VERSION "dbc-export 1 2026.26.6.5"

NS_ :

BS_:

BU_: APP APS BMS CC CMP CMPD CP DAS DI DIF DIR EPBL EPBR EVSE FC GTW HCML HCMR HVP ICR PCS PCS2 PLG PM PMF PMR PTC SCCM SCM SCS SDCR TAS UMC V2G VC VCBATT VCBATT0 VCBATT1 VCBATT2 VCFRONT VCFRONT1 VCFRONT2 VCLEFT VCRIGHT VCSEAT2L VCSEAT2R VCSEC

BO_ 963 VCRIGHT_switchStatus: 8 VCRIGHT
 SG_ VCRIGHT_switchStatusIndex M : 0|1@1+ (1,0) [0|1] "" Vector__XXX
 SG_ VCRIGHT_btnWindowUpRF : 24|1@1+ (1,0) [0|1] "" Vector__XXX
 SG_ VCRIGHT_btnWindowAutoUpRF : 25|1@1+ (1,0) [0|1] "" Vector__XXX
 SG_ VCRIGHT_btnWindowDownRF : 26|1@1+ (1,0) [0|1] "" Vector__XXX
 SG_ VCRIGHT_btnWindowAutoDownRF : 27|1@1+ (1,0) [0|1] "" Vector__XXX
 SG_ VCRIGHT_btnWindowUpRR : 28|1@1+ (1,0) [0|1] "" Vector__XXX
 SG_ VCRIGHT_btnWindowAutoUpRR : 29|1@1+ (1,0) [0|1] "" Vector__XXX
 SG_ VCRIGHT_btnWindowDownRR : 30|1@1+ (1,0) [0|1] "" Vector__XXX
 SG_ VCRIGHT_btnWindowAutoDownRR : 31|1@1+ (1,0) [0|1] "" Vector__XXX
 SG_ VCRIGHT_btnWindowSwPackUpLF : 32|1@1+ (1,0) [0|1] "" Vector__XXX
 SG_ VCRIGHT_btnWindowSwPackAutoUpLF : 33|1@1+ (1,0) [0|1] "" Vector__XXX
 SG_ VCRIGHT_btnWindowSwPackDownLF : 34|1@1+ (1,0) [0|1] "" Vector__XXX
 SG_ VCRIGHT_btnWindowSwPackAutoDwnLF : 35|1@1+ (1,0) [0|1] "" Vector__XXX
 SG_ VCRIGHT_btnWindowSwPackUpLR : 36|1@1+ (1,0) [0|1] "" Vector__XXX
 SG_ VCRIGHT_btnWindowSwPackAutoUpLR : 37|1@1+ (1,0) [0|1] "" Vector__XXX
 SG_ VCRIGHT_btnWindowSwPackDownLR : 38|1@1+ (1,0) [0|1] "" Vector__XXX
 SG_ VCRIGHT_btnWindowSwPackAutoDwnLR : 39|1@1+ (1,0) [0|1] "" Vector__XXX
 SG_ VCRIGHT_frontOccupancySwitch : 42|2@1+ (1,0) [0|3] "" Vector__XXX
 SG_ VCRIGHT_trunkExtReleasePressed : 48|1@1+ (1,0) [0|1] "" Vector__XXX
 SG_ VCRIGHT_btnWindowSwPackUpRR : 49|1@1+ (1,0) [0|1] "" Vector__XXX
 SG_ VCRIGHT_btnWindowSwPackAutoUpRR : 50|1@1+ (1,0) [0|1] "" Vector__XXX
 SG_ VCRIGHT_btnWindowSwPackDownRR : 51|1@1+ (1,0) [0|1] "" Vector__XXX
 SG_ VCRIGHT_btnWindowSwPackAutoDwnRR : 52|1@1+ (1,0) [0|1] "" Vector__XXX
 SG_ VCRIGHT_frontBuckleSwitch m0 : 40|2@1+ (1,0) [0|3] "" Vector__XXX
 SG_ VCRIGHT_rearCenterBuckleSwitch m0 : 44|2@1+ (1,0) [0|3] "" Vector__XXX
 SG_ VCRIGHT_rearRightBuckleSwitch m0 : 46|2@1+ (1,0) [0|3] "" Vector__XXX
 SG_ VCRIGHT_trunkExtReleasePressedPe m1 : 1|1@1+ (1,0) [0|1] "" Vector__XXX
 SG_ VCRIGHT_frontSeatTrackBack m1 : 2|2@1+ (1,0) [1|3] "" Vector__XXX
 SG_ VCRIGHT_frontSeatTrackForward m1 : 4|2@1+ (1,0) [1|3] "" Vector__XXX
 SG_ VCRIGHT_frontSeatTiltDown m1 : 6|2@1+ (1,0) [1|3] "" Vector__XXX
 SG_ VCRIGHT_frontSeatTiltUp m1 : 8|2@1+ (1,0) [1|3] "" Vector__XXX
 SG_ VCRIGHT_frontSeatLiftDown m1 : 10|2@1+ (1,0) [1|3] "" Vector__XXX
 SG_ VCRIGHT_frontSeatLiftUp m1 : 12|2@1+ (1,0) [1|3] "" Vector__XXX
 SG_ VCRIGHT_frontSeatBackrestBack m1 : 14|2@1+ (1,0) [1|3] "" Vector__XXX
 SG_ VCRIGHT_frontSeatBackrestForward m1 : 16|2@1+ (1,0) [1|3] "" Vector__XXX
 SG_ VCRIGHT_frontSeatLumbarDown m1 : 18|2@1+ (1,0) [1|3] "" Vector__XXX
 SG_ VCRIGHT_frontSeatLumbarUp m1 : 20|2@1+ (1,0) [1|3] "" Vector__XXX
 SG_ VCRIGHT_frontSeatLumbarIn m1 : 22|2@1+ (1,0) [1|3] "" Vector__XXX
 SG_ VCRIGHT_frontSeatResistiveOccupa m1 : 54|2@1+ (1,0) [1|3] "" Vector__XXX
 SG_ VCRIGHT_2RowSeatReclineSwitchpac m1 : 56|3@1+ (1,0) [0|7] "" Vector__XXX
 SG_ VCRIGHT_hvacHeatingAllowedRight m1 : 59|1@1+ (1,0) [0|1] "" Vector__XXX
 SG_ VCRIGHT_frontSeatThighSupportRet m1 : 60|2@1+ (1,0) [1|3] "" Vector__XXX

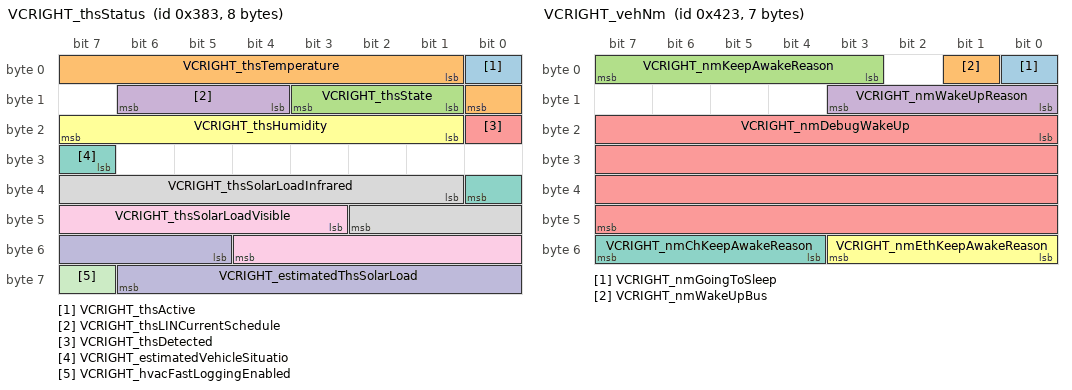
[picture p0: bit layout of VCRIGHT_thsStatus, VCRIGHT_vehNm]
BO_ 899 VCRIGHT_thsStatus: 8 VCRIGHT
 SG_ VCRIGHT_thsActive : 0|1@1+ (1,0) [0|1] "" Vector__XXX
 SG_ VCRIGHT_thsTemperature : 1|8@1+ (1,-40) [-40|150] "degC" Vector__XXX
 SG_ VCRIGHT_thsState : 9|3@1+ (1,0) [0|7] "" Vector__XXX
 SG_ VCRIGHT_thsLINCurrentSchedule : 12|3@1+ (1,0) [0|7] "" Vector__XXX
 SG_ VCRIGHT_thsDetected : 16|1@1+ (1,0) [0|1] "" Vector__XXX
 SG_ VCRIGHT_thsHumidity : 17|7@1+ (1,0) [0|100] "%" Vector__XXX
 SG_ VCRIGHT_estimatedVehicleSituatio : 31|2@1+ (1,0) [0|3] "" Vector__XXX
 SG_ VCRIGHT_thsSolarLoadInfrared : 33|10@1+ (2,0) [0|2044] "W/m2" Vector__XXX
 SG_ VCRIGHT_thsSolarLoadVisible : 43|10@1+ (2,0) [0|2044] "W/m2" Vector__XXX
 SG_ VCRIGHT_estimatedThsSolarLoad : 53|10@1+ (1,0) [0|1022] "W/m2" Vector__XXX
 SG_ VCRIGHT_hvacFastLoggingEnabled : 63|1@1+ (1,0) [0|1] "" Vector__XXX

BO_ 1545 VCRIGHT_udsResponse: 8 VCRIGHT
 SG_ VCRIGHT_udsResponseData_H : 7|32@0+ (1,0) [0|4294967295] "" Vector__XXX
 SG_ VCRIGHT_udsResponseData_L : 39|32@0+ (1,0) [0|4294967295] "" Vector__XXX

BO_ 1059 VCRIGHT_vehNm: 7 VCRIGHT
 SG_ VCRIGHT_nmGoingToSleep : 0|1@1+ (1,0) [0|1] "" Vector__XXX
 SG_ VCRIGHT_nmWakeUpBus : 1|1@1+ (1,0) [0|1] "" Vector__XXX
 SG_ VCRIGHT_nmKeepAwakeReason : 3|5@1+ (1,0) [1|31] "" Vector__XXX
 SG_ VCRIGHT_nmWakeUpReason : 8|4@1+ (1,0) [0|15] "" Vector__XXX
 SG_ VCRIGHT_nmDebugWakeUp : 16|32@1+ (1,0) [0|4294967295] "" Vector__XXX
 SG_ VCRIGHT_nmEthKeepAwakeReason : 48|4@1+ (1,0) [1|15] "" Vector__XXX
 SG_ VCRIGHT_nmChKeepAwakeReason : 52|4@1+ (1,0) [1|15] "" Vector__XXX

BO_ 707 VCRIGHT_windowStatus: 8 VCRIGHT
 SG_ VCRIGHT_windowStatusIndex M : 0|1@1+ (1,0) [0|1] "" Vector__XXX
 SG_ VCRIGHT_windowStateRF m0 : 1|4@1+ (1,0) [0|15] "" Vector__XXX
 SG_ VCRIGHT_windowTrimClearMoveReque m0 : 5|2@1+ (1,0) [0|3] "" Vector__XXX
 SG_ VCRIGHT_windowDutyRF m0 : 8|6@1- (5,0) [-100|100] "%" Vector__XXX
 SG_ VCRIGHT_windowTrimClearActiveReq m0 : 14|2@1+ (1,0) [1|3] "" Vector__XXX
 SG_ VCRIGHT_windowCurrentRF m0 : 16|6@1- (0.5,0) [-15|15] "A" Vector__XXX
 SG_ VCRIGHT_windowPositionRF m0 : 22|9@1- (1.25,265) [-50|580] "mm" Vector__XXX
 SG_ VCRIGHT_windowCalibratedRF m0 : 32|1@1+ (1,0) [0|1] "" Vector__XXX
 SG_ VCRIGHT_windowStateRR m0 : 33|4@1+ (1,0) [0|15] "" Vector__XXX
 SG_ VCRIGHT_windowDutyRR m0 : 40|6@1- (5,0) [-100|100] "%" Vector__XXX
 SG_ VCRIGHT_windowCurrentRR m0 : 48|6@1- (0.5,0) [-15|15] "A" Vector__XXX
 SG_ VCRIGHT_windowPositionRR m0 : 54|9@1- (1.25,265) [-50|580] "mm" Vector__XXX
 SG_ VCRIGHT_windowCalibratedRR m0 : 63|1@1+ (1,0) [0|1] "" Vector__XXX
 SG_ VCRIGHT_windowThermalTCRF m1 : 1|8@1+ (1,0) [0|255] "s" Vector__XXX
 SG_ VCRIGHT_windowThermalModeRF m1 : 9|2@1+ (1,0) [1|3] "" Vector__XXX
 SG_ VCRIGHT_windowStopReasonRF m1 : 11|3@1+ (1,0) [0|7] "" Vector__XXX
 SG_ VCRIGHT_windowStopReqReasonRF m1 : 14|4@1+ (1,0) [0|15] "" Vector__XXX
 SG_ VCRIGHT_windowThermalTCRR m1 : 18|8@1+ (1,0) [0|255] "s" Vector__XXX
 SG_ VCRIGHT_windowThermalModeRR m1 : 26|2@1+ (1,0) [1|3] "" Vector__XXX
 SG_ VCRIGHT_windowStopReasonRR m1 : 28|3@1+ (1,0) [0|7] "" Vector__XXX
 SG_ VCRIGHT_windowStopReqReasonRR m1 : 31|4@1+ (1,0) [0|15] "" Vector__XXX
 SG_ VCRIGHT_windowControlStateRF m1 : 35|2@1+ (1,0) [0|3] "" Vector__XXX
 SG_ VCRIGHT_windowCtrlUnavailableRF m1 : 38|3@1+ (1,0) [0|7] "" Vector__XXX
 SG_ VCRIGHT_windowControlStateRR m1 : 42|2@1+ (1,0) [0|3] "" Vector__XXX
 SG_ VCRIGHT_windowCtrlUnavailableRR m1 : 45|3@1+ (1,0) [0|7] "" Vector__XXX
 SG_ VCRIGHT_windowPositionStateRF m1 : 49|3@1+ (1,0) [0|7] "" Vector__XXX
 SG_ VCRIGHT_windowPositionStateRR m1 : 52|3@1+ (1,0) [0|7] "" Vector__XXX
 SG_ VCRIGHT_windowVehGearStateRF m1 : 56|2@1+ (1,0) [1|3] "" Vector__XXX
 SG_ VCRIGHT_windowVehGearStateRR m1 : 58|2@1+ (1,0) [1|3] "" Vector__XXX
 SG_ VCRIGHT_windowSpeedTableStatusRF m1 : 60|2@1+ (1,0) [1|3] "" Vector__XXX
 SG_ VCRIGHT_windowSpeedTableStatusRR m1 : 62|2@1+ (1,0) [1|3] "" Vector__XXX

BO_ 1375 VCSEAT2L_alertLog: 8 VCSEAT2L
 SG_ VCSEAT2L_alertID M : 0|15@1+ (1,0) [0|32767] "" Vector__XXX
 SG_ VCSEAT2L_alertState : 15|1@1+ (1,0) [0|1] "" Vector__XXX
 SG_ VCSEAT2L_a001_InternalWatchdog m1 : 16|1@1+ (1,0) [0|1] "" Vector__XXX
 SG_ VCSEAT2L_a010_UnderVoltDetected m10 : 16|1@1+ (1,0) [0|1] "" Vector__XXX
 SG_ VCSEAT2L_a010_UnderVoltTimeout m10 : 17|1@1+ (1,0) [0|1] "" Vector__XXX
 SG_ VCSEAT2L_a015_NVMMMemOverflow m15 : 16|1@1+ (1,0) [0|1] "" Vector__XXX
 SG_ VCSEAT2L_a015_NVMMFilesystemErro m15 : 17|1@1+ (1,0) [0|1] "" Vector__XXX
 SG_ VCSEAT2L_a015_NVMMRecordIDError m15 : 18|1@1+ (1,0) [0|1] "" Vector__XXX
 SG_ VCSEAT2L_a057_VEH_cpControl m57 : 16|1@1+ (1,0) [0|1] "" Vector__XXX
 SG_ VCSEAT2L_a059_voltageDrop m59 : 16|12@1+ (0.005443676,0) [0|22.29185322] "V" Vector__XXX
 SG_ VCSEAT2L_a059_resistanceEstimate m59 : 28|12@1+ (0.00244,0) [0|9.9918] "Ohms" Vector__XXX
 SG_ VCSEAT2L_a059_current m59 : 40|12@1+ (0.05,0) [0|204.75] "A" Vector__XXX
 SG_ VCSEAT2L_a063_switchChannel m63 : 16|8@1+ (1,0) [0|255] "" Vector__XXX
 SG_ VCSEAT2L_a063_switchType m63 : 24|8@1+ (1,0) [0|255] "" Vector__XXX
 SG_ VCSEAT2L_a063_ADCVoltage m63 : 32|8@1+ (0.025,0) [0|6.375] "V" Vector__XXX
 SG_ VCSEAT2L_a063_disconnected m63 : 40|1@1+ (1,0) [0|1] "" Vector__XXX
 SG_ VCSEAT2L_a063_indeterminate m63 : 41|1@1+ (1,0) [0|1] "" Vector__XXX
 SG_ VCSEAT2L_a063_stuckActive m63 : 42|1@1+ (1,0) [0|1] "" Vector__XXX
 SG_ VCSEAT2L_a063_faulted m63 : 43|1@1+ (1,0) [0|1] "" Vector__XXX
 SG_ VCSEAT2L_a082_RIPC_epbPrivateSta m82 : 16|1@1+ (1,0) [0|1] "" Vector__XXX
 SG_ VCSEAT2L_a082_RIPC_remoteHSD m82 : 17|1@1+ (1,0) [0|1] "" Vector__XXX
 SG_ VCSEAT2L_a082_RIPC_railStatus m82 : 18|1@1+ (1,0) [0|1] "" Vector__XXX
 SG_ VCSEAT2L_a082_RIPC_remoteMux m82 : 19|1@1+ (1,0) [0|1] "" Vector__XXX
 SG_ VCSEAT2L_a083_LIPC_epbPrivateSta m83 : 16|1@1+ (1,0) [0|1] "" Vector__XXX
 SG_ VCSEAT2L_a083_LIPC_remoteHSD m83 : 17|1@1+ (1,0) [0|1] "" Vector__XXX
 SG_ VCSEAT2L_a083_LIPC_railStatus m83 : 18|1@1+ (1,0) [0|1] "" Vector__XXX
 SG_ VCSEAT2L_a083_LIPC_HSDFaults m83 : 19|1@1+ (1,0) [0|1] "" Vector__XXX
 SG_ VCSEAT2L_a084_CH_StatusC m84 : 16|1@1+ (1,0) [0|1] "" Vector__XXX
 SG_ VCSEAT2L_a085_PARTY_buttonStatus m85 : 16|1@1+ (1,0) [0|1] "" Vector__XXX
 SG_ VCSEAT2L_a086_VEH_LVBMS_statusHi m86 : 16|1@1+ (1,0) [0|1] "" Vector__XXX
 SG_ VCSEAT2L_a086_VEH_LVBMS_statusLo m86 : 17|1@1+ (1,0) [0|1] "" Vector__XXX
 SG_ VCSEAT2L_a086_VEH_status m86 : 18|1@1+ (1,0) [0|1] "" Vector__XXX
 SG_ VCSEAT2L_a086_VEH_12VBatteryStat m86 : 19|1@1+ (1,0) [0|1] "" Vector__XXX
 SG_ VCSEAT2L_a086_VEH_LVPowerState m86 : 20|1@1+ (1,0) [0|1] "" Vector__XXX
 SG_ VCSEAT2L_a086_VEH_lightStatus m86 : 21|1@1+ (1,0) [0|1] "" Vector__XXX
 SG_ VCSEAT2L_a086_VEH_systemStatus m86 : 22|1@1+ (1,0) [0|1] "" Vector__XXX
 SG_ VCSEAT2L_a086_VEH_thermalStatus m86 : 23|1@1+ (1,0) [0|1] "" Vector__XXX
 SG_ VCSEAT2L_a086_VEH_vehNm m86 : 24|1@1+ (1,0) [0|1] "" Vector__XXX
 SG_ VCSEAT2L_a087_VEH_temperature m87 : 16|1@1+ (1,0) [0|1] "" Vector__XXX
 SG_ VCSEAT2L_a087_VEH_thermalControl m87 : 17|1@1+ (1,0) [0|1] "" Vector__XXX
 SG_ VCSEAT2L_a087_VEH_torque m87 : 18|1@1+ (1,0) [0|1] "" Vector__XXX
 SG_ VCSEAT2L_a087_VEH_status m87 : 19|1@1+ (1,0) [0|1] "" Vector__XXX
 SG_ VCSEAT2L_a087_PARTY_torque m87 : 20|1@1+ (1,0) [0|1] "" Vector__XXX
 SG_ VCSEAT2L_a087_PARTY_status m87 : 21|1@1+ (1,0) [0|1] "" Vector__XXX
 SG_ VCSEAT2L_a087_PARTY_temperature m87 : 22|1@1+ (1,0) [0|1] "" Vector__XXX
 SG_ VCSEAT2L_a087_PARTY_thermalContr m87 : 23|1@1+ (1,0) [0|1] "" Vector__XXX
 SG_ VCSEAT2L_a087_VEH_motorStatus m87 : 24|1@1+ (1,0) [0|1] "" Vector__XXX
 SG_ VCSEAT2L_a088_VEH_temperature m88 : 16|1@1+ (1,0) [0|1] "" Vector__XXX
 SG_ VCSEAT2L_a088_VEH_thermalControl m88 : 17|1@1+ (1,0) [0|1] "" Vector__XXX
 SG_ VCSEAT2L_a088_VEH_torque m88 : 18|1@1+ (1,0) [0|1] "" Vector__XXX
 SG_ VCSEAT2L_a088_VEH_status m88 : 19|1@1+ (1,0) [0|1] "" Vector__XXX
 SG_ VCSEAT2L_a088_PARTY_torque m88 : 20|1@1+ (1,0) [0|1] "" Vector__XXX
 SG_ VCSEAT2L_a088_PARTY_status m88 : 21|1@1+ (1,0) [0|1] "" Vector__XXX
 SG_ VCSEAT2L_a088_PARTY_temperature m88 : 22|1@1+ (1,0) [0|1] "" Vector__XXX
 SG_ VCSEAT2L_a088_PARTY_thermalContr m88 : 23|1@1+ (1,0) [0|1] "" Vector__XXX
 SG_ VCSEAT2L_a088_VEH_motorStatus m88 : 24|1@1+ (1,0) [0|1] "" Vector__XXX
 SG_ VCSEAT2L_a089_PARTY_party1 m89 : 16|1@1+ (1,0) [0|1] "" Vector__XXX
 SG_ VCSEAT2L_a089_PARTY_status m89 : 17|1@1+ (1,0) [0|1] "" Vector__XXX
 SG_ VCSEAT2L_a089_VEH_status m89 : 18|1@1+ (1,0) [0|1] "" Vector__XXX
 SG_ VCSEAT2L_a089_BDY_party1 m89 : 19|1@1+ (1,0) [0|1] "" Vector__XXX
 SG_ VCSEAT2L_a089_BDY_status m89 : 20|1@1+ (1,0) [0|1] "" Vector__XXX
 SG_ VCSEAT2L_a089_CH_status m89 : 21|1@1+ (1,0) [0|1] "" Vector__XXX
 SG_ VCSEAT2L_a089_CH_party1 m89 : 22|1@1+ (1,0) [0|1] "" Vector__XXX
 SG_ VCSEAT2L_a089_CH_party3 m89 : 23|1@1+ (1,0) [0|1] "" Vector__XXX
 SG_ VCSEAT2L_a089_VEH_party1 m89 : 24|1@1+ (1,0) [0|1] "" Vector__XXX
 SG_ VCSEAT2L_a089_VEH_party3 m89 : 25|1@1+ (1,0) [0|1] "" Vector__XXX
 SG_ VCSEAT2L_a091_VEH_faultsAndExtra m91 : 16|1@1+ (1,0) [0|1] "" Vector__XXX
 SG_ VCSEAT2L_a091_VEH_info m91 : 17|1@1+ (1,0) [0|1] "" Vector__XXX
 SG_ VCSEAT2L_a091_VEH_state m91 : 18|1@1+ (1,0) [0|1] "" Vector__XXX
 SG_ VCSEAT2L_a092_VEH_restraintStatu m92 : 16|1@1+ (1,0) [0|1] "" Vector__XXX
 SG_ VCSEAT2L_a092_VEH_switchStatus m92 : 17|1@1+ (1,0) [0|1] "" Vector__XXX
 SG_ VCSEAT2L_a092_VEH_seatStatus2 m92 : 18|1@1+ (1,0) [0|1] "" Vector__XXX
 SG_ VCSEAT2L_a092_VEH_vehNm m92 : 19|1@1+ (1,0) [0|1] "" Vector__XXX
 SG_ VCSEAT2L_a093_VEH_restraintStatu m93 : 16|1@1+ (1,0) [0|1] "" Vector__XXX
 SG_ VCSEAT2L_a093_VEH_switchStatus m93 : 17|1@1+ (1,0) [0|1] "" Vector__XXX
 SG_ VCSEAT2L_a093_VEH_seatStatus2 m93 : 18|1@1+ (1,0) [0|1] "" Vector__XXX
 SG_ VCSEAT2L_a093_VEH_vehNm m93 : 19|1@1+ (1,0) [0|1] "" Vector__XXX
 SG_ VCSEAT2L_a094_VEH_sysStatus m94 : 16|1@1+ (1,0) [0|1] "" Vector__XXX
 SG_ VCSEAT2L_a094_PARTY_sysStatus m94 : 17|1@1+ (1,0) [0|1] "" Vector__XXX
 SG_ VCSEAT2L_a094_CH_sysStatus m94 : 18|1@1+ (1,0) [0|1] "" Vector__XXX
 SG_ VCSEAT2L_a095_PT_ptNm m95 : 16|1@1+ (1,0) [0|1] "" Vector__XXX
 SG_ VCSEAT2L_a095_PT_status m95 : 17|1@1+ (1,0) [0|1] "" Vector__XXX
 SG_ VCSEAT2L_a096_VEH_status m96 : 16|1@1+ (1,0) [0|1] "" Vector__XXX
 SG_ VCSEAT2L_a096_CH_status m96 : 17|1@1+ (1,0) [0|1] "" Vector__XXX
 SG_ VCSEAT2L_a097_VEH_HVStatus m97 : 16|1@1+ (1,0) [0|1] "" Vector__XXX
 SG_ VCSEAT2L_a097_VEH_state m97 : 17|1@1+ (1,0) [0|1] "" Vector__XXX
 SG_ VCSEAT2L_a098_CH_torque m98 : 16|1@1+ (1,0) [0|1] "" Vector__XXX
 SG_ VCSEAT2L_a098_VEH_hvStatus m98 : 17|1@1+ (1,0) [0|1] "" Vector__XXX
 SG_ VCSEAT2L_a098_VEH_status m98 : 18|1@1+ (1,0) [0|1] "" Vector__XXX
 SG_ VCSEAT2L_a098_VEH_thermalControl m98 : 19|1@1+ (1,0) [0|1] "" Vector__XXX
 SG_ VCSEAT2L_a098_VEH_temperature m98 : 20|1@1+ (1,0) [0|1] "" Vector__XXX
 SG_ VCSEAT2L_a098_VEH_torque m98 : 21|1@1+ (1,0) [0|1] "" Vector__XXX
 SG_ VCSEAT2L_a098_PARTY_status m98 : 22|1@1+ (1,0) [0|1] "" Vector__XXX
 SG_ VCSEAT2L_a098_PARTY_temperature m98 : 23|1@1+ (1,0) [0|1] "" Vector__XXX
 SG_ VCSEAT2L_a098_PARTY_thermalContr m98 : 24|1@1+ (1,0) [0|1] "" Vector__XXX
 SG_ VCSEAT2L_a098_PARTY_torque m98 : 25|1@1+ (1,0) [0|1] "" Vector__XXX
 SG_ VCSEAT2L_a098_PT_thermalControl m98 : 26|1@1+ (1,0) [0|1] "" Vector__XXX
 SG_ VCSEAT2L_a098_PT_temperature m98 : 27|1@1+ (1,0) [0|1] "" Vector__XXX
 SG_ VCSEAT2L_a098_PARTY_motorStatus m98 : 28|1@1+ (1,0) [0|1] "" Vector__XXX
 SG_ VCSEAT2L_a098_VEH_motorStatus m98 : 29|1@1+ (1,0) [0|1] "" Vector__XXX
 SG_ VCSEAT2L_a099_VEH_oocStatus m99 : 16|1@1+ (1,0) [0|1] "" Vector__XXX
 SG_ VCSEAT2L_a100_VEH m100 : 16|1@1+ (1,0) [0|1] "" Vector__XXX
 SG_ VCSEAT2L_a100_PARTY m100 : 17|1@1+ (1,0) [0|1] "" Vector__XXX
 SG_ VCSEAT2L_a100_PT m100 : 18|1@1+ (1,0) [0|1] "" Vector__XXX
 SG_ VCSEAT2L_a100_CH m100 : 19|1@1+ (1,0) [0|1] "" Vector__XXX
 SG_ VCSEAT2L_a100_OBD m100 : 20|1@1+ (1,0) [0|1] "" Vector__XXX
 SG_ VCSEAT2L_a101_VEH_state m101 : 16|1@1+ (1,0) [0|1] "" Vector__XXX
 SG_ VCSEAT2L_a101_PARTY_locState m101 : 17|1@1+ (1,0) [0|1] "" Vector__XXX
 SG_ VCSEAT2L_a101_LIPC_externalWatch m101 : 18|1@1+ (1,0) [0|1] "" Vector__XXX
 SG_ VCSEAT2L_a101_VEH_locState m101 : 19|1@1+ (1,0) [0|1] "" Vector__XXX
 SG_ VCSEAT2L_a101_BDY_locState m101 : 20|1@1+ (1,0) [0|1] "" Vector__XXX
 SG_ VCSEAT2L_a102_VEH_faultsAndExtra m102 : 16|1@1+ (1,0) [0|1] "" Vector__XXX
 SG_ VCSEAT2L_a102_VEH_feedbackStatus m102 : 17|1@1+ (1,0) [0|1] "" Vector__XXX
 SG_ VCSEAT2L_a102_VEH_sensorStatus m102 : 18|1@1+ (1,0) [0|1] "" Vector__XXX
 SG_ VCSEAT2L_a102_VEH_rods m102 : 19|1@1+ (1,0) [0|1] "" Vector__XXX
 SG_ VCSEAT2L_a103_VEH_hvsNm m103 : 16|1@1+ (1,0) [0|1] "" Vector__XXX
 SG_ VCSEAT2L_a103_VEH_vehNm m103 : 17|1@1+ (1,0) [0|1] "" Vector__XXX
 SG_ VCSEAT2L_a103_VEH_status m103 : 18|1@1+ (1,0) [0|1] "" Vector__XXX
 SG_ VCSEAT2L_a103_PT_ptNm m103 : 19|1@1+ (1,0) [0|1] "" Vector__XXX
 SG_ VCSEAT2L_a103_PT_status m103 : 20|1@1+ (1,0) [0|1] "" Vector__XXX
 SG_ VCSEAT2L_a103_VEH_evseStatus m103 : 21|1@1+ (1,0) [0|1] "" Vector__XXX
 SG_ VCSEAT2L_a105_VEH_states m105 : 16|1@1+ (1,0) [0|1] "" Vector__XXX
 SG_ VCSEAT2L_a105_VEH_chNm m105 : 17|1@1+ (1,0) [0|1] "" Vector__XXX
 SG_ VCSEAT2L_a105_VEH_dampingStates m105 : 18|1@1+ (1,0) [0|1] "" Vector__XXX
 SG_ VCSEAT2L_a106_VEH_dcdcStatus m106 : 16|1@1+ (1,0) [0|1] "" Vector__XXX
 SG_ VCSEAT2L_a106_VEH_thermalControl m106 : 17|1@1+ (1,0) [0|1] "" Vector__XXX
 SG_ VCSEAT2L_a106_VEH_dcdcRailStatus m106 : 18|1@1+ (1,0) [0|1] "" Vector__XXX
 SG_ VCSEAT2L_a106_CH_dcdcRailStatus m106 : 19|1@1+ (1,0) [0|1] "" Vector__XXX
 SG_ VCSEAT2L_a106_CH_alertMatrix m106 : 20|1@1+ (1,0) [0|1] "" Vector__XXX
 SG_ VCSEAT2L_a107_VEH_hvsNm m107 : 16|1@1+ (1,0) [0|1] "" Vector__XXX
 SG_ VCSEAT2L_a107_VEH_vehNm m107 : 17|1@1+ (1,0) [0|1] "" Vector__XXX
 SG_ VCSEAT2L_a107_VEH_status m107 : 18|1@1+ (1,0) [0|1] "" Vector__XXX
 SG_ VCSEAT2L_a107_VEH_thermalStatus m107 : 19|1@1+ (1,0) [0|1] "" Vector__XXX
 SG_ VCSEAT2L_a107_VEH_bmbMinMax m107 : 20|1@1+ (1,0) [0|1] "" Vector__XXX
 SG_ VCSEAT2L_a107_VEH_powerAvailable m107 : 21|1@1+ (1,0) [0|1] "" Vector__XXX
 SG_ VCSEAT2L_a107_PT_ptNm m107 : 22|1@1+ (1,0) [0|1] "" Vector__XXX
 SG_ VCSEAT2L_a107_PT_status m107 : 23|1@1+ (1,0) [0|1] "" Vector__XXX
 SG_ VCSEAT2L_a107_PT_thermalStatus m107 : 24|1@1+ (1,0) [0|1] "" Vector__XXX
 SG_ VCSEAT2L_a107_PT_socStatus m107 : 25|1@1+ (1,0) [0|1] "" Vector__XXX
 SG_ VCSEAT2L_a107_VEH_socStatus m107 : 26|1@1+ (1,0) [0|1] "" Vector__XXX
 SG_ VCSEAT2L_a107_VEH_packConfig m107 : 27|1@1+ (1,0) [0|1] "" Vector__XXX
 SG_ VCSEAT2L_a107_VEH_energyStatus m107 : 28|1@1+ (1,0) [0|1] "" Vector__XXX
 SG_ VCSEAT2L_a107_VEH_chargeInfo m107 : 29|1@1+ (1,0) [0|1] "" Vector__XXX
 SG_ VCSEAT2L_a108_VEH_hvStatus m108 : 16|1@1+ (1,0) [0|1] "" Vector__XXX
 SG_ VCSEAT2L_a108_VEH_temperature m108 : 17|1@1+ (1,0) [0|1] "" Vector__XXX
 SG_ VCSEAT2L_a108_VEH_thermalControl m108 : 18|1@1+ (1,0) [0|1] "" Vector__XXX
 SG_ VCSEAT2L_a108_VEH_torque m108 : 19|1@1+ (1,0) [0|1] "" Vector__XXX
 SG_ VCSEAT2L_a108_VEH_status m108 : 20|1@1+ (1,0) [0|1] "" Vector__XXX
 SG_ VCSEAT2L_a108_PARTY_torque m108 : 21|1@1+ (1,0) [0|1] "" Vector__XXX
 SG_ VCSEAT2L_a108_PARTY_status m108 : 22|1@1+ (1,0) [0|1] "" Vector__XXX
 SG_ VCSEAT2L_a108_PARTY_temperature m108 : 23|1@1+ (1,0) [0|1] "" Vector__XXX
 SG_ VCSEAT2L_a108_PARTY_thermalContr m108 : 24|1@1+ (1,0) [0|1] "" Vector__XXX
 SG_ VCSEAT2L_a108_PT_temperature m108 : 25|1@1+ (1,0) [0|1] "" Vector__XXX
 SG_ VCSEAT2L_a108_PT_thermalControl m108 : 26|1@1+ (1,0) [0|1] "" Vector__XXX
 SG_ VCSEAT2L_a108_PARTY_motorStatus m108 : 27|1@1+ (1,0) [0|1] "" Vector__XXX
 SG_ VCSEAT2L_a108_VEH_motorStatus m108 : 28|1@1+ (1,0) [0|1] "" Vector__XXX
 SG_ VCSEAT2L_a108_CH_torque m108 : 29|1@1+ (1,0) [0|1] "" Vector__XXX
 SG_ VCSEAT2L_a110_VEH_carState m110 : 16|1@1+ (1,0) [0|1] "" Vector__XXX
 SG_ VCSEAT2L_a110_VEH_carConfig m110 : 17|1@1+ (1,0) [0|1] "" Vector__XXX
 SG_ VCSEAT2L_a110_VEH_time m110 : 18|1@1+ (1,0) [0|1] "" Vector__XXX
 SG_ VCSEAT2L_a110_VEH_updateStatus m110 : 19|1@1+ (1,0) [0|1] "" Vector__XXX
 SG_ VCSEAT2L_a110_VEH_vehNm m110 : 20|1@1+ (1,0) [0|1] "" Vector__XXX
 SG_ VCSEAT2L_a110_VEH_mismatchFault m110 : 21|1@1+ (1,0) [0|1] "" Vector__XXX
 SG_ VCSEAT2L_a110_VEH_vin m110 : 22|1@1+ (1,0) [0|1] "" Vector__XXX
 SG_ VCSEAT2L_a110_VEH_bmpDebug m110 : 23|1@1+ (1,0) [0|1] "" Vector__XXX
 SG_ VCSEAT2L_a110_VEH_gearControl m110 : 24|1@1+ (1,0) [0|1] "" Vector__XXX
 SG_ VCSEAT2L_a110_VEH_canLogAvailabi m110 : 25|1@1+ (1,0) [0|1] "" Vector__XXX
 SG_ VCSEAT2L_a110_CH_airbagCutoffSta m110 : 26|1@1+ (1,0) [0|1] "" Vector__XXX
 SG_ VCSEAT2L_a110_CH_carConfig m110 : 27|1@1+ (1,0) [0|1] "" Vector__XXX
 SG_ VCSEAT2L_a110_CH_carState m110 : 28|1@1+ (1,0) [0|1] "" Vector__XXX
 SG_ VCSEAT2L_a110_CH_vin m110 : 29|1@1+ (1,0) [0|1] "" Vector__XXX
 SG_ VCSEAT2L_a110_CH_chNm m110 : 30|1@1+ (1,0) [0|1] "" Vector__XXX
 SG_ VCSEAT2L_a110_CH_epochTimeGtw m110 : 31|1@1+ (1,0) [0|1] "" Vector__XXX
 SG_ VCSEAT2L_a110_PARTY_carConfig m110 : 32|1@1+ (1,0) [0|1] "" Vector__XXX
 SG_ VCSEAT2L_a111_VEH_internalStatus m111 : 16|1@1+ (1,0) [0|1] "" Vector__XXX
 SG_ VCSEAT2L_a111_VEH_status m111 : 17|1@1+ (1,0) [0|1] "" Vector__XXX
 SG_ VCSEAT2L_a111_VEH_vehNm m111 : 18|1@1+ (1,0) [0|1] "" Vector__XXX
 SG_ VCSEAT2L_a111_RIPC_LVPowerState m111 : 19|1@1+ (1,0) [0|1] "" Vector__XXX
 SG_ VCSEAT2L_a111_RIPC_epbPrivateSta m111 : 20|1@1+ (1,0) [0|1] "" Vector__XXX
 SG_ VCSEAT2L_a111_RIPC_railStatus m111 : 21|1@1+ (1,0) [0|1] "" Vector__XXX
 SG_ VCSEAT2L_a111_RIPC_remoteADC m111 : 22|1@1+ (1,0) [0|1] "" Vector__XXX
 SG_ VCSEAT2L_a111_RIPC_switchStatus m111 : 23|1@1+ (1,0) [0|1] "" Vector__XXX
 SG_ VCSEAT2L_a111_VEH_LVPowerState m111 : 24|1@1+ (1,0) [0|1] "" Vector__XXX
 SG_ VCSEAT2L_a111_VEH_seatStatus m111 : 25|1@1+ (1,0) [0|1] "" Vector__XXX
 SG_ VCSEAT2L_a111_PARTY_status m111 : 26|1@1+ (1,0) [0|1] "" Vector__XXX
 SG_ VCSEAT2L_a111_CH_status m111 : 27|1@1+ (1,0) [0|1] "" Vector__XXX
 SG_ VCSEAT2L_a112_VEH_internalStatus m112 : 16|1@1+ (1,0) [0|1] "" Vector__XXX
 SG_ VCSEAT2L_a112_VEH_status m112 : 17|1@1+ (1,0) [0|1] "" Vector__XXX
 SG_ VCSEAT2L_a112_VEH_vehNm m112 : 18|1@1+ (1,0) [0|1] "" Vector__XXX
 SG_ VCSEAT2L_a112_LIPC_LVPowerState m112 : 19|1@1+ (1,0) [0|1] "" Vector__XXX
 SG_ VCSEAT2L_a112_LIPC_epbPrivateSta m112 : 20|1@1+ (1,0) [0|1] "" Vector__XXX
 SG_ VCSEAT2L_a112_LIPC_railStatus m112 : 21|1@1+ (1,0) [0|1] "" Vector__XXX
 SG_ VCSEAT2L_a112_LIPC_remoteADC m112 : 22|1@1+ (1,0) [0|1] "" Vector__XXX
 SG_ VCSEAT2L_a112_LIPC_switchStatus m112 : 23|1@1+ (1,0) [0|1] "" Vector__XXX
 SG_ VCSEAT2L_a112_VEH_LVPowerState m112 : 24|1@1+ (1,0) [0|1] "" Vector__XXX
 SG_ VCSEAT2L_a112_PARTY_status m112 : 25|1@1+ (1,0) [0|1] "" Vector__XXX
 SG_ VCSEAT2L_a112_CH_status m112 : 26|1@1+ (1,0) [0|1] "" Vector__XXX
 SG_ VCSEAT2L_a114_PARTY_status m114 : 16|1@1+ (1,0) [0|1] "" Vector__XXX
 SG_ VCSEAT2L_a114_PARTY_wheelSpeeds m114 : 17|1@1+ (1,0) [0|1] "" Vector__XXX
 SG_ VCSEAT2L_a114_VEH_wheelSpeeds m114 : 18|1@1+ (1,0) [0|1] "" Vector__XXX
 SG_ VCSEAT2L_a114_CH_wheelSpeeds m114 : 19|1@1+ (1,0) [0|1] "" Vector__XXX
 SG_ VCSEAT2L_a114_PARTY_party3 m114 : 20|1@1+ (1,0) [0|1] "" Vector__XXX
 SG_ VCSEAT2L_a114_VEH_party3 m114 : 21|1@1+ (1,0) [0|1] "" Vector__XXX
 SG_ VCSEAT2L_a114_VEH_status m114 : 22|1@1+ (1,0) [0|1] "" Vector__XXX
 SG_ VCSEAT2L_a114_PARTY_wheelRotatio m114 : 23|1@1+ (1,0) [0|1] "" Vector__XXX
 SG_ VCSEAT2L_a114_CH_wheelRotation m114 : 24|1@1+ (1,0) [0|1] "" Vector__XXX
 SG_ VCSEAT2L_a114_VEH_wheelRotation m114 : 25|1@1+ (1,0) [0|1] "" Vector__XXX
 SG_ VCSEAT2L_a114_PARTY_brakeTorque m114 : 26|1@1+ (1,0) [0|1] "" Vector__XXX
 SG_ VCSEAT2L_a114_PARTY_offsets m114 : 27|1@1+ (1,0) [0|1] "" Vector__XXX
 SG_ VCSEAT2L_a114_BDY_offsets m114 : 28|1@1+ (1,0) [0|1] "" Vector__XXX
 SG_ VCSEAT2L_a114_BDY_party3 m114 : 29|1@1+ (1,0) [0|1] "" Vector__XXX
 SG_ VCSEAT2L_a114_BDY_status m114 : 30|1@1+ (1,0) [0|1] "" Vector__XXX
 SG_ VCSEAT2L_a114_BDY_wheelRotation m114 : 31|1@1+ (1,0) [0|1] "" Vector__XXX
 SG_ VCSEAT2L_a114_BDY_wheelSpeeds m114 : 32|1@1+ (1,0) [0|1] "" Vector__XXX
 SG_ VCSEAT2L_a114_CH_party1 m114 : 33|1@1+ (1,0) [0|1] "" Vector__XXX
 SG_ VCSEAT2L_a114_CH_party3 m114 : 34|1@1+ (1,0) [0|1] "" Vector__XXX
 SG_ VCSEAT2L_a114_CH_status m114 : 35|1@1+ (1,0) [0|1] "" Vector__XXX
 SG_ VCSEAT2L_a115_VEH_vehNm m115 : 16|1@1+ (1,0) [0|1] "" Vector__XXX
 SG_ VCSEAT2L_a115_VEH_authentication m115 : 17|1@1+ (1,0) [0|1] "" Vector__XXX
 SG_ VCSEAT2L_a115_VEH_BLEResetReques m115 : 18|1@1+ (1,0) [0|1] "" Vector__XXX
 SG_ VCSEAT2L_a115_VEH_requests m115 : 19|1@1+ (1,0) [0|1] "" Vector__XXX
 SG_ VCSEAT2L_a115_VEH_requests2 m115 : 20|1@1+ (1,0) [0|1] "" Vector__XXX
 SG_ VCSEAT2L_a115_REM_authentication m115 : 21|1@1+ (1,0) [0|1] "" Vector__XXX
 SG_ VCSEAT2L_a115_UI_corianderVehicl m115 : 22|1@1+ (1,0) [0|1] "" Vector__XXX
 SG_ VCSEAT2L_a115_CH_TPMSDisplay m115 : 23|1@1+ (1,0) [0|1] "" Vector__XXX
 SG_ VCSEAT2L_a116_PARTY_epbmStatus m116 : 16|1@1+ (1,0) [0|1] "" Vector__XXX
 SG_ VCSEAT2L_a116_VEH_vehNm m116 : 17|1@1+ (1,0) [0|1] "" Vector__XXX
 SG_ VCSEAT2L_a116_VEH_hvacRequest m116 : 18|1@1+ (1,0) [0|1] "" Vector__XXX
 SG_ VCSEAT2L_a116_VEH_hvacStatus m116 : 19|1@1+ (1,0) [0|1] "" Vector__XXX
 SG_ VCSEAT2L_a116_VEH_LVPowerState m116 : 20|1@1+ (1,0) [0|1] "" Vector__XXX
 SG_ VCSEAT2L_a116_VEH_lightStatus m116 : 21|1@1+ (1,0) [0|1] "" Vector__XXX
 SG_ VCSEAT2L_a116_VEH_seatStatus m116 : 22|1@1+ (1,0) [0|1] "" Vector__XXX
 SG_ VCSEAT2L_a116_VEH_thsStatus m116 : 23|1@1+ (1,0) [0|1] "" Vector__XXX
 SG_ VCSEAT2L_a116_VEH_doorStatus m116 : 24|1@1+ (1,0) [0|1] "" Vector__XXX
 SG_ VCSEAT2L_a116_VEH_seatHeatStatus m116 : 25|1@1+ (1,0) [0|1] "" Vector__XXX
 SG_ VCSEAT2L_a116_VEH_restraintStatu m116 : 26|1@1+ (1,0) [0|1] "" Vector__XXX
 SG_ VCSEAT2L_a116_VEH_switchStatus m116 : 27|1@1+ (1,0) [0|1] "" Vector__XXX
 SG_ VCSEAT2L_a116_VEH_logging1Hz m116 : 28|1@1+ (1,0) [0|1] "" Vector__XXX
 SG_ VCSEAT2L_a116_VEH_seatStatus2 m116 : 29|1@1+ (1,0) [0|1] "" Vector__XXX
 SG_ VCSEAT2L_a116_VEH_status m116 : 30|1@1+ (1,0) [0|1] "" Vector__XXX
 SG_ VCSEAT2L_a116_VEH_thermalCommand m116 : 31|1@1+ (1,0) [0|1] "" Vector__XXX
 SG_ VCSEAT2L_a116_VEH_windowStatus m116 : 32|1@1+ (1,0) [0|1] "" Vector__XXX
 SG_ VCSEAT2L_a116_PARTY_restraintSta m116 : 33|1@1+ (1,0) [0|1] "" Vector__XXX
 SG_ VCSEAT2L_a116_PARTY_doorStatus m116 : 34|1@1+ (1,0) [0|1] "" Vector__XXX
 SG_ VCSEAT2L_a116_BDY_epbmStatus m116 : 35|1@1+ (1,0) [0|1] "" Vector__XXX
 SG_ VCSEAT2L_a116_BDY_restraintStatu m116 : 36|1@1+ (1,0) [0|1] "" Vector__XXX
 SG_ VCSEAT2L_a116_BDY_switchStatus m116 : 37|1@1+ (1,0) [0|1] "" Vector__XXX
 SG_ VCSEAT2L_a117_BDY_epbmStatus m117 : 16|1@1+ (1,0) [0|1] "" Vector__XXX
 SG_ VCSEAT2L_a117_BDY_restraintStatu m117 : 17|1@1+ (1,0) [0|1] "" Vector__XXX
 SG_ VCSEAT2L_a117_VEH_prndStatus m117 : 18|1@1+ (1,0) [0|1] "" Vector__XXX
 SG_ VCSEAT2L_a117_PARTY_epbmStatus m117 : 19|1@1+ (1,0) [0|1] "" Vector__XXX
 SG_ VCSEAT2L_a117_VEH_vehNm m117 : 20|1@1+ (1,0) [0|1] "" Vector__XXX
 SG_ VCSEAT2L_a117_VEH_hvacBlowerFdb m117 : 21|1@1+ (1,0) [0|1] "" Vector__XXX
 SG_ VCSEAT2L_a117_VEH_LVPowerState m117 : 22|1@1+ (1,0) [0|1] "" Vector__XXX
 SG_ VCSEAT2L_a117_VEH_restraintStatu m117 : 23|1@1+ (1,0) [0|1] "" Vector__XXX
 SG_ VCSEAT2L_a117_VEH_lightStatus m117 : 24|1@1+ (1,0) [0|1] "" Vector__XXX
 SG_ VCSEAT2L_a117_VEH_seatStatus m117 : 25|1@1+ (1,0) [0|1] "" Vector__XXX
 SG_ VCSEAT2L_a117_BDY_falconSwitchSt m117 : 26|1@1+ (1,0) [0|1] "" Vector__XXX
 SG_ VCSEAT2L_a117_VEH_doorStatus m117 : 27|1@1+ (1,0) [0|1] "" Vector__XXX
 SG_ VCSEAT2L_a117_VEH_doorStatus2 m117 : 28|1@1+ (1,0) [0|1] "" Vector__XXX
 SG_ VCSEAT2L_a117_VEH_windowStatus m117 : 29|1@1+ (1,0) [0|1] "" Vector__XXX
 SG_ VCSEAT2L_a117_VEH_switchStatus m117 : 30|1@1+ (1,0) [0|1] "" Vector__XXX
 SG_ VCSEAT2L_a117_VEH_intrusionSenso m117 : 31|1@1+ (1,0) [0|1] "" Vector__XXX
 SG_ VCSEAT2L_a117_VEH_liftgateStatus m117 : 32|1@1+ (1,0) [0|1] "" Vector__XXX
 SG_ VCSEAT2L_a117_VEH_seatStatus2 m117 : 33|1@1+ (1,0) [0|1] "" Vector__XXX
 SG_ VCSEAT2L_a117_PARTY_restraintSta m117 : 34|1@1+ (1,0) [0|1] "" Vector__XXX
 SG_ VCSEAT2L_a117_VEH_thermalStatus m117 : 35|1@1+ (1,0) [0|1] "" Vector__XXX
 SG_ VCSEAT2L_a117_PARTY_doorStatus m117 : 36|1@1+ (1,0) [0|1] "" Vector__XXX
 SG_ VCSEAT2L_a117_VEH_status m117 : 37|1@1+ (1,0) [0|1] "" Vector__XXX
 SG_ VCSEAT2L_a117_PARTY_prndStatus m117 : 38|1@1+ (1,0) [0|1] "" Vector__XXX
 SG_ VCSEAT2L_a117_PARTY_lightingSeco m117 : 39|1@1+ (1,0) [0|1] "" Vector__XXX
 SG_ VCSEAT2L_a118_VEH_vehNm m118 : 16|1@1+ (1,0) [0|1] "" Vector__XXX
 SG_ VCSEAT2L_a118_VEH_lighting m118 : 17|1@1+ (1,0) [0|1] "" Vector__XXX
 SG_ VCSEAT2L_a118_VEH_sensors m118 : 18|1@1+ (1,0) [0|1] "" Vector__XXX
 SG_ VCSEAT2L_a118_VEH_status m118 : 19|1@1+ (1,0) [0|1] "" Vector__XXX
 SG_ VCSEAT2L_a118_VEH_okToUseHighPwr m118 : 20|1@1+ (1,0) [0|1] "" Vector__XXX
 SG_ VCSEAT2L_a118_VEH_LVPowerState m118 : 21|1@1+ (1,0) [0|1] "" Vector__XXX
 SG_ VCSEAT2L_a118_VEH_coolant m118 : 22|1@1+ (1,0) [0|1] "" Vector__XXX
 SG_ VCSEAT2L_a118_VEH_vehicleStatus m118 : 23|1@1+ (1,0) [0|1] "" Vector__XXX
 SG_ VCSEAT2L_a118_VEH_12VBatteryStat m118 : 24|1@1+ (1,0) [0|1] "" Vector__XXX
 SG_ VCSEAT2L_a118_VEH_systemStatus m118 : 25|1@1+ (1,0) [0|1] "" Vector__XXX
 SG_ VCSEAT2L_a118_PARTY_LVPowerState m118 : 26|1@1+ (1,0) [0|1] "" Vector__XXX
 SG_ VCSEAT2L_a118_PARTY_outputPowerS m118 : 27|1@1+ (1,0) [0|1] "" Vector__XXX
 SG_ VCSEAT2L_a118_PARTY_vehicleTime m118 : 28|1@1+ (1,0) [0|1] "" Vector__XXX
 SG_ VCSEAT2L_a118_VEH_thermalCommand m118 : 29|1@1+ (1,0) [0|1] "" Vector__XXX
 SG_ VCSEAT2L_a118_CH_LVPowerState m118 : 30|1@1+ (1,0) [0|1] "" Vector__XXX
 SG_ VCSEAT2L_a118_PARTY_sensors m118 : 31|1@1+ (1,0) [0|1] "" Vector__XXX
 SG_ VCSEAT2L_a118_CH_sensors m118 : 32|1@1+ (1,0) [0|1] "" Vector__XXX
 SG_ VCSEAT2L_a118_VEH_interNodeResis m118 : 33|1@1+ (1,0) [0|1] "" Vector__XXX
 SG_ VCSEAT2L_a118_CH_lighting m118 : 34|1@1+ (1,0) [0|1] "" Vector__XXX
 SG_ VCSEAT2L_a118_VEH_lightStatus m118 : 35|1@1+ (1,0) [0|1] "" Vector__XXX
 SG_ VCSEAT2L_a118_PARTY_vehNm m118 : 36|1@1+ (1,0) [0|1] "" Vector__XXX
 SG_ VCSEAT2L_a118_CH_12VBatteryStatu m118 : 37|1@1+ (1,0) [0|1] "" Vector__XXX
 SG_ VCSEAT2L_a118_CH_LVBMS_statusHig m118 : 38|1@1+ (1,0) [0|1] "" Vector__XXX
 SG_ VCSEAT2L_a118_CH_alertMatrix m118 : 39|1@1+ (1,0) [0|1] "" Vector__XXX
 SG_ VCSEAT2L_a118_BDY_outputPowerSta m118 : 40|1@1+ (1,0) [0|1] "" Vector__XXX
 SG_ VCSEAT2L_a118_BDY_vehicleTime m118 : 41|1@1+ (1,0) [0|1] "" Vector__XXX
 SG_ VCSEAT2L_a118_PARTY_AP_vehicleSt m118 : 42|1@1+ (1,0) [0|1] "" Vector__XXX
 SG_ VCSEAT2L_a118_BDY_AP_vehicleStat m118 : 43|1@1+ (1,0) [0|1] "" Vector__XXX
 SG_ VCSEAT2L_a118_PARTY_VCFRONT_came m118 : 44|1@1+ (1,0) [0|1] "" Vector__XXX
 SG_ VCSEAT2L_a119_VEH_steerAngle m119 : 16|1@1+ (1,0) [0|1] "" Vector__XXX
 SG_ VCSEAT2L_a119_VEH_leftStalk m119 : 17|1@1+ (1,0) [0|1] "" Vector__XXX
 SG_ VCSEAT2L_a119_VEH_rightStalk m119 : 18|1@1+ (1,0) [0|1] "" Vector__XXX
 SG_ VCSEAT2L_a119_PARTY_rightStalk m119 : 19|1@1+ (1,0) [0|1] "" Vector__XXX
 SG_ VCSEAT2L_a119_CH_steerAngle m119 : 20|1@1+ (1,0) [0|1] "" Vector__XXX
 SG_ VCSEAT2L_a119_PARTY_steerAngle m119 : 21|1@1+ (1,0) [0|1] "" Vector__XXX
 SG_ VCSEAT2L_a120_PARTY_chassisCntl m120 : 16|1@1+ (1,0) [0|1] "" Vector__XXX
 SG_ VCSEAT2L_a120_VEH_systemStatus m120 : 17|1@1+ (1,0) [0|1] "" Vector__XXX
 SG_ VCSEAT2L_a120_CH_chassisCntl m120 : 18|1@1+ (1,0) [0|1] "" Vector__XXX
 SG_ VCSEAT2L_a120_PARTY_systemStatus m120 : 19|1@1+ (1,0) [0|1] "" Vector__XXX
 SG_ VCSEAT2L_a120_PARTY_torque m120 : 20|1@1+ (1,0) [0|1] "" Vector__XXX
 SG_ VCSEAT2L_a120_VEH_torque m120 : 21|1@1+ (1,0) [0|1] "" Vector__XXX
 SG_ VCSEAT2L_a120_PARTY_locStatus m120 : 22|1@1+ (1,0) [0|1] "" Vector__XXX
 SG_ VCSEAT2L_a120_PARTY_speed m120 : 23|1@1+ (1,0) [0|1] "" Vector__XXX
 SG_ VCSEAT2L_a120_VEH_speed m120 : 24|1@1+ (1,0) [0|1] "" Vector__XXX
 SG_ VCSEAT2L_a120_PARTY_status m120 : 25|1@1+ (1,0) [0|1] "" Vector__XXX
 SG_ VCSEAT2L_a120_PT_speed m120 : 26|1@1+ (1,0) [0|1] "" Vector__XXX
 SG_ VCSEAT2L_a120_PT_systemStatus m120 : 27|1@1+ (1,0) [0|1] "" Vector__XXX
 SG_ VCSEAT2L_a120_PARTY_vehicleEstim m120 : 28|1@1+ (1,0) [0|1] "" Vector__XXX
 SG_ VCSEAT2L_a120_VEH_aggregatedAxle m120 : 29|1@1+ (1,0) [0|1] "" Vector__XXX
 SG_ VCSEAT2L_a120_PARTY_aggregatedAx m120 : 30|1@1+ (1,0) [0|1] "" Vector__XXX
 SG_ VCSEAT2L_a120_VEH_systemPower m120 : 31|1@1+ (1,0) [0|1] "" Vector__XXX
 SG_ VCSEAT2L_a120_PARTY_autonomyHeal m120 : 32|1@1+ (1,0) [0|1] "" Vector__XXX
 SG_ VCSEAT2L_a120_VEH_autonomyHealth m120 : 33|1@1+ (1,0) [0|1] "" Vector__XXX
 SG_ VCSEAT2L_a120_PT_systemPower m120 : 34|1@1+ (1,0) [0|1] "" Vector__XXX
 SG_ VCSEAT2L_a120_PARTY_stalklessInt m120 : 35|1@1+ (1,0) [0|1] "" Vector__XXX
 SG_ VCSEAT2L_a120_CH_speed m120 : 36|1@1+ (1,0) [0|1] "" Vector__XXX
 SG_ VCSEAT2L_a120_VEH_estimatedBrake m120 : 37|1@1+ (1,0) [0|1] "" Vector__XXX
 SG_ VCSEAT2L_a120_PARTY_prndControl m120 : 38|1@1+ (1,0) [0|1] "" Vector__XXX
 SG_ VCSEAT2L_a120_PARTY_locStatus2 m120 : 39|1@1+ (1,0) [0|1] "" Vector__XXX
 SG_ VCSEAT2L_a120_VEH_chassisCntl m120 : 40|1@1+ (1,0) [0|1] "" Vector__XXX
 SG_ VCSEAT2L_a120_CH_locStatus2 m120 : 41|1@1+ (1,0) [0|1] "" Vector__XXX
 SG_ VCSEAT2L_a120_VEH_locStatus m120 : 42|1@1+ (1,0) [0|1] "" Vector__XXX
 SG_ VCSEAT2L_a120_VEH_locStatus2 m120 : 43|1@1+ (1,0) [0|1] "" Vector__XXX
 SG_ VCSEAT2L_a120_VEH_prndControl m120 : 44|1@1+ (1,0) [0|1] "" Vector__XXX
 SG_ VCSEAT2L_a120_VEH_vehicleEstimat m120 : 45|1@1+ (1,0) [0|1] "" Vector__XXX
 SG_ VCSEAT2L_a120_PARTY_motorStatus m120 : 46|1@1+ (1,0) [0|1] "" Vector__XXX
 SG_ VCSEAT2L_a120_VEH_motorStatus m120 : 47|1@1+ (1,0) [0|1] "" Vector__XXX
 SG_ VCSEAT2L_a120_BDY_speed m120 : 48|1@1+ (1,0) [0|1] "" Vector__XXX
 SG_ VCSEAT2L_a210_seatMotorCalibrate m210 : 16|1@1+ (1,0) [0|1] "" Vector__XXX
 SG_ VCSEAT2L_a210_seatMotorCurrent m210 : 17|12@1- (0.01,0) [-20.48|20.47] "A" Vector__XXX
 SG_ VCSEAT2L_a210_seatMotorState m210 : 29|3@1+ (1,0) [0|7] "" Vector__XXX
 SG_ VCSEAT2L_a210_seatSwitchBack m210 : 32|2@1+ (1,0) [1|3] "" Vector__XXX
 SG_ VCSEAT2L_a210_seatSwitchForward m210 : 34|2@1+ (1,0) [1|3] "" Vector__XXX
 SG_ VCSEAT2L_a211_seatMotorCurrent m211 : 16|12@1- (0.01,0) [-20.48|20.47] "A" Vector__XXX
 SG_ VCSEAT2L_a211_seatMotorPosReal m211 : 28|12@1- (1,0) [-2048|2047] "mm" Vector__XXX
 SG_ VCSEAT2L_a211_seatMotorState m211 : 40|3@1+ (1,0) [0|7] "" Vector__XXX
 SG_ VCSEAT2L_a211_seatSwitchBack m211 : 43|2@1+ (1,0) [1|3] "" Vector__XXX
 SG_ VCSEAT2L_a211_seatSwitchForward m211 : 45|2@1+ (1,0) [1|3] "" Vector__XXX
 SG_ VCSEAT2L_a212_seatMotorCurrent m212 : 16|12@1- (0.01,0) [-20.48|20.47] "A" Vector__XXX
 SG_ VCSEAT2L_a212_seatMotorPosReal m212 : 28|12@1- (1,0) [-2048|2047] "mm" Vector__XXX
 SG_ VCSEAT2L_a212_seatMotorState m212 : 40|3@1+ (1,0) [0|7] "" Vector__XXX
 SG_ VCSEAT2L_a212_seatSwitchBack m212 : 43|2@1+ (1,0) [1|3] "" Vector__XXX
 SG_ VCSEAT2L_a212_seatSwitchForward m212 : 45|2@1+ (1,0) [1|3] "" Vector__XXX
 SG_ VCSEAT2L_a213_seatMotorCalibrate m213 : 16|1@1+ (1,0) [0|1] "" Vector__XXX
 SG_ VCSEAT2L_a213_seatMotorCurrent m213 : 17|12@1- (0.01,0) [-20.48|20.47] "A" Vector__XXX
 SG_ VCSEAT2L_a213_seatMotorPosReal m213 : 32|12@1- (1,0) [-2048|2047] "mm" Vector__XXX
 SG_ VCSEAT2L_a213_seatMotorState m213 : 44|3@1+ (1,0) [0|7] "" Vector__XXX
 SG_ VCSEAT2L_a213_seatSwitchBack m213 : 48|2@1+ (1,0) [1|3] "" Vector__XXX
 SG_ VCSEAT2L_a213_seatSwitchForward m213 : 50|2@1+ (1,0) [1|3] "" Vector__XXX
 SG_ VCSEAT2L_a214_seatMotorCurrent m214 : 16|12@1- (0.01,0) [-20.48|20.47] "A" Vector__XXX
 SG_ VCSEAT2L_a214_seatMotorDCurrent m214 : 28|12@1- (0.01,0) [-20.48|20.47] "A" Vector__XXX
 SG_ VCSEAT2L_a214_seatMotorPosReal m214 : 40|12@1- (1,0) [-2048|2047] "mm" Vector__XXX
 SG_ VCSEAT2L_a214_seatMotorState m214 : 52|3@1+ (1,0) [0|7] "" Vector__XXX
 SG_ VCSEAT2L_a215_seatMotorCurrent m215 : 16|12@1- (0.01,0) [-20.48|20.47] "A" Vector__XXX
 SG_ VCSEAT2L_a215_seatMotorDCurrent m215 : 28|12@1- (0.01,0) [-20.48|20.47] "A" Vector__XXX
 SG_ VCSEAT2L_a215_seatMotorPosReal m215 : 40|12@1- (1,0) [-2048|2047] "mm" Vector__XXX
 SG_ VCSEAT2L_a215_seatMotorState m215 : 52|3@1+ (1,0) [0|7] "" Vector__XXX
 SG_ VCSEAT2L_a224_seatMotorCalibrate m224 : 16|1@1+ (1,0) [0|1] "" Vector__XXX
 SG_ VCSEAT2L_a224_seatMotorCurrent m224 : 17|12@1- (0.01,0) [-20.48|20.47] "A" Vector__XXX
 SG_ VCSEAT2L_a224_seatMotorState m224 : 29|3@1+ (1,0) [0|7] "" Vector__XXX
 SG_ VCSEAT2L_a224_seatSwitchBack m224 : 32|2@1+ (1,0) [1|3] "" Vector__XXX
 SG_ VCSEAT2L_a224_seatSwitchForward m224 : 34|2@1+ (1,0) [1|3] "" Vector__XXX
 SG_ VCSEAT2L_a225_seatMotorCalibrate m225 : 16|1@1+ (1,0) [0|1] "" Vector__XXX
 SG_ VCSEAT2L_a225_seatMotorCurrent m225 : 17|12@1- (0.01,0) [-20.48|20.47] "A" Vector__XXX
 SG_ VCSEAT2L_a225_seatMotorState m225 : 29|3@1+ (1,0) [0|7] "" Vector__XXX
 SG_ VCSEAT2L_a225_seatSwitchBack m225 : 32|2@1+ (1,0) [1|3] "" Vector__XXX
 SG_ VCSEAT2L_a225_seatSwitchForward m225 : 34|2@1+ (1,0) [1|3] "" Vector__XXX
 SG_ VCSEAT2L_a228_seatMotorCalibrate m228 : 16|1@1+ (1,0) [0|1] "" Vector__XXX
 SG_ VCSEAT2L_a228_seatMotorCurrent m228 : 17|12@1- (0.01,0) [-20.48|20.47] "A" Vector__XXX
 SG_ VCSEAT2L_a228_seatMotorPosReal m228 : 32|12@1- (1,0) [-2048|2047] "mm" Vector__XXX
 SG_ VCSEAT2L_a228_seatMotorState m228 : 44|3@1+ (1,0) [0|7] "" Vector__XXX
 SG_ VCSEAT2L_a228_seatSwitchBack m228 : 48|2@1+ (1,0) [1|3] "" Vector__XXX
 SG_ VCSEAT2L_a228_seatSwitchForward m228 : 50|2@1+ (1,0) [1|3] "" Vector__XXX
 SG_ VCSEAT2L_a229_seatMotorCalibrate m229 : 16|1@1+ (1,0) [0|1] "" Vector__XXX
 SG_ VCSEAT2L_a229_seatMotorCurrent m229 : 17|12@1- (0.01,0) [-20.48|20.47] "A" Vector__XXX
 SG_ VCSEAT2L_a229_seatMotorPosReal m229 : 32|12@1- (1,0) [-2048|2047] "mm" Vector__XXX
 SG_ VCSEAT2L_a229_seatMotorState m229 : 44|3@1+ (1,0) [0|7] "" Vector__XXX
 SG_ VCSEAT2L_a229_seatSwitchBack m229 : 48|2@1+ (1,0) [1|3] "" Vector__XXX
 SG_ VCSEAT2L_a229_seatSwitchForward m229 : 50|2@1+ (1,0) [1|3] "" Vector__XXX
 SG_ VCSEAT2L_a232_seatMotorCurrent m232 : 16|12@1- (0.01,0) [-20.48|20.47] "A" Vector__XXX
 SG_ VCSEAT2L_a232_seatMotorPosReal m232 : 28|12@1- (1,0) [-2048|2047] "mm" Vector__XXX
 SG_ VCSEAT2L_a232_seatMotorState m232 : 40|3@1+ (1,0) [0|7] "" Vector__XXX
 SG_ VCSEAT2L_a232_seatSwitchBack m232 : 43|2@1+ (1,0) [1|3] "" Vector__XXX
 SG_ VCSEAT2L_a232_seatSwitchForward m232 : 45|2@1+ (1,0) [1|3] "" Vector__XXX
 SG_ VCSEAT2L_a233_seatMotorCurrent m233 : 16|12@1- (0.01,0) [-20.48|20.47] "A" Vector__XXX
 SG_ VCSEAT2L_a233_seatMotorPosReal m233 : 28|12@1- (1,0) [-2048|2047] "mm" Vector__XXX
 SG_ VCSEAT2L_a233_seatMotorState m233 : 40|3@1+ (1,0) [0|7] "" Vector__XXX
 SG_ VCSEAT2L_a233_seatSwitchBack m233 : 43|2@1+ (1,0) [1|3] "" Vector__XXX
 SG_ VCSEAT2L_a233_seatSwitchForward m233 : 45|2@1+ (1,0) [1|3] "" Vector__XXX
 SG_ VCSEAT2L_a239_seatHeatCurrent m239 : 16|12@1+ (0.01,0) [0|40.95] "A" Vector__XXX
 SG_ VCSEAT2L_a239_seatHeatTmp m239 : 28|12@1- (0.05,0) [-102.4|102.35] "degC" Vector__XXX
 SG_ VCSEAT2L_a239_seatHeatTmpTarget m239 : 40|8@1- (0.5,0) [-64|63.5] "degC" Vector__XXX
 SG_ VCSEAT2L_a240_seatHeatCurrent m240 : 16|12@1+ (0.01,0) [0|40.95] "A" Vector__XXX
 SG_ VCSEAT2L_a240_seatHeatTmp m240 : 28|12@1- (0.05,0) [-102.4|102.35] "degC" Vector__XXX
 SG_ VCSEAT2L_a242_snsShortCircuit m242 : 16|1@1+ (1,0) [0|1] "" Vector__XXX
 SG_ VCSEAT2L_a242_snsDisconnect m242 : 17|1@1+ (1,0) [0|1] "" Vector__XXX
 SG_ VCSEAT2L_a242_snsRateChangeUp m242 : 18|1@1+ (1,0) [0|1] "" Vector__XXX
 SG_ VCSEAT2L_a242_snsRateChangeDown m242 : 19|1@1+ (1,0) [0|1] "" Vector__XXX
 SG_ VCSEAT2L_a251_seatMotorCurrent m251 : 16|12@1- (0.01,0) [-20.48|20.47] "A" Vector__XXX
 SG_ VCSEAT2L_a251_seatMotorPosReal m251 : 28|12@1- (1,0) [-2048|2047] "mm" Vector__XXX
 SG_ VCSEAT2L_a251_seatMotorState m251 : 40|3@1+ (1,0) [0|7] "" Vector__XXX
 SG_ VCSEAT2L_a251_seatSwitchBack m251 : 43|2@1+ (1,0) [1|3] "" Vector__XXX
 SG_ VCSEAT2L_a251_seatSwitchForward m251 : 45|2@1+ (1,0) [1|3] "" Vector__XXX
 SG_ VCSEAT2L_a252_seatMotorCurrent m252 : 16|12@1- (0.01,0) [-20.48|20.47] "A" Vector__XXX
 SG_ VCSEAT2L_a252_seatMotorPosReal m252 : 28|12@1- (1,0) [-2048|2047] "mm" Vector__XXX
 SG_ VCSEAT2L_a252_seatMotorState m252 : 40|3@1+ (1,0) [0|7] "" Vector__XXX
 SG_ VCSEAT2L_a252_seatSwitchBack m252 : 43|2@1+ (1,0) [1|3] "" Vector__XXX
 SG_ VCSEAT2L_a252_seatSwitchForward m252 : 45|2@1+ (1,0) [1|3] "" Vector__XXX
 SG_ VCSEAT2L_a260_seatStatePrev m260 : 16|3@1+ (1,0) [0|7] "" Vector__XXX
 SG_ VCSEAT2L_a260_obstacleDetectReas m260 : 19|3@1+ (1,0) [0|7] "" Vector__XXX
 SG_ VCSEAT2L_a260_obstacleDetectPosi m260 : 22|9@1- (1,140) [-116|395] "mm" Vector__XXX
 SG_ VCSEAT2L_a260_accelLookbackTripD m260 : 32|8@1+ (1,0) [0|255] "" Vector__XXX
 SG_ VCSEAT2L_a260_seatMotorCurrent m260 : 40|12@1- (0.01,0) [-20.48|20.47] "A" Vector__XXX
 SG_ VCSEAT2L_a261_seatStatePrev m261 : 16|3@1+ (1,0) [0|7] "" Vector__XXX
 SG_ VCSEAT2L_a261_obstacleDetectReas m261 : 19|3@1+ (1,0) [0|7] "" Vector__XXX
 SG_ VCSEAT2L_a261_obstacleDetectPosi m261 : 22|9@1- (1,140) [-116|395] "mm" Vector__XXX
 SG_ VCSEAT2L_a261_accelLookbackTripD m261 : 32|8@1+ (1,0) [0|255] "" Vector__XXX
 SG_ VCSEAT2L_a261_seatMotorCurrent m261 : 40|12@1- (0.01,0) [-20.48|20.47] "A" Vector__XXX
 SG_ VCSEAT2L_a263_seatMotorCurrent m263 : 16|12@1- (0.01,0) [-20.48|20.47] "A" Vector__XXX
 SG_ VCSEAT2L_a263_seatMotorDCurrent m263 : 28|12@1- (0.01,0) [-20.48|20.47] "A" Vector__XXX
 SG_ VCSEAT2L_a263_seatMotorPosReal m263 : 40|12@1- (1,0) [-2048|2047] "mm" Vector__XXX
 SG_ VCSEAT2L_a263_seatMotorState m263 : 52|3@1+ (1,0) [0|7] "" Vector__XXX
 SG_ VCSEAT2L_a264_seatMotorCurrent m264 : 16|12@1- (0.01,0) [-20.48|20.47] "A" Vector__XXX
 SG_ VCSEAT2L_a264_seatMotorDCurrent m264 : 28|12@1- (0.01,0) [-20.48|20.47] "A" Vector__XXX
 SG_ VCSEAT2L_a264_seatMotorPosReal m264 : 40|12@1- (1,0) [-2048|2047] "mm" Vector__XXX
 SG_ VCSEAT2L_a264_seatMotorState m264 : 52|3@1+ (1,0) [0|7] "" Vector__XXX
 SG_ VCSEAT2L_a267_seatMotorCurrent m267 : 16|12@1- (0.01,0) [-20.48|20.47] "A" Vector__XXX
 SG_ VCSEAT2L_a267_seatMotorDCurrent m267 : 28|12@1- (0.01,0) [-20.48|20.47] "A" Vector__XXX
 SG_ VCSEAT2L_a267_seatMotorPosReal m267 : 40|12@1- (1,0) [-2048|2047] "mm" Vector__XXX
 SG_ VCSEAT2L_a267_seatMotorState m267 : 52|3@1+ (1,0) [0|7] "" Vector__XXX
 SG_ VCSEAT2L_a268_seatMotorCurrent m268 : 16|12@1- (0.01,0) [-20.48|20.47] "A" Vector__XXX
 SG_ VCSEAT2L_a268_seatMotorDCurrent m268 : 28|12@1- (0.01,0) [-20.48|20.47] "A" Vector__XXX
 SG_ VCSEAT2L_a268_seatMotorPosReal m268 : 40|12@1- (1,0) [-2048|2047] "mm" Vector__XXX
 SG_ VCSEAT2L_a268_seatMotorState m268 : 52|3@1+ (1,0) [0|7] "" Vector__XXX
 SG_ VCSEAT2L_a270_isRearwardEndstopU m270 : 16|1@1+ (1,0) [0|1] "" Vector__XXX
 SG_ VCSEAT2L_a270_isAbsPosSensorUnca m270 : 17|1@1+ (1,0) [0|1] "" Vector__XXX
 SG_ VCSEAT2L_a270_seatState m270 : 18|4@1+ (1,0) [0|14] "" Vector__XXX
 SG_ VCSEAT2L_a270_motorType m270 : 22|1@1+ (1,0) [0|1] "" Vector__XXX
 SG_ VCSEAT2L_a270_absPosSensState m270 : 24|2@1+ (1,0) [0|3] "" Vector__XXX
 SG_ VCSEAT2L_a273_calibrated m273 : 16|1@1+ (1,0) [0|1] "" Vector__XXX
 SG_ VCSEAT2L_a273_angle m273 : 17|8@1- (0.5,59) [-5|122.5] "deg" Vector__XXX
 SG_ VCSEAT2L_a273_seatStatePrev m273 : 25|4@1+ (1,0) [0|14] "" Vector__XXX
 SG_ VCSEAT2L_a273_obstacleDetectReas m273 : 29|4@1+ (1,0) [0|15] "" Vector__XXX
 SG_ VCSEAT2L_a273_accelLookbackTripD m273 : 33|7@1+ (1,0) [0|127] "" Vector__XXX
 SG_ VCSEAT2L_a273_duty m273 : 40|8@1- (1,0) [-128|127] "%" Vector__XXX
 SG_ VCSEAT2L_a273_currentAbsFilt m273 : 48|8@1+ (0.25,0) [0|63.75] "A" Vector__XXX
 SG_ VCSEAT2L_a273_motorType m273 : 56|1@1+ (1,0) [0|1] "" Vector__XXX
 SG_ VCSEAT2L_a273_absolutePosSensorF m273 : 57|1@1+ (1,0) [0|1] "" Vector__XXX
 SG_ VCSEAT2L_a273_cabinTemp m273 : 58|6@1- (2,20) [-44|82] "degC" Vector__XXX
 SG_ VCSEAT2L_a277_isRearwardEndstopU m277 : 16|1@1+ (1,0) [0|1] "" Vector__XXX
 SG_ VCSEAT2L_a277_isAbsPosSensorUnca m277 : 17|1@1+ (1,0) [0|1] "" Vector__XXX
 SG_ VCSEAT2L_a278_seatState m278 : 16|4@1+ (1,0) [0|14] "" Vector__XXX
 SG_ VCSEAT2L_a290_isNetworkSwitch m290 : 16|1@1+ (1,0) [0|1] "" Vector__XXX
 SG_ VCSEAT2L_a290_occupancySensorV m290 : 17|12@1- (0.01,0) [-20.48|20.47] "V" Vector__XXX
 SG_ VCSEAT2L_a290_railVoltage m290 : 32|12@1- (0.01,0) [-20.48|20.47] "V" Vector__XXX
 SG_ VCSEAT2L_a291_buckleSensorVoltag m291 : 16|12@1+ (0.01,0) [0|40.95] "V" Vector__XXX
 SG_ VCSEAT2L_a291_railVoltage m291 : 28|12@1+ (0.01,0) [0|40.95] "V" Vector__XXX
 SG_ VCSEAT2L_a426_seatMotorCalibrate m426 : 16|1@1+ (1,0) [0|1] "" Vector__XXX
 SG_ VCSEAT2L_a426_seatMotorCurrent m426 : 17|12@1- (0.01,0) [-20.48|20.47] "A" Vector__XXX
 SG_ VCSEAT2L_a426_seatMotorPosReal m426 : 32|12@1- (1,0) [-2048|2047] "mm" Vector__XXX
 SG_ VCSEAT2L_a426_seatMotorState m426 : 44|3@1+ (1,0) [0|7] "" Vector__XXX
 SG_ VCSEAT2L_a426_seatSwitchBack m426 : 48|2@1+ (1,0) [1|3] "" Vector__XXX
 SG_ VCSEAT2L_a426_seatSwitchForward m426 : 50|2@1+ (1,0) [1|3] "" Vector__XXX
 SG_ VCSEAT2L_a426_cabinTmp m426 : 52|12@1- (0.1,0) [-204.8|204.7] "degC" Vector__XXX
 SG_ VCSEAT2L_a427_seatMotorCalibrate m427 : 16|1@1+ (1,0) [0|1] "" Vector__XXX
 SG_ VCSEAT2L_a427_seatMotorCurrent m427 : 17|12@1- (0.01,0) [-20.48|20.47] "A" Vector__XXX
 SG_ VCSEAT2L_a427_seatMotorPosReal m427 : 32|12@1- (1,0) [-2048|2047] "mm" Vector__XXX
 SG_ VCSEAT2L_a427_seatMotorState m427 : 44|3@1+ (1,0) [0|7] "" Vector__XXX
 SG_ VCSEAT2L_a427_seatSwitchBack m427 : 48|2@1+ (1,0) [1|3] "" Vector__XXX
 SG_ VCSEAT2L_a427_seatSwitchForward m427 : 50|2@1+ (1,0) [1|3] "" Vector__XXX
 SG_ VCSEAT2L_a427_cabinTmp m427 : 52|12@1- (0.1,0) [-204.8|204.7] "degC" Vector__XXX
 SG_ VCSEAT2L_a428_seatMotorCalibrate m428 : 16|1@1+ (1,0) [0|1] "" Vector__XXX
 SG_ VCSEAT2L_a428_seatMotorCurrent m428 : 17|12@1- (0.01,0) [-20.48|20.47] "A" Vector__XXX
 SG_ VCSEAT2L_a428_seatMotorPosReal m428 : 32|12@1- (1,0) [-2048|2047] "mm" Vector__XXX
 SG_ VCSEAT2L_a428_seatMotorState m428 : 44|3@1+ (1,0) [0|7] "" Vector__XXX
 SG_ VCSEAT2L_a428_seatSwitchBack m428 : 48|2@1+ (1,0) [1|3] "" Vector__XXX
 SG_ VCSEAT2L_a428_seatSwitchForward m428 : 50|2@1+ (1,0) [1|3] "" Vector__XXX
 SG_ VCSEAT2L_a428_cabinTmp m428 : 52|12@1- (0.1,0) [-204.8|204.7] "degC" Vector__XXX
 SG_ VCSEAT2L_a429_seatMotorCalibrate m429 : 16|1@1+ (1,0) [0|1] "" Vector__XXX
 SG_ VCSEAT2L_a429_seatMotorCurrent m429 : 17|12@1- (0.01,0) [-20.48|20.47] "A" Vector__XXX
 SG_ VCSEAT2L_a429_seatMotorPosReal m429 : 32|12@1- (1,0) [-2048|2047] "mm" Vector__XXX
 SG_ VCSEAT2L_a429_seatMotorState m429 : 44|3@1+ (1,0) [0|7] "" Vector__XXX
 SG_ VCSEAT2L_a429_seatSwitchBack m429 : 48|2@1+ (1,0) [1|3] "" Vector__XXX
 SG_ VCSEAT2L_a429_seatSwitchForward m429 : 50|2@1+ (1,0) [1|3] "" Vector__XXX
 SG_ VCSEAT2L_a429_cabinTmp m429 : 52|12@1- (0.1,0) [-204.8|204.7] "degC" Vector__XXX
 SG_ VCSEAT2L_a444_retriesAvailable m444 : 16|8@1+ (1,0) [0|255] "" Vector__XXX
 SG_ VCSEAT2L_a444_channel m444 : 24|8@1+ (1,0) [0|255] "" Vector__XXX
 SG_ VCSEAT2L_a444_watchdog m444 : 32|1@1+ (1,0) [0|1] "" Vector__XXX
 SG_ VCSEAT2L_a444_gateDriver m444 : 33|1@1+ (1,0) [0|1] "" Vector__XXX
 SG_ VCSEAT2L_a444_overcurrent m444 : 34|1@1+ (1,0) [0|1] "" Vector__XXX
 SG_ VCSEAT2L_a444_supplyUndervoltage m444 : 35|1@1+ (1,0) [0|1] "" Vector__XXX
 SG_ VCSEAT2L_a444_cpUndervoltage m444 : 36|1@1+ (1,0) [0|1] "" Vector__XXX
 SG_ VCSEAT2L_a444_overTempShutdown m444 : 37|1@1+ (1,0) [0|1] "" Vector__XXX
 SG_ VCSEAT2L_a444_overTempWarning m444 : 38|1@1+ (1,0) [0|1] "" Vector__XXX
 SG_ VCSEAT2L_a444_highSide2GateDrive m444 : 39|1@1+ (1,0) [0|1] "" Vector__XXX
 SG_ VCSEAT2L_a444_lowSide2GateDriver m444 : 40|1@1+ (1,0) [0|1] "" Vector__XXX
 SG_ VCSEAT2L_a444_highSide1GateDrive m444 : 41|1@1+ (1,0) [0|1] "" Vector__XXX
 SG_ VCSEAT2L_a444_lowSide1GateDriver m444 : 42|1@1+ (1,0) [0|1] "" Vector__XXX
 SG_ VCSEAT2L_a444_highSide2OverCuren m444 : 43|1@1+ (1,0) [0|1] "" Vector__XXX
 SG_ VCSEAT2L_a444_lowSide2OverCurent m444 : 44|1@1+ (1,0) [0|1] "" Vector__XXX
 SG_ VCSEAT2L_a444_highSide1OverCuren m444 : 45|1@1+ (1,0) [0|1] "" Vector__XXX
 SG_ VCSEAT2L_a444_lowSide1OverCurent m444 : 46|1@1+ (1,0) [0|1] "" Vector__XXX
 SG_ VCSEAT2L_a444_spiInit m444 : 47|1@1+ (1,0) [0|1] "" Vector__XXX
 SG_ VCSEAT2L_a444_spiPeriodicCheck m444 : 48|1@1+ (1,0) [0|1] "" Vector__XXX
 SG_ VCSEAT2L_a444_spiFault m444 : 49|1@1+ (1,0) [0|1] "" Vector__XXX
 SG_ VCSEAT2L_a444_voltageMonitor m444 : 50|1@1+ (1,0) [0|1] "" Vector__XXX
 SG_ VCSEAT2L_a444_enableLow m444 : 51|1@1+ (1,0) [0|1] "" Vector__XXX
 SG_ VCSEAT2L_a571_seatHeatCurrent m571 : 16|12@1+ (0.01,0) [0|40.95] "A" Vector__XXX
 SG_ VCSEAT2L_a571_seatHeatTmp m571 : 28|12@1- (0.05,0) [-102.4|102.35] "degC" Vector__XXX

BO_ 892 VCSEAT2L_alertMatrix: 8 VCSEAT2L
 SG_ VCSEAT2L_matrixIndex M : 0|4@1+ (1,0) [0|15] "" Vector__XXX
 SG_ VCSEAT2L_a001_WatchdogReset m0 : 4|1@1+ (1,0) [0|1] "" Vector__XXX
 SG_ VCSEAT2L_a002_PowerLossReset m0 : 5|1@1+ (1,0) [0|1] "" Vector__XXX
 SG_ VCSEAT2L_a003_SWAssertion m0 : 6|1@1+ (1,0) [0|1] "" Vector__XXX
 SG_ VCSEAT2L_a005_CANTXError m0 : 8|1@1+ (1,0) [0|1] "" Vector__XXX
 SG_ VCSEAT2L_a006_CANTX_cyclicError m0 : 9|1@1+ (1,0) [0|1] "" Vector__XXX
 SG_ VCSEAT2L_a010_ExtSupplyVoltError m0 : 13|1@1+ (1,0) [0|1] "" Vector__XXX
 SG_ VCSEAT2L_a012_CPUReset m0 : 15|1@1+ (1,0) [0|1] "" Vector__XXX
 SG_ VCSEAT2L_a013_AlertManagerFault m0 : 16|1@1+ (1,0) [0|1] "" Vector__XXX
 SG_ VCSEAT2L_a015_NVMMError m0 : 18|1@1+ (1,0) [0|1] "" Vector__XXX
 SG_ VCSEAT2L_a016_NVMMRecordError m0 : 19|1@1+ (1,0) [0|1] "" Vector__XXX
 SG_ VCSEAT2L_a021_TaskSchedulerError m0 : 24|1@1+ (1,0) [0|1] "" Vector__XXX
 SG_ VCSEAT2L_a022_TaskInitError m0 : 25|1@1+ (1,0) [0|1] "" Vector__XXX
 SG_ VCSEAT2L_a029_CoreDump m0 : 32|1@1+ (1,0) [0|1] "" Vector__XXX
 SG_ VCSEAT2L_a030_ECULogUploadReques m0 : 33|1@1+ (1,0) [0|1] "" Vector__XXX
 SG_ VCSEAT2L_a031_UDSActive m0 : 34|1@1+ (1,0) [0|1] "" Vector__XXX
 SG_ VCSEAT2L_a041_HighCPULoad m0 : 44|1@1+ (1,0) [0|1] "" Vector__XXX
 SG_ VCSEAT2L_a042_HighStackUsage m0 : 45|1@1+ (1,0) [0|1] "" Vector__XXX
 SG_ VCSEAT2L_a043_Task1msError m0 : 46|1@1+ (1,0) [0|1] "" Vector__XXX
 SG_ VCSEAT2L_a044_Task10msError m0 : 47|1@1+ (1,0) [0|1] "" Vector__XXX
 SG_ VCSEAT2L_a045_Task100msError m0 : 48|1@1+ (1,0) [0|1] "" Vector__XXX
 SG_ VCSEAT2L_a046_Task1000msError m0 : 49|1@1+ (1,0) [0|1] "" Vector__XXX
 SG_ VCSEAT2L_a057_HVP_MIA m0 : 60|1@1+ (1,0) [0|1] "" Vector__XXX
 SG_ VCSEAT2L_a058_inputRHighSyncDebu m0 : 61|1@1+ (1,0) [0|1] "" Vector__XXX
 SG_ VCSEAT2L_a059_inputResistanceHig m0 : 62|1@1+ (1,0) [0|1] "" Vector__XXX
 SG_ VCSEAT2L_a060_engineeringBuild m0 : 63|1@1+ (1,0) [0|1] "" Vector__XXX
 SG_ VCSEAT2L_a061_XCPConnected m1 : 4|1@1+ (1,0) [0|1] "" Vector__XXX
 SG_ VCSEAT2L_a062_XCPWasConnected m1 : 5|1@1+ (1,0) [0|1] "" Vector__XXX
 SG_ VCSEAT2L_a063_SwitchFault m1 : 6|1@1+ (1,0) [0|1] "" Vector__XXX
 SG_ VCSEAT2L_a064_busSleepReqTimeout m1 : 7|1@1+ (1,0) [0|1] "" Vector__XXX
 SG_ VCSEAT2L_a082_VCRIGHT_IPC_MIA m1 : 25|1@1+ (1,0) [0|1] "" Vector__XXX
 SG_ VCSEAT2L_a083_VCLEFT_IPC_MIA m1 : 26|1@1+ (1,0) [0|1] "" Vector__XXX
 SG_ VCSEAT2L_a084_TPMS_MIA m1 : 27|1@1+ (1,0) [0|1] "" Vector__XXX
 SG_ VCSEAT2L_a085_CCCM_MIA m1 : 28|1@1+ (1,0) [0|1] "" Vector__XXX
 SG_ VCSEAT2L_a086_VCBATT_MIA m1 : 29|1@1+ (1,0) [0|1] "" Vector__XXX
 SG_ VCSEAT2L_a087_DIREL_MIA m1 : 30|1@1+ (1,0) [0|1] "" Vector__XXX
 SG_ VCSEAT2L_a088_DIRER_MIA m1 : 31|1@1+ (1,0) [0|1] "" Vector__XXX
 SG_ VCSEAT2L_a089_IBST_MIA m1 : 32|1@1+ (1,0) [0|1] "" Vector__XXX
 SG_ VCSEAT2L_a090_APS_MIA m1 : 33|1@1+ (1,0) [0|1] "" Vector__XXX
 SG_ VCSEAT2L_a091_CMPD_MIA m1 : 34|1@1+ (1,0) [0|1] "" Vector__XXX
 SG_ VCSEAT2L_a092_VCSEATD_MIA m1 : 35|1@1+ (1,0) [0|1] "" Vector__XXX
 SG_ VCSEAT2L_a093_VCSEATP_MIA m1 : 36|1@1+ (1,0) [0|1] "" Vector__XXX
 SG_ VCSEAT2L_a094_EPAS3P_MIA m1 : 37|1@1+ (1,0) [0|1] "" Vector__XXX
 SG_ VCSEAT2L_a095_CHG_MIA m1 : 38|1@1+ (1,0) [0|1] "" Vector__XXX
 SG_ VCSEAT2L_a096_OCS1P_MIA m1 : 39|1@1+ (1,0) [0|1] "" Vector__XXX
 SG_ VCSEAT2L_a097_CMP_MIA m1 : 40|1@1+ (1,0) [0|1] "" Vector__XXX
 SG_ VCSEAT2L_a098_DIR_MIA m1 : 41|1@1+ (1,0) [0|1] "" Vector__XXX
 SG_ VCSEAT2L_a099_PARK_MIA m1 : 42|1@1+ (1,0) [0|1] "" Vector__XXX
 SG_ VCSEAT2L_a100_CANbus_MIA m1 : 43|1@1+ (1,0) [0|1] "" Vector__XXX
 SG_ VCSEAT2L_a101_PM_MIA m1 : 44|1@1+ (1,0) [0|1] "" Vector__XXX
 SG_ VCSEAT2L_a102_PTC_MIA m1 : 45|1@1+ (1,0) [0|1] "" Vector__XXX
 SG_ VCSEAT2L_a103_CP_MIA m1 : 46|1@1+ (1,0) [0|1] "" Vector__XXX
 SG_ VCSEAT2L_a104_DAS_MIA m1 : 47|1@1+ (1,0) [0|1] "" Vector__XXX
 SG_ VCSEAT2L_a105_TAS_MIA m1 : 48|1@1+ (1,0) [0|1] "" Vector__XXX
 SG_ VCSEAT2L_a106_PCS_MIA m1 : 49|1@1+ (1,0) [0|1] "" Vector__XXX
 SG_ VCSEAT2L_a107_BMS_MIA m1 : 50|1@1+ (1,0) [0|1] "" Vector__XXX
 SG_ VCSEAT2L_a108_DIF_MIA m1 : 51|1@1+ (1,0) [0|1] "" Vector__XXX
 SG_ VCSEAT2L_a109_RCM_MIA m1 : 52|1@1+ (1,0) [0|1] "" Vector__XXX
 SG_ VCSEAT2L_a110_GTW_MIA m1 : 53|1@1+ (1,0) [0|1] "" Vector__XXX
 SG_ VCSEAT2L_a111_EPBR_MIA m1 : 54|1@1+ (1,0) [0|1] "" Vector__XXX
 SG_ VCSEAT2L_a112_EPBL_MIA m1 : 55|1@1+ (1,0) [0|1] "" Vector__XXX
 SG_ VCSEAT2L_a113_UI_MIA m1 : 56|1@1+ (1,0) [0|1] "" Vector__XXX
 SG_ VCSEAT2L_a114_ESP_MIA m1 : 57|1@1+ (1,0) [0|1] "" Vector__XXX
 SG_ VCSEAT2L_a115_VCSEC_MIA m1 : 58|1@1+ (1,0) [0|1] "" Vector__XXX
 SG_ VCSEAT2L_a116_VCRIGHT_MIA m1 : 59|1@1+ (1,0) [0|1] "" Vector__XXX
 SG_ VCSEAT2L_a117_VCLEFT_MIA m1 : 60|1@1+ (1,0) [0|1] "" Vector__XXX
 SG_ VCSEAT2L_a118_VCFRONT_MIA m1 : 61|1@1+ (1,0) [0|1] "" Vector__XXX
 SG_ VCSEAT2L_a119_SCCM_MIA m1 : 62|1@1+ (1,0) [0|1] "" Vector__XXX
 SG_ VCSEAT2L_a120_DI_DRIVE_MIA m1 : 63|1@1+ (1,0) [0|1] "" Vector__XXX
 SG_ VCSEAT2L_a190_seatChoreographyIs m3 : 13|1@1+ (1,0) [0|1] "" Vector__XXX
 SG_ VCSEAT2L_a191_seatChoreographyIs m3 : 14|1@1+ (1,0) [0|1] "" Vector__XXX
 SG_ VCSEAT2L_a200_motorPhantomEncode m3 : 23|1@1+ (1,0) [0|1] "" Vector__XXX
 SG_ VCSEAT2L_a201_motorDutyEncDisabl m3 : 24|1@1+ (1,0) [0|1] "" Vector__XXX
 SG_ VCSEAT2L_a210_armrestEncStall m3 : 33|1@1+ (1,0) [0|1] "" Vector__XXX
 SG_ VCSEAT2L_a211_armrestCurrUnder m3 : 34|1@1+ (1,0) [0|1] "" Vector__XXX
 SG_ VCSEAT2L_a212_armrestUncal m3 : 35|1@1+ (1,0) [0|1] "" Vector__XXX
 SG_ VCSEAT2L_a213_armrestEncOver m3 : 36|1@1+ (1,0) [0|1] "" Vector__XXX
 SG_ VCSEAT2L_a214_armrestStallDebug m3 : 37|1@1+ (1,0) [0|1] "" Vector__XXX
 SG_ VCSEAT2L_a215_armrestHCEncStlDbg m3 : 38|1@1+ (1,0) [0|1] "" Vector__XXX
 SG_ VCSEAT2L_a218_motorDriverFault m3 : 41|1@1+ (1,0) [0|1] "" Vector__XXX
 SG_ VCSEAT2L_a219_motorCurrentDropou m3 : 42|1@1+ (1,0) [0|1] "" Vector__XXX
 SG_ VCSEAT2L_a224_seatEncStallTrack m3 : 47|1@1+ (1,0) [0|1] "" Vector__XXX
 SG_ VCSEAT2L_a225_seatEncStallBack m3 : 48|1@1+ (1,0) [0|1] "" Vector__XXX
 SG_ VCSEAT2L_a228_seatEncOverTrack m3 : 51|1@1+ (1,0) [0|1] "" Vector__XXX
 SG_ VCSEAT2L_a229_seatEncOverBack m3 : 52|1@1+ (1,0) [0|1] "" Vector__XXX
 SG_ VCSEAT2L_a232_seatCurrUnderTrack m3 : 55|1@1+ (1,0) [0|1] "" Vector__XXX
 SG_ VCSEAT2L_a233_seatCurrUnderBack m3 : 56|1@1+ (1,0) [0|1] "" Vector__XXX
 SG_ VCSEAT2L_a234_seatTrackStatsFrom m3 : 57|1@1+ (1,0) [0|1] "" Vector__XXX
 SG_ VCSEAT2L_a235_seatTrackStatsFrom m3 : 58|1@1+ (1,0) [0|1] "" Vector__XXX
 SG_ VCSEAT2L_a236_seatArmrestStatsFr m3 : 59|1@1+ (1,0) [0|1] "" Vector__XXX
 SG_ VCSEAT2L_a237_seatArmrestStatsFr m3 : 60|1@1+ (1,0) [0|1] "" Vector__XXX
 SG_ VCSEAT2L_a238_seatArmrestInhibit m3 : 61|1@1+ (1,0) [0|1] "" Vector__XXX
 SG_ VCSEAT2L_a239_seatHeatIRow2 m3 : 62|1@1+ (1,0) [0|1] "" Vector__XXX
 SG_ VCSEAT2L_a240_seatHeatShortRow2 m3 : 63|1@1+ (1,0) [0|1] "" Vector__XXX
 SG_ VCSEAT2L_a241_seatArmrestHistory m4 : 4|1@1+ (1,0) [0|1] "" Vector__XXX
 SG_ VCSEAT2L_a242_seatHeatTmpRow2 m4 : 5|1@1+ (1,0) [0|1] "" Vector__XXX
 SG_ VCSEAT2L_a243_seatArmrestHistory m4 : 6|1@1+ (1,0) [0|1] "" Vector__XXX
 SG_ VCSEAT2L_a244_seatArmrestSpeedTa m4 : 7|1@1+ (1,0) [0|1] "" Vector__XXX
 SG_ VCSEAT2L_a245_seatArmrestEcuLogS m4 : 8|1@1+ (1,0) [0|1] "" Vector__XXX
 SG_ VCSEAT2L_a251_seatUncalTrack m4 : 14|1@1+ (1,0) [0|1] "" Vector__XXX
 SG_ VCSEAT2L_a252_seatUncalBack m4 : 15|1@1+ (1,0) [0|1] "" Vector__XXX
 SG_ VCSEAT2L_a260_seatTrackObstacleD m4 : 23|1@1+ (1,0) [0|1] "" Vector__XXX
 SG_ VCSEAT2L_a261_seatArmrestObstacl m4 : 24|1@1+ (1,0) [0|1] "" Vector__XXX
 SG_ VCSEAT2L_a263_seatTrackStallDebu m4 : 26|1@1+ (1,0) [0|1] "" Vector__XXX
 SG_ VCSEAT2L_a264_seatBackStallDebug m4 : 27|1@1+ (1,0) [0|1] "" Vector__XXX
 SG_ VCSEAT2L_a267_seatTrackHCEncStl m4 : 30|1@1+ (1,0) [0|1] "" Vector__XXX
 SG_ VCSEAT2L_a268_seatBackHCEncStlDb m4 : 31|1@1+ (1,0) [0|1] "" Vector__XXX
 SG_ VCSEAT2L_a270_seatUncalibrated m4 : 33|1@1+ (1,0) [0|1] "" Vector__XXX
 SG_ VCSEAT2L_a271_seatPositionNonsen m4 : 34|1@1+ (1,0) [0|1] "" Vector__XXX
 SG_ VCSEAT2L_a272_seatAbsPosOffsetAp m4 : 35|1@1+ (1,0) [0|1] "" Vector__XXX
 SG_ VCSEAT2L_a273_seatObstacleDetect m4 : 36|1@1+ (1,0) [0|1] "" Vector__XXX
 SG_ VCSEAT2L_a274_seatTempHigh m4 : 37|1@1+ (1,0) [0|1] "" Vector__XXX
 SG_ VCSEAT2L_a275_seatAbsPosSensorTr m4 : 38|1@1+ (1,0) [0|1] "" Vector__XXX
 SG_ VCSEAT2L_a276_seatStatsFromLastS m4 : 39|1@1+ (1,0) [0|1] "" Vector__XXX
 SG_ VCSEAT2L_a277_seatRequestWhileUn m4 : 40|1@1+ (1,0) [0|1] "" Vector__XXX
 SG_ VCSEAT2L_a278_seatClashAvoidance m4 : 41|1@1+ (1,0) [0|1] "" Vector__XXX
 SG_ VCSEAT2L_a279_seatOverfolded m4 : 42|1@1+ (1,0) [0|1] "" Vector__XXX
 SG_ VCSEAT2L_a280_seatStatsFromLastS m4 : 43|1@1+ (1,0) [0|1] "" Vector__XXX
 SG_ VCSEAT2L_a290_occupancyFaultRow2 m4 : 53|1@1+ (1,0) [0|1] "" Vector__XXX
 SG_ VCSEAT2L_a291_buckleFaultedRow2 m4 : 54|1@1+ (1,0) [0|1] "" Vector__XXX
 SG_ VCSEAT2L_a426_seatAbuseMotorWarn m7 : 9|1@1+ (1,0) [0|1] "" Vector__XXX
 SG_ VCSEAT2L_a427_seatAbuseMotorStop m7 : 10|1@1+ (1,0) [0|1] "" Vector__XXX
 SG_ VCSEAT2L_a428_seatAbuseBufferWar m7 : 11|1@1+ (1,0) [0|1] "" Vector__XXX
 SG_ VCSEAT2L_a429_seatAbuseBufferFul m7 : 12|1@1+ (1,0) [0|1] "" Vector__XXX
 SG_ VCSEAT2L_a444_drv8703Fault m7 : 27|1@1+ (1,0) [0|1] "" Vector__XXX
 SG_ VCSEAT2L_a445_drv8703SpiFaultDBG m7 : 28|1@1+ (1,0) [0|1] "" Vector__XXX
 SG_ VCSEAT2L_a526_pcbaOverTemperatur m8 : 49|1@1+ (1,0) [0|1] "" Vector__XXX
 SG_ VCSEAT2L_a550_ambientTempDelta m9 : 13|1@1+ (1,0) [0|1] "" Vector__XXX
 SG_ VCSEAT2L_a571_seatHeatDisabledRe m9 : 34|1@1+ (1,0) [0|1] "" Vector__XXX

BO_ 764 VCSEAT2L_seatStatus: 8 VCSEAT2L
 SG_ VCSEAT2L_row2SeatStatusIndex M : 0|2@1+ (1,0) [0|3] "" Vector__XXX
 SG_ VCSEAT2L_seatTrackPosReal m1 : 4|12@1- (1,0) [-2048|2047] "mm" Vector__XXX
 SG_ VCSEAT2L_seatTrackPosOffset m1 : 16|12@1- (1,0) [-2048|2047] "mm" Vector__XXX
 SG_ VCSEAT2L_seatReclineState m1 : 28|4@1+ (1,0) [0|14] "" Vector__XXX
 SG_ VCSEAT2L_seatReclineCalibrated m1 : 32|1@1+ (1,0) [0|1] "" Vector__XXX
 SG_ VCSEAT2L_seatReclinePositionStat m1 : 33|3@1+ (1,0) [0|7] "" Vector__XXX
 SG_ VCSEAT2L_seatReclineAbsPosS_0001 m1 : 36|12@1- (0.1,0) [-204.8|204.7] "deg" Vector__XXX
 SG_ VCSEAT2L_seatReclineAbsPosSwitch m1 : 48|2@1+ (1,0) [1|3] "" Vector__XXX
 SG_ VCSEAT2L_seatReclineFoldAllowed m1 : 50|1@1+ (1,0) [0|1] "" Vector__XXX
 SG_ VCSEAT2L_seatReclineUnfoldAllowe m1 : 51|1@1+ (1,0) [0|1] "" Vector__XXX
 SG_ VCSEAT2L_seatReclineAdjustmentAl m1 : 52|1@1+ (1,0) [0|1] "" Vector__XXX
 SG_ VCSEAT2L_seat1RClashAvoidanceBlo m1 : 53|3@1+ (1,0) [0|7] "" Vector__XXX
 SG_ VCSEAT2L_seat1RClashAvoidanceSta m1 : 56|2@1+ (1,0) [0|3] "" Vector__XXX
 SG_ VCSEAT2L_seatReclineChoreoBlocke m1 : 58|1@1+ (1,0) [0|1] "" Vector__XXX
 SG_ VCSEAT2L_seatReclineNextToggleDi m1 : 59|2@1+ (1,0) [0|3] "" Vector__XXX

BO_ 1986 VCSEAT2L_seatStatus2: 8 VCSEAT2L
 SG_ VCSEAT2L_seatStatus2Index M : 0|3@1+ (1,0) [0|7] "" Vector__XXX
 SG_ VCSEAT2L_choreography2RState m4 : 4|2@1+ (1,0) [0|3] "" Vector__XXX
 SG_ VCSEAT2L_choreography3RState m4 : 7|2@1+ (1,0) [0|3] "" Vector__XXX
 SG_ VCSEAT2L_choreography1RIsAllowed m4 : 10|1@1+ (1,0) [0|1] "" Vector__XXX
 SG_ VCSEAT2L_choreography2RIsAllowed m4 : 11|1@1+ (1,0) [0|1] "" Vector__XXX
 SG_ VCSEAT2L_choreography1RTrackVelo m4 : 12|3@1+ (1,0) [0|7] "" Vector__XXX
 SG_ VCSEAT2L_choreography1RBackrestV m4 : 15|3@1+ (1,0) [0|7] "" Vector__XXX
 SG_ VCSEAT2L_choreography2RTrackVelo m4 : 18|3@1+ (1,0) [0|7] "" Vector__XXX
 SG_ VCSEAT2L_choreography2RBackrestV m4 : 21|3@1+ (1,0) [0|7] "" Vector__XXX
 SG_ VCSEAT2L_choreography3RBackrestV m4 : 24|3@1+ (1,0) [0|7] "" Vector__XXX
 SG_ VCSEAT2L_choreographyState m4 : 27|4@1+ (1,0) [0|15] "" Vector__XXX
 SG_ VCSEAT2L_choreographyCollisionPa m4 : 32|3@1+ (1,0) [0|7] "" Vector__XXX
 SG_ VCSEAT2L_2rMovingForChoreography m4 : 35|1@1+ (1,0) [0|1] "" Vector__XXX

BO_TX_BU_ 963 : VCRIGHT;
BO_TX_BU_ 899 : VCRIGHT;
BO_TX_BU_ 1545 : VCRIGHT;
BO_TX_BU_ 1059 : VCRIGHT;
BO_TX_BU_ 707 : VCRIGHT;
BO_TX_BU_ 1375 : VCSEAT2L;
BO_TX_BU_ 892 : VCSEAT2L;
BO_TX_BU_ 764 : VCSEAT2L;
BO_TX_BU_ 1986 : VCSEAT2L;
CM_ BO_ 963 "Right body controller message: switch status; frame length observed on a vehicle bus";
CM_ SG_ 963 VCRIGHT_switchStatusIndex "Right body controller: switch status index";
CM_ SG_ 963 VCRIGHT_btnWindowUpRF "Position from firmware; message assignment inferred.";
CM_ SG_ 963 VCRIGHT_btnWindowAutoUpRF "Position from firmware; message assignment inferred.";
CM_ SG_ 963 VCRIGHT_btnWindowDownRF "Position from firmware; message assignment inferred.";
CM_ SG_ 963 VCRIGHT_btnWindowAutoDownRF "Position from firmware; message assignment inferred.";
CM_ SG_ 963 VCRIGHT_btnWindowUpRR "Position from firmware; message assignment inferred.";
CM_ SG_ 963 VCRIGHT_btnWindowAutoUpRR "Position from firmware; message assignment inferred.";
CM_ SG_ 963 VCRIGHT_btnWindowDownRR "Position from firmware; message assignment inferred.";
CM_ SG_ 963 VCRIGHT_btnWindowAutoDownRR "Position from firmware; message assignment inferred.";
CM_ SG_ 963 VCRIGHT_btnWindowSwPackUpLF "Position from firmware; message assignment inferred.";
CM_ SG_ 963 VCRIGHT_btnWindowSwPackAutoUpLF "Position from firmware; message assignment inferred.";
CM_ SG_ 963 VCRIGHT_btnWindowSwPackDownLF "Position from firmware; message assignment inferred.";
CM_ SG_ 963 VCRIGHT_btnWindowSwPackAutoDwnLF "Position from firmware; message assignment inferred.";
CM_ SG_ 963 VCRIGHT_btnWindowSwPackUpLR "Position from firmware; message assignment inferred.";
CM_ SG_ 963 VCRIGHT_btnWindowSwPackAutoUpLR "Position from firmware; message assignment inferred.";
CM_ SG_ 963 VCRIGHT_btnWindowSwPackDownLR "Position from firmware; message assignment inferred.";
CM_ SG_ 963 VCRIGHT_btnWindowSwPackAutoDwnLR "Position from firmware; message assignment inferred.";
CM_ SG_ 963 VCRIGHT_frontOccupancySwitch "Front right seat occupancy status. Position from firmware; message assignment inferred.";
CM_ SG_ 963 VCRIGHT_trunkExtReleasePressed "State of exterior trunk release switch. Position from firmware; message assignment inferred.";
CM_ SG_ 963 VCRIGHT_btnWindowSwPackUpRR "Position from firmware; message assignment inferred.";
CM_ SG_ 963 VCRIGHT_btnWindowSwPackAutoUpRR "Position from firmware; message assignment inferred.";
CM_ SG_ 963 VCRIGHT_btnWindowSwPackDownRR "Position from firmware; message assignment inferred.";
CM_ SG_ 963 VCRIGHT_btnWindowSwPackAutoDwnRR "Position from firmware; message assignment inferred.";
CM_ SG_ 963 VCRIGHT_frontBuckleSwitch "Right body controller: front buckle switch";
CM_ SG_ 963 VCRIGHT_rearCenterBuckleSwitch "Right body controller: rear center buckle switch";
CM_ SG_ 963 VCRIGHT_rearRightBuckleSwitch "Right body controller: rear right buckle switch";
CM_ SG_ 963 VCRIGHT_trunkExtReleasePressedPe "Right body controller: trunk ext release pressed persist";
CM_ SG_ 963 VCRIGHT_frontSeatTrackBack "Right body controller: front seat track back; raw 0 = signal not available (SNA)";
CM_ SG_ 963 VCRIGHT_frontSeatTrackForward "Right body controller: front seat track forward; raw 0 = signal not available (SNA)";
CM_ SG_ 963 VCRIGHT_frontSeatTiltDown "Right body controller: front seat tilt down; raw 0 = signal not available (SNA)";
CM_ SG_ 963 VCRIGHT_frontSeatTiltUp "Right body controller: front seat tilt up; raw 0 = signal not available (SNA)";
CM_ SG_ 963 VCRIGHT_frontSeatLiftDown "Right body controller: front seat lift down; raw 0 = signal not available (SNA)";
CM_ SG_ 963 VCRIGHT_frontSeatLiftUp "Right body controller: front seat lift up; raw 0 = signal not available (SNA)";
CM_ SG_ 963 VCRIGHT_frontSeatBackrestBack "Right body controller: front seat backrest back; raw 0 = signal not available (SNA)";
CM_ SG_ 963 VCRIGHT_frontSeatBackrestForward "Right body controller: front seat backrest forward; raw 0 = signal not available (SNA)";
CM_ SG_ 963 VCRIGHT_frontSeatLumbarDown "Right body controller: front seat lumbar down; raw 0 = signal not available (SNA)";
CM_ SG_ 963 VCRIGHT_frontSeatLumbarUp "Right body controller: front seat lumbar up; raw 0 = signal not available (SNA)";
CM_ SG_ 963 VCRIGHT_frontSeatLumbarIn "Right body controller: front seat lumbar in; raw 0 = signal not available (SNA)";
CM_ SG_ 963 VCRIGHT_frontSeatResistiveOccupa "Front right seat occupancy status; raw 0 = signal not available (SNA)";
CM_ SG_ 963 VCRIGHT_2RowSeatReclineSwitchpac "State of the right second row powered recline adjustment switchpack";
CM_ SG_ 963 VCRIGHT_hvacHeatingAllowedRight "Right body controller: hvac heating allowed right";
CM_ SG_ 963 VCRIGHT_frontSeatThighSupportRet "Status of the switch used to retract front seat thigh support; raw 0 = signal not available (SNA)";
CM_ BO_ 899 "Right body controller message: ths status; frame length observed on a vehicle bus";
CM_ SG_ 899 VCRIGHT_thsActive "Right body controller: ths active";
CM_ SG_ 899 VCRIGHT_thsTemperature "Tesla HVAC sensor temperature; raw 255 = signal not available (SNA)";
CM_ SG_ 899 VCRIGHT_thsState "Right body controller: ths state";
CM_ SG_ 899 VCRIGHT_thsLINCurrentSchedule "Right body controller: ths LIN current schedule";
CM_ SG_ 899 VCRIGHT_thsDetected "Tesla HVAC sensor connection is detected";
CM_ SG_ 899 VCRIGHT_thsHumidity "Tesla HVAC sensor humidity; raw 127 = signal not available (SNA)";
CM_ SG_ 899 VCRIGHT_estimatedVehicleSituatio "Right body controller: estimated vehicle situation";
CM_ SG_ 899 VCRIGHT_thsSolarLoadInfrared "Solar power hitting the vehicle in the infrared spectrum; raw 1023 = signal not available (SNA)";
CM_ SG_ 899 VCRIGHT_thsSolarLoadVisible "Solar power hitting the vehicle in the visible spectrum; raw 1023 = signal not available (SNA)";
CM_ SG_ 899 VCRIGHT_estimatedThsSolarLoad "Right body controller: estimated ths solar load; raw 1023 = signal not available (SNA)";
CM_ SG_ 899 VCRIGHT_hvacFastLoggingEnabled "Right body controller: hvac fast logging enabled";
CM_ BO_ 1545 "Right body controller message: uds response; frame length from the layout, not yet observed on a vehicle bus";
CM_ SG_ 1545 VCRIGHT_udsResponseData_H "Right body controller: uds response data h";
CM_ SG_ 1545 VCRIGHT_udsResponseData_L "Right body controller: uds response data l";
CM_ BO_ 1059 "Right body controller message: veh nm; frame length observed on a vehicle bus";
CM_ SG_ 1059 VCRIGHT_nmGoingToSleep "Right body controller: nm going to sleep";
CM_ SG_ 1059 VCRIGHT_nmWakeUpBus "Right body controller: nm wake up bus";
CM_ SG_ 1059 VCRIGHT_nmKeepAwakeReason "Reason controller is preventing the vehicle from sleeping; raw 0 = signal not available (SNA)";
CM_ SG_ 1059 VCRIGHT_nmWakeUpReason "Right body controller: nm wake up reason";
CM_ SG_ 1059 VCRIGHT_nmDebugWakeUp "Right body controller: nm debug wake up";
CM_ SG_ 1059 VCRIGHT_nmEthKeepAwakeReason "Right body controller: nm eth keep awake reason; raw 0 = signal not available (SNA)";
CM_ SG_ 1059 VCRIGHT_nmChKeepAwakeReason "Right body controller: nm ch keep awake reason; raw 0 = signal not available (SNA)";
CM_ BO_ 707 "Right body controller message: window status; frame length observed on a vehicle bus";
CM_ SG_ 707 VCRIGHT_windowStatusIndex "Right body controller: window status index";
CM_ SG_ 707 VCRIGHT_windowStateRF "Status of right front window motor";
CM_ SG_ 707 VCRIGHT_windowTrimClearMoveReque "Reports a request for whether windows should enter or exit trim clear mode. Signal is only valid if Vehicle Controller Left (VCLEFT) is on driver side.";
CM_ SG_ 707 VCRIGHT_windowDutyRF "Right body controller: window duty RF";
CM_ SG_ 707 VCRIGHT_windowTrimClearActiveReq "Reports whether window trim clear is active. Signal is only valid if Vehicle Controller Left (VCLEFT) is on driver side; raw 0 = signal not available (SNA)";
CM_ SG_ 707 VCRIGHT_windowCurrentRF "Current drawn by left front window regulator";
CM_ SG_ 707 VCRIGHT_windowPositionRF "Right body controller: window position RF; raw 1 = signal not available (SNA)";
CM_ SG_ 707 VCRIGHT_windowCalibratedRF "Calibration status of right front window motor";
CM_ SG_ 707 VCRIGHT_windowStateRR "Status of right rear window motor";
CM_ SG_ 707 VCRIGHT_windowDutyRR "Right body controller: window duty RR";
CM_ SG_ 707 VCRIGHT_windowCurrentRR "Current drawn by left rear window regulator";
CM_ SG_ 707 VCRIGHT_windowPositionRR "Right body controller: window position RR";
CM_ SG_ 707 VCRIGHT_windowCalibratedRR "Calibration status of right rear window motor";
CM_ SG_ 707 VCRIGHT_windowThermalTCRF "Right body controller: window thermal TCRF";
CM_ SG_ 707 VCRIGHT_windowThermalModeRF "Right body controller: window thermal mode RF; raw 0 = signal not available (SNA)";
CM_ SG_ 707 VCRIGHT_windowStopReasonRF "Reason for right front window stopping motion";
CM_ SG_ 707 VCRIGHT_windowStopReqReasonRF "Reason for right front window stopping motion";
CM_ SG_ 707 VCRIGHT_windowThermalTCRR "Right body controller: window thermal TCRR";
CM_ SG_ 707 VCRIGHT_windowThermalModeRR "Right body controller: window thermal mode RR; raw 0 = signal not available (SNA)";
CM_ SG_ 707 VCRIGHT_windowStopReasonRR "Reason for right rear window stopping motion";
CM_ SG_ 707 VCRIGHT_windowStopReqReasonRR "Reason for right rear window stopping motion";
CM_ SG_ 707 VCRIGHT_windowControlStateRF "Window control state";
CM_ SG_ 707 VCRIGHT_windowCtrlUnavailableRF "Window control unavailable reason";
CM_ SG_ 707 VCRIGHT_windowControlStateRR "Window control state";
CM_ SG_ 707 VCRIGHT_windowCtrlUnavailableRR "Window control unavailable reason";
CM_ SG_ 707 VCRIGHT_windowPositionStateRF "Reports the window position state";
CM_ SG_ 707 VCRIGHT_windowPositionStateRR "Window position state";
CM_ SG_ 707 VCRIGHT_windowVehGearStateRF "Window's interpretation of vehicle gear state; raw 0 = signal not available (SNA)";
CM_ SG_ 707 VCRIGHT_windowVehGearStateRR "Window's interpretation of vehicle gear state; raw 0 = signal not available (SNA)";
CM_ SG_ 707 VCRIGHT_windowSpeedTableStatusRF "Speed table build status of right front window; raw 0 = signal not available (SNA)";
CM_ SG_ 707 VCRIGHT_windowSpeedTableStatusRR "Speed table build status of right rear window; raw 0 = signal not available (SNA)";
CM_ BO_ 1375 "VCSEAT2L ECU message: alert log; frame length from the layout, not yet observed on a vehicle bus";
CM_ SG_ 1375 VCSEAT2L_alertID "VCSEAT2L ECU: alert ID";
CM_ SG_ 1375 VCSEAT2L_alertState "VCSEAT2L ECU: alert state";
CM_ SG_ 1375 VCSEAT2L_a001_InternalWatchdog "VCSEAT2L ECU: a001 internal watchdog";
CM_ SG_ 1375 VCSEAT2L_a010_UnderVoltDetected "VCSEAT2L ECU: a010 under volt detected";
CM_ SG_ 1375 VCSEAT2L_a010_UnderVoltTimeout "VCSEAT2L ECU: a010 under volt timeout";
CM_ SG_ 1375 VCSEAT2L_a015_NVMMMemOverflow "VCSEAT2L ECU: a015 NVMM mem overflow";
CM_ SG_ 1375 VCSEAT2L_a015_NVMMFilesystemErro "VCSEAT2L ECU: a015 NVMM filesystem error";
CM_ SG_ 1375 VCSEAT2L_a015_NVMMRecordIDError "VCSEAT2L ECU: a015 NVMM record ID error";
CM_ SG_ 1375 VCSEAT2L_a057_VEH_cpControl "VCSEAT2L ECU: a057 VEH cp control";
CM_ SG_ 1375 VCSEAT2L_a059_voltageDrop "VCSEAT2L ECU: a059 voltage drop";
CM_ SG_ 1375 VCSEAT2L_a059_resistanceEstimate "VCSEAT2L ECU: a059 resistance estimate";
CM_ SG_ 1375 VCSEAT2L_a059_current "VCSEAT2L ECU: a059 current";
CM_ SG_ 1375 VCSEAT2L_a063_switchChannel "VCSEAT2L ECU: a063 switch channel";
CM_ SG_ 1375 VCSEAT2L_a063_switchType "VCSEAT2L ECU: a063 switch type";
CM_ SG_ 1375 VCSEAT2L_a063_ADCVoltage "VCSEAT2L ECU: a063 ADC voltage";
CM_ SG_ 1375 VCSEAT2L_a063_disconnected "VCSEAT2L ECU: a063 disconnected";
CM_ SG_ 1375 VCSEAT2L_a063_indeterminate "VCSEAT2L ECU: a063 indeterminate";
CM_ SG_ 1375 VCSEAT2L_a063_stuckActive "VCSEAT2L ECU: a063 stuck active";
CM_ SG_ 1375 VCSEAT2L_a063_faulted "VCSEAT2L ECU: a063 faulted";
CM_ SG_ 1375 VCSEAT2L_a082_RIPC_epbPrivateSta "VCSEAT2L ECU: a082 RIPC epb private state";
CM_ SG_ 1375 VCSEAT2L_a082_RIPC_remoteHSD "VCSEAT2L ECU: a082 RIPC remote HSD";
CM_ SG_ 1375 VCSEAT2L_a082_RIPC_railStatus "VCSEAT2L ECU: a082 RIPC rail status";
CM_ SG_ 1375 VCSEAT2L_a082_RIPC_remoteMux "VCSEAT2L ECU: a082 RIPC remote mux";
CM_ SG_ 1375 VCSEAT2L_a083_LIPC_epbPrivateSta "VCSEAT2L ECU: a083 LIPC epb private state";
CM_ SG_ 1375 VCSEAT2L_a083_LIPC_remoteHSD "VCSEAT2L ECU: a083 LIPC remote HSD";
CM_ SG_ 1375 VCSEAT2L_a083_LIPC_railStatus "VCSEAT2L ECU: a083 LIPC rail status";
CM_ SG_ 1375 VCSEAT2L_a083_LIPC_HSDFaults "VCSEAT2L ECU: a083 LIPC HSD faults";
CM_ SG_ 1375 VCSEAT2L_a084_CH_StatusC "VCSEAT2L ECU: a084 CH status c";
CM_ SG_ 1375 VCSEAT2L_a085_PARTY_buttonStatus "VCSEAT2L ECU: a085 PARTY button status";
CM_ SG_ 1375 VCSEAT2L_a086_VEH_LVBMS_statusHi "VCSEAT2L ECU: a086 VEH LVBMS status high";
CM_ SG_ 1375 VCSEAT2L_a086_VEH_LVBMS_statusLo "VCSEAT2L ECU: a086 VEH LVBMS status low";
CM_ SG_ 1375 VCSEAT2L_a086_VEH_status "VCSEAT2L ECU: a086 VEH status";
CM_ SG_ 1375 VCSEAT2L_a086_VEH_12VBatteryStat "VCSEAT2L ECU: a086 VEH 12 v battery status";
CM_ SG_ 1375 VCSEAT2L_a086_VEH_LVPowerState "VCSEAT2L ECU: a086 VEH LV power state";
CM_ SG_ 1375 VCSEAT2L_a086_VEH_lightStatus "VCSEAT2L ECU: a086 VEH light status";
CM_ SG_ 1375 VCSEAT2L_a086_VEH_systemStatus "VCSEAT2L ECU: a086 VEH system status";
CM_ SG_ 1375 VCSEAT2L_a086_VEH_thermalStatus "VCSEAT2L ECU: a086 VEH thermal status";
CM_ SG_ 1375 VCSEAT2L_a086_VEH_vehNm "VCSEAT2L ECU: a086 VEH veh nm";
CM_ SG_ 1375 VCSEAT2L_a087_VEH_temperature "VCSEAT2L ECU: a087 VEH temperature";
CM_ SG_ 1375 VCSEAT2L_a087_VEH_thermalControl "VCSEAT2L ECU: a087 VEH thermal control";
CM_ SG_ 1375 VCSEAT2L_a087_VEH_torque "VCSEAT2L ECU: a087 VEH torque";
CM_ SG_ 1375 VCSEAT2L_a087_VEH_status "VCSEAT2L ECU: a087 VEH status";
CM_ SG_ 1375 VCSEAT2L_a087_PARTY_torque "VCSEAT2L ECU: a087 PARTY torque";
CM_ SG_ 1375 VCSEAT2L_a087_PARTY_status "VCSEAT2L ECU: a087 PARTY status";
CM_ SG_ 1375 VCSEAT2L_a087_PARTY_temperature "VCSEAT2L ECU: a087 PARTY temperature";
CM_ SG_ 1375 VCSEAT2L_a087_PARTY_thermalContr "VCSEAT2L ECU: a087 PARTY thermal control";
CM_ SG_ 1375 VCSEAT2L_a087_VEH_motorStatus "VCSEAT2L ECU: a087 VEH motor status";
CM_ SG_ 1375 VCSEAT2L_a088_VEH_temperature "VCSEAT2L ECU: a088 VEH temperature";
CM_ SG_ 1375 VCSEAT2L_a088_VEH_thermalControl "VCSEAT2L ECU: a088 VEH thermal control";
CM_ SG_ 1375 VCSEAT2L_a088_VEH_torque "VCSEAT2L ECU: a088 VEH torque";
CM_ SG_ 1375 VCSEAT2L_a088_VEH_status "VCSEAT2L ECU: a088 VEH status";
CM_ SG_ 1375 VCSEAT2L_a088_PARTY_torque "VCSEAT2L ECU: a088 PARTY torque";
CM_ SG_ 1375 VCSEAT2L_a088_PARTY_status "VCSEAT2L ECU: a088 PARTY status";
CM_ SG_ 1375 VCSEAT2L_a088_PARTY_temperature "VCSEAT2L ECU: a088 PARTY temperature";
CM_ SG_ 1375 VCSEAT2L_a088_PARTY_thermalContr "VCSEAT2L ECU: a088 PARTY thermal control";
CM_ SG_ 1375 VCSEAT2L_a088_VEH_motorStatus "VCSEAT2L ECU: a088 VEH motor status";
CM_ SG_ 1375 VCSEAT2L_a089_PARTY_party1 "VCSEAT2L ECU: a089 PARTY party1";
CM_ SG_ 1375 VCSEAT2L_a089_PARTY_status "VCSEAT2L ECU: a089 PARTY status";
CM_ SG_ 1375 VCSEAT2L_a089_VEH_status "VCSEAT2L ECU: a089 VEH status";
CM_ SG_ 1375 VCSEAT2L_a089_BDY_party1 "VCSEAT2L ECU: a089 BDY party1";
CM_ SG_ 1375 VCSEAT2L_a089_BDY_status "VCSEAT2L ECU: a089 BDY status";
CM_ SG_ 1375 VCSEAT2L_a089_CH_status "VCSEAT2L ECU: a089 CH status";
CM_ SG_ 1375 VCSEAT2L_a089_CH_party1 "VCSEAT2L ECU: a089 CH party1";
CM_ SG_ 1375 VCSEAT2L_a089_CH_party3 "VCSEAT2L ECU: a089 CH party3";
CM_ SG_ 1375 VCSEAT2L_a089_VEH_party1 "VCSEAT2L ECU: a089 VEH party1";
CM_ SG_ 1375 VCSEAT2L_a089_VEH_party3 "VCSEAT2L ECU: a089 VEH party3";
CM_ SG_ 1375 VCSEAT2L_a091_VEH_faultsAndExtra "VCSEAT2L ECU: a091 VEH faults and extras";
CM_ SG_ 1375 VCSEAT2L_a091_VEH_info "VCSEAT2L ECU: a091 VEH info";
CM_ SG_ 1375 VCSEAT2L_a091_VEH_state "VCSEAT2L ECU: a091 VEH state";
CM_ SG_ 1375 VCSEAT2L_a092_VEH_restraintStatu "VCSEAT2L ECU: a092 VEH restraint status";
CM_ SG_ 1375 VCSEAT2L_a092_VEH_switchStatus "VCSEAT2L ECU: a092 VEH switch status";
CM_ SG_ 1375 VCSEAT2L_a092_VEH_seatStatus2 "VCSEAT2L ECU: a092 VEH seat status2";
CM_ SG_ 1375 VCSEAT2L_a092_VEH_vehNm "VCSEAT2L ECU: a092 VEH veh nm";
CM_ SG_ 1375 VCSEAT2L_a093_VEH_restraintStatu "VCSEAT2L ECU: a093 VEH restraint status";
CM_ SG_ 1375 VCSEAT2L_a093_VEH_switchStatus "VCSEAT2L ECU: a093 VEH switch status";
CM_ SG_ 1375 VCSEAT2L_a093_VEH_seatStatus2 "VCSEAT2L ECU: a093 VEH seat status2";
CM_ SG_ 1375 VCSEAT2L_a093_VEH_vehNm "VCSEAT2L ECU: a093 VEH veh nm";
CM_ SG_ 1375 VCSEAT2L_a094_VEH_sysStatus "VCSEAT2L ECU: a094 VEH sys status";
CM_ SG_ 1375 VCSEAT2L_a094_PARTY_sysStatus "VCSEAT2L ECU: a094 PARTY sys status";
CM_ SG_ 1375 VCSEAT2L_a094_CH_sysStatus "VCSEAT2L ECU: a094 CH sys status";
CM_ SG_ 1375 VCSEAT2L_a095_PT_ptNm "VCSEAT2L ECU: a095 PT pt nm";
CM_ SG_ 1375 VCSEAT2L_a095_PT_status "VCSEAT2L ECU: a095 PT status";
CM_ SG_ 1375 VCSEAT2L_a096_VEH_status "VCSEAT2L ECU: a096 VEH status";
CM_ SG_ 1375 VCSEAT2L_a096_CH_status "VCSEAT2L ECU: a096 CH status";
CM_ SG_ 1375 VCSEAT2L_a097_VEH_HVStatus "VCSEAT2L ECU: a097 VEH HV status";
CM_ SG_ 1375 VCSEAT2L_a097_VEH_state "VCSEAT2L ECU: a097 VEH state";
CM_ SG_ 1375 VCSEAT2L_a098_CH_torque "VCSEAT2L ECU: a098 CH torque";
CM_ SG_ 1375 VCSEAT2L_a098_VEH_hvStatus "VCSEAT2L ECU: a098 VEH hv status";
CM_ SG_ 1375 VCSEAT2L_a098_VEH_status "VCSEAT2L ECU: a098 VEH status";
CM_ SG_ 1375 VCSEAT2L_a098_VEH_thermalControl "VCSEAT2L ECU: a098 VEH thermal control";
CM_ SG_ 1375 VCSEAT2L_a098_VEH_temperature "VCSEAT2L ECU: a098 VEH temperature";
CM_ SG_ 1375 VCSEAT2L_a098_VEH_torque "VCSEAT2L ECU: a098 VEH torque";
CM_ SG_ 1375 VCSEAT2L_a098_PARTY_status "VCSEAT2L ECU: a098 PARTY status";
CM_ SG_ 1375 VCSEAT2L_a098_PARTY_temperature "VCSEAT2L ECU: a098 PARTY temperature";
CM_ SG_ 1375 VCSEAT2L_a098_PARTY_thermalContr "VCSEAT2L ECU: a098 PARTY thermal control";
CM_ SG_ 1375 VCSEAT2L_a098_PARTY_torque "VCSEAT2L ECU: a098 PARTY torque";
CM_ SG_ 1375 VCSEAT2L_a098_PT_thermalControl "VCSEAT2L ECU: a098 PT thermal control";
CM_ SG_ 1375 VCSEAT2L_a098_PT_temperature "VCSEAT2L ECU: a098 PT temperature";
CM_ SG_ 1375 VCSEAT2L_a098_PARTY_motorStatus "VCSEAT2L ECU: a098 PARTY motor status";
CM_ SG_ 1375 VCSEAT2L_a098_VEH_motorStatus "VCSEAT2L ECU: a098 VEH motor status";
CM_ SG_ 1375 VCSEAT2L_a099_VEH_oocStatus "VCSEAT2L ECU: a099 VEH ooc status";
CM_ SG_ 1375 VCSEAT2L_a100_VEH "VCSEAT2L ECU: a100 VEH";
CM_ SG_ 1375 VCSEAT2L_a100_PARTY "VCSEAT2L ECU: a100 PARTY";
CM_ SG_ 1375 VCSEAT2L_a100_PT "VCSEAT2L ECU: a100 PT";
CM_ SG_ 1375 VCSEAT2L_a100_CH "VCSEAT2L ECU: a100 CH";
CM_ SG_ 1375 VCSEAT2L_a100_OBD "VCSEAT2L ECU: a100 OBD";
CM_ SG_ 1375 VCSEAT2L_a101_VEH_state "VCSEAT2L ECU: a101 VEH state";
CM_ SG_ 1375 VCSEAT2L_a101_PARTY_locState "VCSEAT2L ECU: a101 PARTY loc state";
CM_ SG_ 1375 VCSEAT2L_a101_LIPC_externalWatch "VCSEAT2L ECU: a101 LIPC external watchdog heart beat";
CM_ SG_ 1375 VCSEAT2L_a101_VEH_locState "VCSEAT2L ECU: a101 VEH loc state";
CM_ SG_ 1375 VCSEAT2L_a101_BDY_locState "VCSEAT2L ECU: a101 BDY loc state";
CM_ SG_ 1375 VCSEAT2L_a102_VEH_faultsAndExtra "VCSEAT2L ECU: a102 VEH faults and extras";
CM_ SG_ 1375 VCSEAT2L_a102_VEH_feedbackStatus "VCSEAT2L ECU: a102 VEH feedback status";
CM_ SG_ 1375 VCSEAT2L_a102_VEH_sensorStatus "VCSEAT2L ECU: a102 VEH sensor status";
CM_ SG_ 1375 VCSEAT2L_a102_VEH_rods "VCSEAT2L ECU: a102 VEH rods";
CM_ SG_ 1375 VCSEAT2L_a103_VEH_hvsNm "VCSEAT2L ECU: a103 VEH hvs nm";
CM_ SG_ 1375 VCSEAT2L_a103_VEH_vehNm "VCSEAT2L ECU: a103 VEH veh nm";
CM_ SG_ 1375 VCSEAT2L_a103_VEH_status "VCSEAT2L ECU: a103 VEH status";
CM_ SG_ 1375 VCSEAT2L_a103_PT_ptNm "VCSEAT2L ECU: a103 PT pt nm";
CM_ SG_ 1375 VCSEAT2L_a103_PT_status "VCSEAT2L ECU: a103 PT status";
CM_ SG_ 1375 VCSEAT2L_a103_VEH_evseStatus "VCSEAT2L ECU: a103 VEH evse status";
CM_ SG_ 1375 VCSEAT2L_a105_VEH_states "VCSEAT2L ECU: a105 VEH states";
CM_ SG_ 1375 VCSEAT2L_a105_VEH_chNm "VCSEAT2L ECU: a105 VEH ch nm";
CM_ SG_ 1375 VCSEAT2L_a105_VEH_dampingStates "VCSEAT2L ECU: a105 VEH damping states";
CM_ SG_ 1375 VCSEAT2L_a106_VEH_dcdcStatus "VCSEAT2L ECU: a106 VEH dcdc status";
CM_ SG_ 1375 VCSEAT2L_a106_VEH_thermalControl "VCSEAT2L ECU: a106 VEH thermal control";
CM_ SG_ 1375 VCSEAT2L_a106_VEH_dcdcRailStatus "VCSEAT2L ECU: a106 VEH dcdc rail status";
CM_ SG_ 1375 VCSEAT2L_a106_CH_dcdcRailStatus "VCSEAT2L ECU: a106 CH dcdc rail status";
CM_ SG_ 1375 VCSEAT2L_a106_CH_alertMatrix "VCSEAT2L ECU: a106 CH alert matrix";
CM_ SG_ 1375 VCSEAT2L_a107_VEH_hvsNm "VCSEAT2L ECU: a107 VEH hvs nm";
CM_ SG_ 1375 VCSEAT2L_a107_VEH_vehNm "VCSEAT2L ECU: a107 VEH veh nm";
CM_ SG_ 1375 VCSEAT2L_a107_VEH_status "VCSEAT2L ECU: a107 VEH status";
CM_ SG_ 1375 VCSEAT2L_a107_VEH_thermalStatus "VCSEAT2L ECU: a107 VEH thermal status";
CM_ SG_ 1375 VCSEAT2L_a107_VEH_bmbMinMax "VCSEAT2L ECU: a107 VEH bmb min max";
CM_ SG_ 1375 VCSEAT2L_a107_VEH_powerAvailable "VCSEAT2L ECU: a107 VEH power available";
CM_ SG_ 1375 VCSEAT2L_a107_PT_ptNm "VCSEAT2L ECU: a107 PT pt nm";
CM_ SG_ 1375 VCSEAT2L_a107_PT_status "VCSEAT2L ECU: a107 PT status";
CM_ SG_ 1375 VCSEAT2L_a107_PT_thermalStatus "VCSEAT2L ECU: a107 PT thermal status";
CM_ SG_ 1375 VCSEAT2L_a107_PT_socStatus "VCSEAT2L ECU: a107 PT soc status";
CM_ SG_ 1375 VCSEAT2L_a107_VEH_socStatus "VCSEAT2L ECU: a107 VEH soc status";
CM_ SG_ 1375 VCSEAT2L_a107_VEH_packConfig "VCSEAT2L ECU: a107 VEH pack config";
CM_ SG_ 1375 VCSEAT2L_a107_VEH_energyStatus "VCSEAT2L ECU: a107 VEH energy status";
CM_ SG_ 1375 VCSEAT2L_a107_VEH_chargeInfo "VCSEAT2L ECU: a107 VEH charge info";
CM_ SG_ 1375 VCSEAT2L_a108_VEH_hvStatus "VCSEAT2L ECU: a108 VEH hv status";
CM_ SG_ 1375 VCSEAT2L_a108_VEH_temperature "VCSEAT2L ECU: a108 VEH temperature";
CM_ SG_ 1375 VCSEAT2L_a108_VEH_thermalControl "VCSEAT2L ECU: a108 VEH thermal control";
CM_ SG_ 1375 VCSEAT2L_a108_VEH_torque "VCSEAT2L ECU: a108 VEH torque";
CM_ SG_ 1375 VCSEAT2L_a108_VEH_status "VCSEAT2L ECU: a108 VEH status";
CM_ SG_ 1375 VCSEAT2L_a108_PARTY_torque "VCSEAT2L ECU: a108 PARTY torque";
CM_ SG_ 1375 VCSEAT2L_a108_PARTY_status "VCSEAT2L ECU: a108 PARTY status";
CM_ SG_ 1375 VCSEAT2L_a108_PARTY_temperature "VCSEAT2L ECU: a108 PARTY temperature";
CM_ SG_ 1375 VCSEAT2L_a108_PARTY_thermalContr "VCSEAT2L ECU: a108 PARTY thermal control";
CM_ SG_ 1375 VCSEAT2L_a108_PT_temperature "VCSEAT2L ECU: a108 PT temperature";
CM_ SG_ 1375 VCSEAT2L_a108_PT_thermalControl "VCSEAT2L ECU: a108 PT thermal control";
CM_ SG_ 1375 VCSEAT2L_a108_PARTY_motorStatus "VCSEAT2L ECU: a108 PARTY motor status";
CM_ SG_ 1375 VCSEAT2L_a108_VEH_motorStatus "VCSEAT2L ECU: a108 VEH motor status";
CM_ SG_ 1375 VCSEAT2L_a108_CH_torque "VCSEAT2L ECU: a108 CH torque";
CM_ SG_ 1375 VCSEAT2L_a110_VEH_carState "VCSEAT2L ECU: a110 VEH car state";
CM_ SG_ 1375 VCSEAT2L_a110_VEH_carConfig "VCSEAT2L ECU: a110 VEH car config";
CM_ SG_ 1375 VCSEAT2L_a110_VEH_time "VCSEAT2L ECU: a110 VEH time";
CM_ SG_ 1375 VCSEAT2L_a110_VEH_updateStatus "VCSEAT2L ECU: a110 VEH update status";
CM_ SG_ 1375 VCSEAT2L_a110_VEH_vehNm "VCSEAT2L ECU: a110 VEH veh nm";
CM_ SG_ 1375 VCSEAT2L_a110_VEH_mismatchFault "VCSEAT2L ECU: a110 VEH mismatch fault";
CM_ SG_ 1375 VCSEAT2L_a110_VEH_vin "VCSEAT2L ECU: a110 VEH vin";
CM_ SG_ 1375 VCSEAT2L_a110_VEH_bmpDebug "VCSEAT2L ECU: a110 VEH bmp debug";
CM_ SG_ 1375 VCSEAT2L_a110_VEH_gearControl "VCSEAT2L ECU: a110 VEH gear control";
CM_ SG_ 1375 VCSEAT2L_a110_VEH_canLogAvailabi "VCSEAT2L ECU: a110 VEH can log availability";
CM_ SG_ 1375 VCSEAT2L_a110_CH_airbagCutoffSta "VCSEAT2L ECU: a110 CH airbag cutoff status";
CM_ SG_ 1375 VCSEAT2L_a110_CH_carConfig "VCSEAT2L ECU: a110 CH car config";
CM_ SG_ 1375 VCSEAT2L_a110_CH_carState "VCSEAT2L ECU: a110 CH car state";
CM_ SG_ 1375 VCSEAT2L_a110_CH_vin "VCSEAT2L ECU: a110 CH vin";
CM_ SG_ 1375 VCSEAT2L_a110_CH_chNm "VCSEAT2L ECU: a110 CH ch nm";
CM_ SG_ 1375 VCSEAT2L_a110_CH_epochTimeGtw "VCSEAT2L ECU: a110 CH epoch time gtw";
CM_ SG_ 1375 VCSEAT2L_a110_PARTY_carConfig "VCSEAT2L ECU: a110 PARTY car config";
CM_ SG_ 1375 VCSEAT2L_a111_VEH_internalStatus "VCSEAT2L ECU: a111 VEH internal status";
CM_ SG_ 1375 VCSEAT2L_a111_VEH_status "VCSEAT2L ECU: a111 VEH status";
CM_ SG_ 1375 VCSEAT2L_a111_VEH_vehNm "VCSEAT2L ECU: a111 VEH veh nm";
CM_ SG_ 1375 VCSEAT2L_a111_RIPC_LVPowerState "VCSEAT2L ECU: a111 RIPC LV power state";
CM_ SG_ 1375 VCSEAT2L_a111_RIPC_epbPrivateSta "VCSEAT2L ECU: a111 RIPC epb private state";
CM_ SG_ 1375 VCSEAT2L_a111_RIPC_railStatus "VCSEAT2L ECU: a111 RIPC rail status";
CM_ SG_ 1375 VCSEAT2L_a111_RIPC_remoteADC "VCSEAT2L ECU: a111 RIPC remote ADC";
CM_ SG_ 1375 VCSEAT2L_a111_RIPC_switchStatus "VCSEAT2L ECU: a111 RIPC switch status";
CM_ SG_ 1375 VCSEAT2L_a111_VEH_LVPowerState "VCSEAT2L ECU: a111 VEH LV power state";
CM_ SG_ 1375 VCSEAT2L_a111_VEH_seatStatus "VCSEAT2L ECU: a111 VEH seat status";
CM_ SG_ 1375 VCSEAT2L_a111_PARTY_status "VCSEAT2L ECU: a111 PARTY status";
CM_ SG_ 1375 VCSEAT2L_a111_CH_status "VCSEAT2L ECU: a111 CH status";
CM_ SG_ 1375 VCSEAT2L_a112_VEH_internalStatus "VCSEAT2L ECU: a112 VEH internal status";
CM_ SG_ 1375 VCSEAT2L_a112_VEH_status "VCSEAT2L ECU: a112 VEH status";
CM_ SG_ 1375 VCSEAT2L_a112_VEH_vehNm "VCSEAT2L ECU: a112 VEH veh nm";
CM_ SG_ 1375 VCSEAT2L_a112_LIPC_LVPowerState "VCSEAT2L ECU: a112 LIPC LV power state";
CM_ SG_ 1375 VCSEAT2L_a112_LIPC_epbPrivateSta "VCSEAT2L ECU: a112 LIPC epb private state";
CM_ SG_ 1375 VCSEAT2L_a112_LIPC_railStatus "VCSEAT2L ECU: a112 LIPC rail status";
CM_ SG_ 1375 VCSEAT2L_a112_LIPC_remoteADC "VCSEAT2L ECU: a112 LIPC remote ADC";
CM_ SG_ 1375 VCSEAT2L_a112_LIPC_switchStatus "VCSEAT2L ECU: a112 LIPC switch status";
CM_ SG_ 1375 VCSEAT2L_a112_VEH_LVPowerState "VCSEAT2L ECU: a112 VEH LV power state";
CM_ SG_ 1375 VCSEAT2L_a112_PARTY_status "VCSEAT2L ECU: a112 PARTY status";
CM_ SG_ 1375 VCSEAT2L_a112_CH_status "VCSEAT2L ECU: a112 CH status";
CM_ SG_ 1375 VCSEAT2L_a114_PARTY_status "VCSEAT2L ECU: a114 PARTY status";
CM_ SG_ 1375 VCSEAT2L_a114_PARTY_wheelSpeeds "VCSEAT2L ECU: a114 PARTY wheel speeds";
CM_ SG_ 1375 VCSEAT2L_a114_VEH_wheelSpeeds "VCSEAT2L ECU: a114 VEH wheel speeds";
CM_ SG_ 1375 VCSEAT2L_a114_CH_wheelSpeeds "VCSEAT2L ECU: a114 CH wheel speeds";
CM_ SG_ 1375 VCSEAT2L_a114_PARTY_party3 "VCSEAT2L ECU: a114 PARTY party3";
CM_ SG_ 1375 VCSEAT2L_a114_VEH_party3 "VCSEAT2L ECU: a114 VEH party3";
CM_ SG_ 1375 VCSEAT2L_a114_VEH_status "VCSEAT2L ECU: a114 VEH status";
CM_ SG_ 1375 VCSEAT2L_a114_PARTY_wheelRotatio "VCSEAT2L ECU: a114 PARTY wheel rotation";
CM_ SG_ 1375 VCSEAT2L_a114_CH_wheelRotation "VCSEAT2L ECU: a114 CH wheel rotation";
CM_ SG_ 1375 VCSEAT2L_a114_VEH_wheelRotation "VCSEAT2L ECU: a114 VEH wheel rotation";
CM_ SG_ 1375 VCSEAT2L_a114_PARTY_brakeTorque "VCSEAT2L ECU: a114 PARTY brake torque";
CM_ SG_ 1375 VCSEAT2L_a114_PARTY_offsets "VCSEAT2L ECU: a114 PARTY offsets";
CM_ SG_ 1375 VCSEAT2L_a114_BDY_offsets "VCSEAT2L ECU: a114 BDY offsets";
CM_ SG_ 1375 VCSEAT2L_a114_BDY_party3 "VCSEAT2L ECU: a114 BDY party3";
CM_ SG_ 1375 VCSEAT2L_a114_BDY_status "VCSEAT2L ECU: a114 BDY status";
CM_ SG_ 1375 VCSEAT2L_a114_BDY_wheelRotation "VCSEAT2L ECU: a114 BDY wheel rotation";
CM_ SG_ 1375 VCSEAT2L_a114_BDY_wheelSpeeds "VCSEAT2L ECU: a114 BDY wheel speeds";
CM_ SG_ 1375 VCSEAT2L_a114_CH_party1 "VCSEAT2L ECU: a114 CH party1";
CM_ SG_ 1375 VCSEAT2L_a114_CH_party3 "VCSEAT2L ECU: a114 CH party3";
CM_ SG_ 1375 VCSEAT2L_a114_CH_status "VCSEAT2L ECU: a114 CH status";
CM_ SG_ 1375 VCSEAT2L_a115_VEH_vehNm "VCSEAT2L ECU: a115 VEH veh nm";
CM_ SG_ 1375 VCSEAT2L_a115_VEH_authentication "VCSEAT2L ECU: a115 VEH authentication";
CM_ SG_ 1375 VCSEAT2L_a115_VEH_BLEResetReques "VCSEAT2L ECU: a115 VEH BLE reset request";
CM_ SG_ 1375 VCSEAT2L_a115_VEH_requests "VCSEAT2L ECU: a115 VEH requests";
CM_ SG_ 1375 VCSEAT2L_a115_VEH_requests2 "VCSEAT2L ECU: a115 VEH requests2";
CM_ SG_ 1375 VCSEAT2L_a115_REM_authentication "VCSEAT2L ECU: a115 REM authentication";
CM_ SG_ 1375 VCSEAT2L_a115_UI_corianderVehicl "VCSEAT2L ECU: a115 UI coriander vehicle control";
CM_ SG_ 1375 VCSEAT2L_a115_CH_TPMSDisplay "VCSEAT2L ECU: a115 CH TPMS display";
CM_ SG_ 1375 VCSEAT2L_a116_PARTY_epbmStatus "VCSEAT2L ECU: a116 PARTY epbm status";
CM_ SG_ 1375 VCSEAT2L_a116_VEH_vehNm "VCSEAT2L ECU: a116 VEH veh nm";
CM_ SG_ 1375 VCSEAT2L_a116_VEH_hvacRequest "VCSEAT2L ECU: a116 VEH hvac request";
CM_ SG_ 1375 VCSEAT2L_a116_VEH_hvacStatus "VCSEAT2L ECU: a116 VEH hvac status";
CM_ SG_ 1375 VCSEAT2L_a116_VEH_LVPowerState "VCSEAT2L ECU: a116 VEH LV power state";
CM_ SG_ 1375 VCSEAT2L_a116_VEH_lightStatus "VCSEAT2L ECU: a116 VEH light status";
CM_ SG_ 1375 VCSEAT2L_a116_VEH_seatStatus "VCSEAT2L ECU: a116 VEH seat status";
CM_ SG_ 1375 VCSEAT2L_a116_VEH_thsStatus "VCSEAT2L ECU: a116 VEH ths status";
CM_ SG_ 1375 VCSEAT2L_a116_VEH_doorStatus "VCSEAT2L ECU: a116 VEH door status";
CM_ SG_ 1375 VCSEAT2L_a116_VEH_seatHeatStatus "VCSEAT2L ECU: a116 VEH seat heat status";
CM_ SG_ 1375 VCSEAT2L_a116_VEH_restraintStatu "VCSEAT2L ECU: a116 VEH restraint status";
CM_ SG_ 1375 VCSEAT2L_a116_VEH_switchStatus "VCSEAT2L ECU: a116 VEH switch status";
CM_ SG_ 1375 VCSEAT2L_a116_VEH_logging1Hz "VCSEAT2L ECU: a116 VEH logging1 hz";
CM_ SG_ 1375 VCSEAT2L_a116_VEH_seatStatus2 "VCSEAT2L ECU: a116 VEH seat status2";
CM_ SG_ 1375 VCSEAT2L_a116_VEH_status "VCSEAT2L ECU: a116 VEH status";
CM_ SG_ 1375 VCSEAT2L_a116_VEH_thermalCommand "VCSEAT2L ECU: a116 VEH thermal command";
CM_ SG_ 1375 VCSEAT2L_a116_VEH_windowStatus "VCSEAT2L ECU: a116 VEH window status";
CM_ SG_ 1375 VCSEAT2L_a116_PARTY_restraintSta "VCSEAT2L ECU: a116 PARTY restraint status";
CM_ SG_ 1375 VCSEAT2L_a116_PARTY_doorStatus "VCSEAT2L ECU: a116 PARTY door status";
CM_ SG_ 1375 VCSEAT2L_a116_BDY_epbmStatus "VCSEAT2L ECU: a116 BDY epbm status";
CM_ SG_ 1375 VCSEAT2L_a116_BDY_restraintStatu "VCSEAT2L ECU: a116 BDY restraint status";
CM_ SG_ 1375 VCSEAT2L_a116_BDY_switchStatus "VCSEAT2L ECU: a116 BDY switch status";
CM_ SG_ 1375 VCSEAT2L_a117_BDY_epbmStatus "VCSEAT2L ECU: a117 BDY epbm status";
CM_ SG_ 1375 VCSEAT2L_a117_BDY_restraintStatu "VCSEAT2L ECU: a117 BDY restraint status";
CM_ SG_ 1375 VCSEAT2L_a117_VEH_prndStatus "VCSEAT2L ECU: a117 VEH prnd status";
CM_ SG_ 1375 VCSEAT2L_a117_PARTY_epbmStatus "VCSEAT2L ECU: a117 PARTY epbm status";
CM_ SG_ 1375 VCSEAT2L_a117_VEH_vehNm "VCSEAT2L ECU: a117 VEH veh nm";
CM_ SG_ 1375 VCSEAT2L_a117_VEH_hvacBlowerFdb "VCSEAT2L ECU: a117 VEH hvac blower fdb";
CM_ SG_ 1375 VCSEAT2L_a117_VEH_LVPowerState "VCSEAT2L ECU: a117 VEH LV power state";
CM_ SG_ 1375 VCSEAT2L_a117_VEH_restraintStatu "VCSEAT2L ECU: a117 VEH restraint status";
CM_ SG_ 1375 VCSEAT2L_a117_VEH_lightStatus "VCSEAT2L ECU: a117 VEH light status";
CM_ SG_ 1375 VCSEAT2L_a117_VEH_seatStatus "VCSEAT2L ECU: a117 VEH seat status";
CM_ SG_ 1375 VCSEAT2L_a117_BDY_falconSwitchSt "VCSEAT2L ECU: a117 BDY falcon switch status";
CM_ SG_ 1375 VCSEAT2L_a117_VEH_doorStatus "VCSEAT2L ECU: a117 VEH door status";
CM_ SG_ 1375 VCSEAT2L_a117_VEH_doorStatus2 "VCSEAT2L ECU: a117 VEH door status2";
CM_ SG_ 1375 VCSEAT2L_a117_VEH_windowStatus "VCSEAT2L ECU: a117 VEH window status";
CM_ SG_ 1375 VCSEAT2L_a117_VEH_switchStatus "VCSEAT2L ECU: a117 VEH switch status";
CM_ SG_ 1375 VCSEAT2L_a117_VEH_intrusionSenso "VCSEAT2L ECU: a117 VEH intrusion sensor status";
CM_ SG_ 1375 VCSEAT2L_a117_VEH_liftgateStatus "VCSEAT2L ECU: a117 VEH liftgate status";
CM_ SG_ 1375 VCSEAT2L_a117_VEH_seatStatus2 "VCSEAT2L ECU: a117 VEH seat status2";
CM_ SG_ 1375 VCSEAT2L_a117_PARTY_restraintSta "VCSEAT2L ECU: a117 PARTY restraint status";
CM_ SG_ 1375 VCSEAT2L_a117_VEH_thermalStatus "VCSEAT2L ECU: a117 VEH thermal status";
CM_ SG_ 1375 VCSEAT2L_a117_PARTY_doorStatus "VCSEAT2L ECU: a117 PARTY door status";
CM_ SG_ 1375 VCSEAT2L_a117_VEH_status "VCSEAT2L ECU: a117 VEH status";
CM_ SG_ 1375 VCSEAT2L_a117_PARTY_prndStatus "VCSEAT2L ECU: a117 PARTY prnd status";
CM_ SG_ 1375 VCSEAT2L_a117_PARTY_lightingSeco "VCSEAT2L ECU: a117 PARTY lighting secondary";
CM_ SG_ 1375 VCSEAT2L_a118_VEH_vehNm "VCSEAT2L ECU: a118 VEH veh nm";
CM_ SG_ 1375 VCSEAT2L_a118_VEH_lighting "VCSEAT2L ECU: a118 VEH lighting";
CM_ SG_ 1375 VCSEAT2L_a118_VEH_sensors "VCSEAT2L ECU: a118 VEH sensors";
CM_ SG_ 1375 VCSEAT2L_a118_VEH_status "VCSEAT2L ECU: a118 VEH status";
CM_ SG_ 1375 VCSEAT2L_a118_VEH_okToUseHighPwr "VCSEAT2L ECU: a118 VEH ok to use high pwr";
CM_ SG_ 1375 VCSEAT2L_a118_VEH_LVPowerState "VCSEAT2L ECU: a118 VEH LV power state";
CM_ SG_ 1375 VCSEAT2L_a118_VEH_coolant "VCSEAT2L ECU: a118 VEH coolant";
CM_ SG_ 1375 VCSEAT2L_a118_VEH_vehicleStatus "VCSEAT2L ECU: a118 VEH vehicle status";
CM_ SG_ 1375 VCSEAT2L_a118_VEH_12VBatteryStat "VCSEAT2L ECU: a118 VEH 12 v battery status";
CM_ SG_ 1375 VCSEAT2L_a118_VEH_systemStatus "VCSEAT2L ECU: a118 VEH system status";
CM_ SG_ 1375 VCSEAT2L_a118_PARTY_LVPowerState "VCSEAT2L ECU: a118 PARTY LV power state";
CM_ SG_ 1375 VCSEAT2L_a118_PARTY_outputPowerS "VCSEAT2L ECU: a118 PARTY output power status";
CM_ SG_ 1375 VCSEAT2L_a118_PARTY_vehicleTime "VCSEAT2L ECU: a118 PARTY vehicle time";
CM_ SG_ 1375 VCSEAT2L_a118_VEH_thermalCommand "VCSEAT2L ECU: a118 VEH thermal command";
CM_ SG_ 1375 VCSEAT2L_a118_CH_LVPowerState "VCSEAT2L ECU: a118 CH LV power state";
CM_ SG_ 1375 VCSEAT2L_a118_PARTY_sensors "VCSEAT2L ECU: a118 PARTY sensors";
CM_ SG_ 1375 VCSEAT2L_a118_CH_sensors "VCSEAT2L ECU: a118 CH sensors";
CM_ SG_ 1375 VCSEAT2L_a118_VEH_interNodeResis "VCSEAT2L ECU: a118 VEH inter node resistance";
CM_ SG_ 1375 VCSEAT2L_a118_CH_lighting "VCSEAT2L ECU: a118 CH lighting";
CM_ SG_ 1375 VCSEAT2L_a118_VEH_lightStatus "VCSEAT2L ECU: a118 VEH light status";
CM_ SG_ 1375 VCSEAT2L_a118_PARTY_vehNm "VCSEAT2L ECU: a118 PARTY veh nm";
CM_ SG_ 1375 VCSEAT2L_a118_CH_12VBatteryStatu "VCSEAT2L ECU: a118 CH 12 v battery status";
CM_ SG_ 1375 VCSEAT2L_a118_CH_LVBMS_statusHig "VCSEAT2L ECU: a118 CH LVBMS status high";
CM_ SG_ 1375 VCSEAT2L_a118_CH_alertMatrix "VCSEAT2L ECU: a118 CH alert matrix";
CM_ SG_ 1375 VCSEAT2L_a118_BDY_outputPowerSta "VCSEAT2L ECU: a118 BDY output power status";
CM_ SG_ 1375 VCSEAT2L_a118_BDY_vehicleTime "VCSEAT2L ECU: a118 BDY vehicle time";
CM_ SG_ 1375 VCSEAT2L_a118_PARTY_AP_vehicleSt "VCSEAT2L ECU: a118 PARTY AP vehicle state1 hz muxed";
CM_ SG_ 1375 VCSEAT2L_a118_BDY_AP_vehicleStat "VCSEAT2L ECU: a118 BDY AP vehicle state1 hz muxed";
CM_ SG_ 1375 VCSEAT2L_a118_PARTY_VCFRONT_came "VCSEAT2L ECU: a118 PARTY VCFRONT camera cleaning status";
CM_ SG_ 1375 VCSEAT2L_a119_VEH_steerAngle "VCSEAT2L ECU: a119 VEH steer angle";
CM_ SG_ 1375 VCSEAT2L_a119_VEH_leftStalk "VCSEAT2L ECU: a119 VEH left stalk";
CM_ SG_ 1375 VCSEAT2L_a119_VEH_rightStalk "VCSEAT2L ECU: a119 VEH right stalk";
CM_ SG_ 1375 VCSEAT2L_a119_PARTY_rightStalk "VCSEAT2L ECU: a119 PARTY right stalk";
CM_ SG_ 1375 VCSEAT2L_a119_CH_steerAngle "VCSEAT2L ECU: a119 CH steer angle";
CM_ SG_ 1375 VCSEAT2L_a119_PARTY_steerAngle "VCSEAT2L ECU: a119 PARTY steer angle";
CM_ SG_ 1375 VCSEAT2L_a120_PARTY_chassisCntl "VCSEAT2L ECU: a120 PARTY chassis cntl";
CM_ SG_ 1375 VCSEAT2L_a120_VEH_systemStatus "VCSEAT2L ECU: a120 VEH system status";
CM_ SG_ 1375 VCSEAT2L_a120_CH_chassisCntl "VCSEAT2L ECU: a120 CH chassis cntl";
CM_ SG_ 1375 VCSEAT2L_a120_PARTY_systemStatus "VCSEAT2L ECU: a120 PARTY system status";
CM_ SG_ 1375 VCSEAT2L_a120_PARTY_torque "VCSEAT2L ECU: a120 PARTY torque";
CM_ SG_ 1375 VCSEAT2L_a120_VEH_torque "VCSEAT2L ECU: a120 VEH torque";
CM_ SG_ 1375 VCSEAT2L_a120_PARTY_locStatus "VCSEAT2L ECU: a120 PARTY loc status";
CM_ SG_ 1375 VCSEAT2L_a120_PARTY_speed "VCSEAT2L ECU: a120 PARTY speed";
CM_ SG_ 1375 VCSEAT2L_a120_VEH_speed "VCSEAT2L ECU: a120 VEH speed";
CM_ SG_ 1375 VCSEAT2L_a120_PARTY_status "VCSEAT2L ECU: a120 PARTY status";
CM_ SG_ 1375 VCSEAT2L_a120_PT_speed "VCSEAT2L ECU: a120 PT speed";
CM_ SG_ 1375 VCSEAT2L_a120_PT_systemStatus "VCSEAT2L ECU: a120 PT system status";
CM_ SG_ 1375 VCSEAT2L_a120_PARTY_vehicleEstim "VCSEAT2L ECU: a120 PARTY vehicle estimates";
CM_ SG_ 1375 VCSEAT2L_a120_VEH_aggregatedAxle "VCSEAT2L ECU: a120 VEH aggregated axle speed";
CM_ SG_ 1375 VCSEAT2L_a120_PARTY_aggregatedAx "VCSEAT2L ECU: a120 PARTY aggregated axle speed";
CM_ SG_ 1375 VCSEAT2L_a120_VEH_systemPower "VCSEAT2L ECU: a120 VEH system power";
CM_ SG_ 1375 VCSEAT2L_a120_PARTY_autonomyHeal "VCSEAT2L ECU: a120 PARTY autonomy health";
CM_ SG_ 1375 VCSEAT2L_a120_VEH_autonomyHealth "VCSEAT2L ECU: a120 VEH autonomy health";
CM_ SG_ 1375 VCSEAT2L_a120_PT_systemPower "VCSEAT2L ECU: a120 PT system power";
CM_ SG_ 1375 VCSEAT2L_a120_PARTY_stalklessInt "VCSEAT2L ECU: a120 PARTY stalkless interfaces";
CM_ SG_ 1375 VCSEAT2L_a120_CH_speed "VCSEAT2L ECU: a120 CH speed";
CM_ SG_ 1375 VCSEAT2L_a120_VEH_estimatedBrake "VCSEAT2L ECU: a120 VEH estimated brake temp";
CM_ SG_ 1375 VCSEAT2L_a120_PARTY_prndControl "VCSEAT2L ECU: a120 PARTY prnd control";
CM_ SG_ 1375 VCSEAT2L_a120_PARTY_locStatus2 "VCSEAT2L ECU: a120 PARTY loc status2";
CM_ SG_ 1375 VCSEAT2L_a120_VEH_chassisCntl "VCSEAT2L ECU: a120 VEH chassis cntl";
CM_ SG_ 1375 VCSEAT2L_a120_CH_locStatus2 "VCSEAT2L ECU: a120 CH loc status2";
CM_ SG_ 1375 VCSEAT2L_a120_VEH_locStatus "VCSEAT2L ECU: a120 VEH loc status";
CM_ SG_ 1375 VCSEAT2L_a120_VEH_locStatus2 "VCSEAT2L ECU: a120 VEH loc status2";
CM_ SG_ 1375 VCSEAT2L_a120_VEH_prndControl "VCSEAT2L ECU: a120 VEH prnd control";
CM_ SG_ 1375 VCSEAT2L_a120_VEH_vehicleEstimat "VCSEAT2L ECU: a120 VEH vehicle estimates";
CM_ SG_ 1375 VCSEAT2L_a120_PARTY_motorStatus "VCSEAT2L ECU: a120 PARTY motor status";
CM_ SG_ 1375 VCSEAT2L_a120_VEH_motorStatus "VCSEAT2L ECU: a120 VEH motor status";
CM_ SG_ 1375 VCSEAT2L_a120_BDY_speed "VCSEAT2L ECU: a120 BDY speed";
CM_ SG_ 1375 VCSEAT2L_a210_seatMotorCalibrate "VCSEAT2L ECU: a210 seat motor calibrated";
CM_ SG_ 1375 VCSEAT2L_a210_seatMotorCurrent "VCSEAT2L ECU: a210 seat motor current";
CM_ SG_ 1375 VCSEAT2L_a210_seatMotorState "VCSEAT2L ECU: a210 seat motor state";
CM_ SG_ 1375 VCSEAT2L_a210_seatSwitchBack "VCSEAT2L ECU: a210 seat switch back; raw 0 = signal not available (SNA)";
CM_ SG_ 1375 VCSEAT2L_a210_seatSwitchForward "VCSEAT2L ECU: a210 seat switch forward; raw 0 = signal not available (SNA)";
CM_ SG_ 1375 VCSEAT2L_a211_seatMotorCurrent "VCSEAT2L ECU: a211 seat motor current";
CM_ SG_ 1375 VCSEAT2L_a211_seatMotorPosReal "VCSEAT2L ECU: a211 seat motor pos real";
CM_ SG_ 1375 VCSEAT2L_a211_seatMotorState "VCSEAT2L ECU: a211 seat motor state";
CM_ SG_ 1375 VCSEAT2L_a211_seatSwitchBack "VCSEAT2L ECU: a211 seat switch back; raw 0 = signal not available (SNA)";
CM_ SG_ 1375 VCSEAT2L_a211_seatSwitchForward "VCSEAT2L ECU: a211 seat switch forward; raw 0 = signal not available (SNA)";
CM_ SG_ 1375 VCSEAT2L_a212_seatMotorCurrent "VCSEAT2L ECU: a212 seat motor current";
CM_ SG_ 1375 VCSEAT2L_a212_seatMotorPosReal "VCSEAT2L ECU: a212 seat motor pos real";
CM_ SG_ 1375 VCSEAT2L_a212_seatMotorState "VCSEAT2L ECU: a212 seat motor state";
CM_ SG_ 1375 VCSEAT2L_a212_seatSwitchBack "VCSEAT2L ECU: a212 seat switch back; raw 0 = signal not available (SNA)";
CM_ SG_ 1375 VCSEAT2L_a212_seatSwitchForward "VCSEAT2L ECU: a212 seat switch forward; raw 0 = signal not available (SNA)";
CM_ SG_ 1375 VCSEAT2L_a213_seatMotorCalibrate "VCSEAT2L ECU: a213 seat motor calibrated";
CM_ SG_ 1375 VCSEAT2L_a213_seatMotorCurrent "VCSEAT2L ECU: a213 seat motor current";
CM_ SG_ 1375 VCSEAT2L_a213_seatMotorPosReal "VCSEAT2L ECU: a213 seat motor pos real";
CM_ SG_ 1375 VCSEAT2L_a213_seatMotorState "VCSEAT2L ECU: a213 seat motor state";
CM_ SG_ 1375 VCSEAT2L_a213_seatSwitchBack "VCSEAT2L ECU: a213 seat switch back; raw 0 = signal not available (SNA)";
CM_ SG_ 1375 VCSEAT2L_a213_seatSwitchForward "VCSEAT2L ECU: a213 seat switch forward; raw 0 = signal not available (SNA)";
CM_ SG_ 1375 VCSEAT2L_a214_seatMotorCurrent "VCSEAT2L ECU: a214 seat motor current";
CM_ SG_ 1375 VCSEAT2L_a214_seatMotorDCurrent "VCSEAT2L ECU: a214 seat motor d current";
CM_ SG_ 1375 VCSEAT2L_a214_seatMotorPosReal "VCSEAT2L ECU: a214 seat motor pos real";
CM_ SG_ 1375 VCSEAT2L_a214_seatMotorState "VCSEAT2L ECU: a214 seat motor state";
CM_ SG_ 1375 VCSEAT2L_a215_seatMotorCurrent "VCSEAT2L ECU: a215 seat motor current";
CM_ SG_ 1375 VCSEAT2L_a215_seatMotorDCurrent "VCSEAT2L ECU: a215 seat motor d current";
CM_ SG_ 1375 VCSEAT2L_a215_seatMotorPosReal "VCSEAT2L ECU: a215 seat motor pos real";
CM_ SG_ 1375 VCSEAT2L_a215_seatMotorState "VCSEAT2L ECU: a215 seat motor state";
CM_ SG_ 1375 VCSEAT2L_a224_seatMotorCalibrate "VCSEAT2L ECU: a224 seat motor calibrated";
CM_ SG_ 1375 VCSEAT2L_a224_seatMotorCurrent "VCSEAT2L ECU: a224 seat motor current";
CM_ SG_ 1375 VCSEAT2L_a224_seatMotorState "VCSEAT2L ECU: a224 seat motor state";
CM_ SG_ 1375 VCSEAT2L_a224_seatSwitchBack "VCSEAT2L ECU: a224 seat switch back; raw 0 = signal not available (SNA)";
CM_ SG_ 1375 VCSEAT2L_a224_seatSwitchForward "VCSEAT2L ECU: a224 seat switch forward; raw 0 = signal not available (SNA)";
CM_ SG_ 1375 VCSEAT2L_a225_seatMotorCalibrate "VCSEAT2L ECU: a225 seat motor calibrated";
CM_ SG_ 1375 VCSEAT2L_a225_seatMotorCurrent "VCSEAT2L ECU: a225 seat motor current";
CM_ SG_ 1375 VCSEAT2L_a225_seatMotorState "VCSEAT2L ECU: a225 seat motor state";
CM_ SG_ 1375 VCSEAT2L_a225_seatSwitchBack "VCSEAT2L ECU: a225 seat switch back; raw 0 = signal not available (SNA)";
CM_ SG_ 1375 VCSEAT2L_a225_seatSwitchForward "VCSEAT2L ECU: a225 seat switch forward; raw 0 = signal not available (SNA)";
CM_ SG_ 1375 VCSEAT2L_a228_seatMotorCalibrate "VCSEAT2L ECU: a228 seat motor calibrated";
CM_ SG_ 1375 VCSEAT2L_a228_seatMotorCurrent "VCSEAT2L ECU: a228 seat motor current";
CM_ SG_ 1375 VCSEAT2L_a228_seatMotorPosReal "VCSEAT2L ECU: a228 seat motor pos real";
CM_ SG_ 1375 VCSEAT2L_a228_seatMotorState "VCSEAT2L ECU: a228 seat motor state";
CM_ SG_ 1375 VCSEAT2L_a228_seatSwitchBack "VCSEAT2L ECU: a228 seat switch back; raw 0 = signal not available (SNA)";
CM_ SG_ 1375 VCSEAT2L_a228_seatSwitchForward "VCSEAT2L ECU: a228 seat switch forward; raw 0 = signal not available (SNA)";
CM_ SG_ 1375 VCSEAT2L_a229_seatMotorCalibrate "VCSEAT2L ECU: a229 seat motor calibrated";
CM_ SG_ 1375 VCSEAT2L_a229_seatMotorCurrent "VCSEAT2L ECU: a229 seat motor current";
CM_ SG_ 1375 VCSEAT2L_a229_seatMotorPosReal "VCSEAT2L ECU: a229 seat motor pos real";
CM_ SG_ 1375 VCSEAT2L_a229_seatMotorState "VCSEAT2L ECU: a229 seat motor state";
CM_ SG_ 1375 VCSEAT2L_a229_seatSwitchBack "VCSEAT2L ECU: a229 seat switch back; raw 0 = signal not available (SNA)";
CM_ SG_ 1375 VCSEAT2L_a229_seatSwitchForward "VCSEAT2L ECU: a229 seat switch forward; raw 0 = signal not available (SNA)";
CM_ SG_ 1375 VCSEAT2L_a232_seatMotorCurrent "VCSEAT2L ECU: a232 seat motor current";
CM_ SG_ 1375 VCSEAT2L_a232_seatMotorPosReal "VCSEAT2L ECU: a232 seat motor pos real";
CM_ SG_ 1375 VCSEAT2L_a232_seatMotorState "VCSEAT2L ECU: a232 seat motor state";
CM_ SG_ 1375 VCSEAT2L_a232_seatSwitchBack "VCSEAT2L ECU: a232 seat switch back; raw 0 = signal not available (SNA)";
CM_ SG_ 1375 VCSEAT2L_a232_seatSwitchForward "VCSEAT2L ECU: a232 seat switch forward; raw 0 = signal not available (SNA)";
CM_ SG_ 1375 VCSEAT2L_a233_seatMotorCurrent "VCSEAT2L ECU: a233 seat motor current";
CM_ SG_ 1375 VCSEAT2L_a233_seatMotorPosReal "VCSEAT2L ECU: a233 seat motor pos real";
CM_ SG_ 1375 VCSEAT2L_a233_seatMotorState "VCSEAT2L ECU: a233 seat motor state";
CM_ SG_ 1375 VCSEAT2L_a233_seatSwitchBack "VCSEAT2L ECU: a233 seat switch back; raw 0 = signal not available (SNA)";
CM_ SG_ 1375 VCSEAT2L_a233_seatSwitchForward "VCSEAT2L ECU: a233 seat switch forward; raw 0 = signal not available (SNA)";
CM_ SG_ 1375 VCSEAT2L_a239_seatHeatCurrent "VCSEAT2L ECU: a239 seat heat current";
CM_ SG_ 1375 VCSEAT2L_a239_seatHeatTmp "VCSEAT2L ECU: a239 seat heat tmp";
CM_ SG_ 1375 VCSEAT2L_a239_seatHeatTmpTarget "VCSEAT2L ECU: a239 seat heat tmp target";
CM_ SG_ 1375 VCSEAT2L_a240_seatHeatCurrent "VCSEAT2L ECU: a240 seat heat current";
CM_ SG_ 1375 VCSEAT2L_a240_seatHeatTmp "VCSEAT2L ECU: a240 seat heat tmp";
CM_ SG_ 1375 VCSEAT2L_a242_snsShortCircuit "VCSEAT2L ECU: a242 sns short circuit";
CM_ SG_ 1375 VCSEAT2L_a242_snsDisconnect "VCSEAT2L ECU: a242 sns disconnect";
CM_ SG_ 1375 VCSEAT2L_a242_snsRateChangeUp "VCSEAT2L ECU: a242 sns rate change up";
CM_ SG_ 1375 VCSEAT2L_a242_snsRateChangeDown "VCSEAT2L ECU: a242 sns rate change down";
CM_ SG_ 1375 VCSEAT2L_a251_seatMotorCurrent "VCSEAT2L ECU: a251 seat motor current";
CM_ SG_ 1375 VCSEAT2L_a251_seatMotorPosReal "VCSEAT2L ECU: a251 seat motor pos real";
CM_ SG_ 1375 VCSEAT2L_a251_seatMotorState "VCSEAT2L ECU: a251 seat motor state";
CM_ SG_ 1375 VCSEAT2L_a251_seatSwitchBack "VCSEAT2L ECU: a251 seat switch back; raw 0 = signal not available (SNA)";
CM_ SG_ 1375 VCSEAT2L_a251_seatSwitchForward "VCSEAT2L ECU: a251 seat switch forward; raw 0 = signal not available (SNA)";
CM_ SG_ 1375 VCSEAT2L_a252_seatMotorCurrent "VCSEAT2L ECU: a252 seat motor current";
CM_ SG_ 1375 VCSEAT2L_a252_seatMotorPosReal "VCSEAT2L ECU: a252 seat motor pos real";
CM_ SG_ 1375 VCSEAT2L_a252_seatMotorState "VCSEAT2L ECU: a252 seat motor state";
CM_ SG_ 1375 VCSEAT2L_a252_seatSwitchBack "VCSEAT2L ECU: a252 seat switch back; raw 0 = signal not available (SNA)";
CM_ SG_ 1375 VCSEAT2L_a252_seatSwitchForward "VCSEAT2L ECU: a252 seat switch forward; raw 0 = signal not available (SNA)";
CM_ SG_ 1375 VCSEAT2L_a260_seatStatePrev "VCSEAT2L ECU: a260 seat state prev";
CM_ SG_ 1375 VCSEAT2L_a260_obstacleDetectReas "VCSEAT2L ECU: a260 obstacle detect reason";
CM_ SG_ 1375 VCSEAT2L_a260_obstacleDetectPosi "VCSEAT2L ECU: a260 obstacle detect position";
CM_ SG_ 1375 VCSEAT2L_a260_accelLookbackTripD "VCSEAT2L ECU: a260 accel lookback trip depth";
CM_ SG_ 1375 VCSEAT2L_a260_seatMotorCurrent "VCSEAT2L ECU: a260 seat motor current";
CM_ SG_ 1375 VCSEAT2L_a261_seatStatePrev "VCSEAT2L ECU: a261 seat state prev";
CM_ SG_ 1375 VCSEAT2L_a261_obstacleDetectReas "VCSEAT2L ECU: a261 obstacle detect reason";
CM_ SG_ 1375 VCSEAT2L_a261_obstacleDetectPosi "VCSEAT2L ECU: a261 obstacle detect position";
CM_ SG_ 1375 VCSEAT2L_a261_accelLookbackTripD "VCSEAT2L ECU: a261 accel lookback trip depth";
CM_ SG_ 1375 VCSEAT2L_a261_seatMotorCurrent "VCSEAT2L ECU: a261 seat motor current";
CM_ SG_ 1375 VCSEAT2L_a263_seatMotorCurrent "VCSEAT2L ECU: a263 seat motor current";
CM_ SG_ 1375 VCSEAT2L_a263_seatMotorDCurrent "VCSEAT2L ECU: a263 seat motor d current";
CM_ SG_ 1375 VCSEAT2L_a263_seatMotorPosReal "VCSEAT2L ECU: a263 seat motor pos real";
CM_ SG_ 1375 VCSEAT2L_a263_seatMotorState "VCSEAT2L ECU: a263 seat motor state";
CM_ SG_ 1375 VCSEAT2L_a264_seatMotorCurrent "VCSEAT2L ECU: a264 seat motor current";
CM_ SG_ 1375 VCSEAT2L_a264_seatMotorDCurrent "VCSEAT2L ECU: a264 seat motor d current";
CM_ SG_ 1375 VCSEAT2L_a264_seatMotorPosReal "VCSEAT2L ECU: a264 seat motor pos real";
CM_ SG_ 1375 VCSEAT2L_a264_seatMotorState "VCSEAT2L ECU: a264 seat motor state";
CM_ SG_ 1375 VCSEAT2L_a267_seatMotorCurrent "VCSEAT2L ECU: a267 seat motor current";
CM_ SG_ 1375 VCSEAT2L_a267_seatMotorDCurrent "VCSEAT2L ECU: a267 seat motor d current";
CM_ SG_ 1375 VCSEAT2L_a267_seatMotorPosReal "VCSEAT2L ECU: a267 seat motor pos real";
CM_ SG_ 1375 VCSEAT2L_a267_seatMotorState "VCSEAT2L ECU: a267 seat motor state";
CM_ SG_ 1375 VCSEAT2L_a268_seatMotorCurrent "VCSEAT2L ECU: a268 seat motor current";
CM_ SG_ 1375 VCSEAT2L_a268_seatMotorDCurrent "VCSEAT2L ECU: a268 seat motor d current";
CM_ SG_ 1375 VCSEAT2L_a268_seatMotorPosReal "VCSEAT2L ECU: a268 seat motor pos real";
CM_ SG_ 1375 VCSEAT2L_a268_seatMotorState "VCSEAT2L ECU: a268 seat motor state";
CM_ SG_ 1375 VCSEAT2L_a270_isRearwardEndstopU "VCSEAT2L ECU: a270 is rearward endstop uncalibrated";
CM_ SG_ 1375 VCSEAT2L_a270_isAbsPosSensorUnca "VCSEAT2L ECU: a270 is abs pos sensor uncalibrated";
CM_ SG_ 1375 VCSEAT2L_a270_seatState "VCSEAT2L ECU: a270 seat state; raw 15 = signal not available (SNA)";
CM_ SG_ 1375 VCSEAT2L_a270_motorType "VCSEAT2L ECU: a270 motor type";
CM_ SG_ 1375 VCSEAT2L_a270_absPosSensState "VCSEAT2L ECU: a270 abs pos sens state";
CM_ SG_ 1375 VCSEAT2L_a273_calibrated "VCSEAT2L ECU: a273 calibrated";
CM_ SG_ 1375 VCSEAT2L_a273_angle "VCSEAT2L ECU: a273 angle";
CM_ SG_ 1375 VCSEAT2L_a273_seatStatePrev "VCSEAT2L ECU: a273 seat state prev; raw 15 = signal not available (SNA)";
CM_ SG_ 1375 VCSEAT2L_a273_obstacleDetectReas "VCSEAT2L ECU: a273 obstacle detect reason";
CM_ SG_ 1375 VCSEAT2L_a273_accelLookbackTripD "VCSEAT2L ECU: a273 accel lookback trip depth";
CM_ SG_ 1375 VCSEAT2L_a273_duty "VCSEAT2L ECU: a273 duty";
CM_ SG_ 1375 VCSEAT2L_a273_currentAbsFilt "VCSEAT2L ECU: a273 current abs filt";
CM_ SG_ 1375 VCSEAT2L_a273_motorType "VCSEAT2L ECU: a273 motor type";
CM_ SG_ 1375 VCSEAT2L_a273_absolutePosSensorF "VCSEAT2L ECU: a273 absolute pos sensor forward";
CM_ SG_ 1375 VCSEAT2L_a273_cabinTemp "VCSEAT2L ECU: a273 cabin temp";
CM_ SG_ 1375 VCSEAT2L_a277_isRearwardEndstopU "VCSEAT2L ECU: a277 is rearward endstop uncalibrated";
CM_ SG_ 1375 VCSEAT2L_a277_isAbsPosSensorUnca "VCSEAT2L ECU: a277 is abs pos sensor uncalibrated";
CM_ SG_ 1375 VCSEAT2L_a278_seatState "VCSEAT2L ECU: a278 seat state; raw 15 = signal not available (SNA)";
CM_ SG_ 1375 VCSEAT2L_a290_isNetworkSwitch "VCSEAT2L ECU: a290 is network switch";
CM_ SG_ 1375 VCSEAT2L_a290_occupancySensorV "VCSEAT2L ECU: a290 occupancy sensor v";
CM_ SG_ 1375 VCSEAT2L_a290_railVoltage "VCSEAT2L ECU: a290 rail voltage";
CM_ SG_ 1375 VCSEAT2L_a291_buckleSensorVoltag "VCSEAT2L ECU: a291 buckle sensor voltage";
CM_ SG_ 1375 VCSEAT2L_a291_railVoltage "VCSEAT2L ECU: a291 rail voltage";
CM_ SG_ 1375 VCSEAT2L_a426_seatMotorCalibrate "VCSEAT2L ECU: a426 seat motor calibrated";
CM_ SG_ 1375 VCSEAT2L_a426_seatMotorCurrent "VCSEAT2L ECU: a426 seat motor current";
CM_ SG_ 1375 VCSEAT2L_a426_seatMotorPosReal "VCSEAT2L ECU: a426 seat motor pos real";
CM_ SG_ 1375 VCSEAT2L_a426_seatMotorState "VCSEAT2L ECU: a426 seat motor state";
CM_ SG_ 1375 VCSEAT2L_a426_seatSwitchBack "VCSEAT2L ECU: a426 seat switch back; raw 0 = signal not available (SNA)";
CM_ SG_ 1375 VCSEAT2L_a426_seatSwitchForward "VCSEAT2L ECU: a426 seat switch forward; raw 0 = signal not available (SNA)";
CM_ SG_ 1375 VCSEAT2L_a426_cabinTmp "VCSEAT2L ECU: a426 cabin tmp";
CM_ SG_ 1375 VCSEAT2L_a427_seatMotorCalibrate "VCSEAT2L ECU: a427 seat motor calibrated";
CM_ SG_ 1375 VCSEAT2L_a427_seatMotorCurrent "VCSEAT2L ECU: a427 seat motor current";
CM_ SG_ 1375 VCSEAT2L_a427_seatMotorPosReal "VCSEAT2L ECU: a427 seat motor pos real";
CM_ SG_ 1375 VCSEAT2L_a427_seatMotorState "VCSEAT2L ECU: a427 seat motor state";
CM_ SG_ 1375 VCSEAT2L_a427_seatSwitchBack "VCSEAT2L ECU: a427 seat switch back; raw 0 = signal not available (SNA)";
CM_ SG_ 1375 VCSEAT2L_a427_seatSwitchForward "VCSEAT2L ECU: a427 seat switch forward; raw 0 = signal not available (SNA)";
CM_ SG_ 1375 VCSEAT2L_a427_cabinTmp "VCSEAT2L ECU: a427 cabin tmp";
CM_ SG_ 1375 VCSEAT2L_a428_seatMotorCalibrate "VCSEAT2L ECU: a428 seat motor calibrated";
CM_ SG_ 1375 VCSEAT2L_a428_seatMotorCurrent "VCSEAT2L ECU: a428 seat motor current";
CM_ SG_ 1375 VCSEAT2L_a428_seatMotorPosReal "VCSEAT2L ECU: a428 seat motor pos real";
CM_ SG_ 1375 VCSEAT2L_a428_seatMotorState "VCSEAT2L ECU: a428 seat motor state";
CM_ SG_ 1375 VCSEAT2L_a428_seatSwitchBack "VCSEAT2L ECU: a428 seat switch back; raw 0 = signal not available (SNA)";
CM_ SG_ 1375 VCSEAT2L_a428_seatSwitchForward "VCSEAT2L ECU: a428 seat switch forward; raw 0 = signal not available (SNA)";
CM_ SG_ 1375 VCSEAT2L_a428_cabinTmp "VCSEAT2L ECU: a428 cabin tmp";
CM_ SG_ 1375 VCSEAT2L_a429_seatMotorCalibrate "VCSEAT2L ECU: a429 seat motor calibrated";
CM_ SG_ 1375 VCSEAT2L_a429_seatMotorCurrent "VCSEAT2L ECU: a429 seat motor current";
CM_ SG_ 1375 VCSEAT2L_a429_seatMotorPosReal "VCSEAT2L ECU: a429 seat motor pos real";
CM_ SG_ 1375 VCSEAT2L_a429_seatMotorState "VCSEAT2L ECU: a429 seat motor state";
CM_ SG_ 1375 VCSEAT2L_a429_seatSwitchBack "VCSEAT2L ECU: a429 seat switch back; raw 0 = signal not available (SNA)";
CM_ SG_ 1375 VCSEAT2L_a429_seatSwitchForward "VCSEAT2L ECU: a429 seat switch forward; raw 0 = signal not available (SNA)";
CM_ SG_ 1375 VCSEAT2L_a429_cabinTmp "VCSEAT2L ECU: a429 cabin tmp";
CM_ SG_ 1375 VCSEAT2L_a444_retriesAvailable "VCSEAT2L ECU: a444 retries available";
CM_ SG_ 1375 VCSEAT2L_a444_channel "VCSEAT2L ECU: a444 channel";
CM_ SG_ 1375 VCSEAT2L_a444_watchdog "VCSEAT2L ECU: a444 watchdog";
CM_ SG_ 1375 VCSEAT2L_a444_gateDriver "VCSEAT2L ECU: a444 gate driver";
CM_ SG_ 1375 VCSEAT2L_a444_overcurrent "VCSEAT2L ECU: a444 overcurrent";
CM_ SG_ 1375 VCSEAT2L_a444_supplyUndervoltage "VCSEAT2L ECU: a444 supply undervoltage";
CM_ SG_ 1375 VCSEAT2L_a444_cpUndervoltage "VCSEAT2L ECU: a444 cp undervoltage";
CM_ SG_ 1375 VCSEAT2L_a444_overTempShutdown "VCSEAT2L ECU: a444 over temp shutdown";
CM_ SG_ 1375 VCSEAT2L_a444_overTempWarning "VCSEAT2L ECU: a444 over temp warning";
CM_ SG_ 1375 VCSEAT2L_a444_highSide2GateDrive "VCSEAT2L ECU: a444 high side2 gate driver";
CM_ SG_ 1375 VCSEAT2L_a444_lowSide2GateDriver "VCSEAT2L ECU: a444 low side2 gate driver";
CM_ SG_ 1375 VCSEAT2L_a444_highSide1GateDrive "VCSEAT2L ECU: a444 high side1 gate driver";
CM_ SG_ 1375 VCSEAT2L_a444_lowSide1GateDriver "VCSEAT2L ECU: a444 low side1 gate driver";
CM_ SG_ 1375 VCSEAT2L_a444_highSide2OverCuren "VCSEAT2L ECU: a444 high side2 over curent";
CM_ SG_ 1375 VCSEAT2L_a444_lowSide2OverCurent "VCSEAT2L ECU: a444 low side2 over curent";
CM_ SG_ 1375 VCSEAT2L_a444_highSide1OverCuren "VCSEAT2L ECU: a444 high side1 over curent";
CM_ SG_ 1375 VCSEAT2L_a444_lowSide1OverCurent "VCSEAT2L ECU: a444 low side1 over curent";
CM_ SG_ 1375 VCSEAT2L_a444_spiInit "VCSEAT2L ECU: a444 spi init";
CM_ SG_ 1375 VCSEAT2L_a444_spiPeriodicCheck "VCSEAT2L ECU: a444 spi periodic check";
CM_ SG_ 1375 VCSEAT2L_a444_spiFault "VCSEAT2L ECU: a444 spi fault";
CM_ SG_ 1375 VCSEAT2L_a444_voltageMonitor "VCSEAT2L ECU: a444 voltage monitor";
CM_ SG_ 1375 VCSEAT2L_a444_enableLow "VCSEAT2L ECU: a444 enable low";
CM_ SG_ 1375 VCSEAT2L_a571_seatHeatCurrent "VCSEAT2L ECU: a571 seat heat current";
CM_ SG_ 1375 VCSEAT2L_a571_seatHeatTmp "VCSEAT2L ECU: a571 seat heat tmp";
CM_ BO_ 892 "VCSEAT2L ECU message: alert matrix; frame length from the layout, not yet observed on a vehicle bus";
CM_ SG_ 892 VCSEAT2L_matrixIndex "VCSEAT2L ECU: matrix index";
CM_ SG_ 892 VCSEAT2L_a001_WatchdogReset "VCSEAT2L ECU: a001 watchdog reset";
CM_ SG_ 892 VCSEAT2L_a002_PowerLossReset "VCSEAT2L ECU: a002 power loss reset";
CM_ SG_ 892 VCSEAT2L_a003_SWAssertion "VCSEAT2L ECU: a003 SW assertion";
CM_ SG_ 892 VCSEAT2L_a005_CANTXError "VCSEAT2L ECU: a005 CANTX error";
CM_ SG_ 892 VCSEAT2L_a006_CANTX_cyclicError "VCSEAT2L ECU: a006 CANTX cyclic error";
CM_ SG_ 892 VCSEAT2L_a010_ExtSupplyVoltError "VCSEAT2L ECU: a010 ext supply volt error";
CM_ SG_ 892 VCSEAT2L_a012_CPUReset "VCSEAT2L ECU: a012 CPU reset";
CM_ SG_ 892 VCSEAT2L_a013_AlertManagerFault "VCSEAT2L ECU: a013 alert manager fault";
CM_ SG_ 892 VCSEAT2L_a015_NVMMError "VCSEAT2L ECU: a015 NVMM error";
CM_ SG_ 892 VCSEAT2L_a016_NVMMRecordError "VCSEAT2L ECU: a016 NVMM record error";
CM_ SG_ 892 VCSEAT2L_a021_TaskSchedulerError "VCSEAT2L ECU: a021 task scheduler error";
CM_ SG_ 892 VCSEAT2L_a022_TaskInitError "VCSEAT2L ECU: a022 task init error";
CM_ SG_ 892 VCSEAT2L_a029_CoreDump "VCSEAT2L ECU: a029 core dump";
CM_ SG_ 892 VCSEAT2L_a030_ECULogUploadReques "VCSEAT2L ECU: a030 ECU log upload request";
CM_ SG_ 892 VCSEAT2L_a031_UDSActive "VCSEAT2L ECU: a031 UDS active";
CM_ SG_ 892 VCSEAT2L_a041_HighCPULoad "VCSEAT2L ECU: a041 high CPU load";
CM_ SG_ 892 VCSEAT2L_a042_HighStackUsage "VCSEAT2L ECU: a042 high stack usage";
CM_ SG_ 892 VCSEAT2L_a043_Task1msError "VCSEAT2L ECU: a043 task1ms error";
CM_ SG_ 892 VCSEAT2L_a044_Task10msError "VCSEAT2L ECU: a044 task10ms error";
CM_ SG_ 892 VCSEAT2L_a045_Task100msError "VCSEAT2L ECU: a045 task100ms error";
CM_ SG_ 892 VCSEAT2L_a046_Task1000msError "VCSEAT2L ECU: a046 task1000ms error";
CM_ SG_ 892 VCSEAT2L_a057_HVP_MIA "VCSEAT2L ECU: a057 HVP MIA";
CM_ SG_ 892 VCSEAT2L_a058_inputRHighSyncDebu "VCSEAT2L ECU: a058 input r high sync debug";
CM_ SG_ 892 VCSEAT2L_a059_inputResistanceHig "VCSEAT2L ECU: a059 input resistance high";
CM_ SG_ 892 VCSEAT2L_a060_engineeringBuild "VCSEAT2L ECU: a060 engineering build";
CM_ SG_ 892 VCSEAT2L_a061_XCPConnected "VCSEAT2L ECU: a061 XCP connected";
CM_ SG_ 892 VCSEAT2L_a062_XCPWasConnected "VCSEAT2L ECU: a062 XCP was connected";
CM_ SG_ 892 VCSEAT2L_a063_SwitchFault "VCSEAT2L ECU: a063 switch fault";
CM_ SG_ 892 VCSEAT2L_a064_busSleepReqTimeout "VCSEAT2L ECU: a064 bus sleep req timeout";
CM_ SG_ 892 VCSEAT2L_a082_VCRIGHT_IPC_MIA "VCSEAT2L ECU: a082 VCRIGHT IPC MIA";
CM_ SG_ 892 VCSEAT2L_a083_VCLEFT_IPC_MIA "VCSEAT2L ECU: a083 VCLEFT IPC MIA";
CM_ SG_ 892 VCSEAT2L_a084_TPMS_MIA "VCSEAT2L ECU: a084 TPMS MIA";
CM_ SG_ 892 VCSEAT2L_a085_CCCM_MIA "VCSEAT2L ECU: a085 CCCM MIA";
CM_ SG_ 892 VCSEAT2L_a086_VCBATT_MIA "VCSEAT2L ECU: a086 VCBATT MIA";
CM_ SG_ 892 VCSEAT2L_a087_DIREL_MIA "VCSEAT2L ECU: a087 DIREL MIA";
CM_ SG_ 892 VCSEAT2L_a088_DIRER_MIA "VCSEAT2L ECU: a088 DIRER MIA";
CM_ SG_ 892 VCSEAT2L_a089_IBST_MIA "VCSEAT2L ECU: a089 IBST MIA";
CM_ SG_ 892 VCSEAT2L_a090_APS_MIA "VCSEAT2L ECU: a090 APS MIA";
CM_ SG_ 892 VCSEAT2L_a091_CMPD_MIA "VCSEAT2L ECU: a091 CMPD MIA";
CM_ SG_ 892 VCSEAT2L_a092_VCSEATD_MIA "VCSEAT2L ECU: a092 VCSEATD MIA";
CM_ SG_ 892 VCSEAT2L_a093_VCSEATP_MIA "VCSEAT2L ECU: a093 VCSEATP MIA";
CM_ SG_ 892 VCSEAT2L_a094_EPAS3P_MIA "VCSEAT2L ECU: a094 EPAS3 p MIA";
CM_ SG_ 892 VCSEAT2L_a095_CHG_MIA "VCSEAT2L ECU: a095 CHG MIA";
CM_ SG_ 892 VCSEAT2L_a096_OCS1P_MIA "VCSEAT2L ECU: a096 OCS1 p MIA";
CM_ SG_ 892 VCSEAT2L_a097_CMP_MIA "VCSEAT2L ECU: a097 CMP MIA";
CM_ SG_ 892 VCSEAT2L_a098_DIR_MIA "VCSEAT2L ECU: a098 DIR MIA";
CM_ SG_ 892 VCSEAT2L_a099_PARK_MIA "VCSEAT2L ECU: a099 PARK MIA";
CM_ SG_ 892 VCSEAT2L_a100_CANbus_MIA "VCSEAT2L ECU: a100 CA nbus MIA";
CM_ SG_ 892 VCSEAT2L_a101_PM_MIA "VCSEAT2L ECU: a101 PM MIA";
CM_ SG_ 892 VCSEAT2L_a102_PTC_MIA "VCSEAT2L ECU: a102 PTC MIA";
CM_ SG_ 892 VCSEAT2L_a103_CP_MIA "VCSEAT2L ECU: a103 CP MIA";
CM_ SG_ 892 VCSEAT2L_a104_DAS_MIA "VCSEAT2L ECU: a104 DAS MIA";
CM_ SG_ 892 VCSEAT2L_a105_TAS_MIA "VCSEAT2L ECU: a105 TAS MIA";
CM_ SG_ 892 VCSEAT2L_a106_PCS_MIA "VCSEAT2L ECU: a106 PCS MIA";
CM_ SG_ 892 VCSEAT2L_a107_BMS_MIA "VCSEAT2L ECU: a107 BMS MIA";
CM_ SG_ 892 VCSEAT2L_a108_DIF_MIA "VCSEAT2L ECU: a108 DIF MIA";
CM_ SG_ 892 VCSEAT2L_a109_RCM_MIA "VCSEAT2L ECU: a109 RCM MIA";
CM_ SG_ 892 VCSEAT2L_a110_GTW_MIA "VCSEAT2L ECU: a110 GTW MIA";
CM_ SG_ 892 VCSEAT2L_a111_EPBR_MIA "VCSEAT2L ECU: a111 EPBR MIA";
CM_ SG_ 892 VCSEAT2L_a112_EPBL_MIA "VCSEAT2L ECU: a112 EPBL MIA";
CM_ SG_ 892 VCSEAT2L_a113_UI_MIA "VCSEAT2L ECU: a113 UI MIA";
CM_ SG_ 892 VCSEAT2L_a114_ESP_MIA "VCSEAT2L ECU: a114 ESP MIA";
CM_ SG_ 892 VCSEAT2L_a115_VCSEC_MIA "VCSEAT2L ECU: a115 VCSEC MIA";
CM_ SG_ 892 VCSEAT2L_a116_VCRIGHT_MIA "VCSEAT2L ECU: a116 VCRIGHT MIA";
CM_ SG_ 892 VCSEAT2L_a117_VCLEFT_MIA "VCSEAT2L ECU: a117 VCLEFT MIA";
CM_ SG_ 892 VCSEAT2L_a118_VCFRONT_MIA "VCSEAT2L ECU: a118 VCFRONT MIA";
CM_ SG_ 892 VCSEAT2L_a119_SCCM_MIA "VCSEAT2L ECU: a119 SCCM MIA";
CM_ SG_ 892 VCSEAT2L_a120_DI_DRIVE_MIA "VCSEAT2L ECU: a120 DI DRIVE MIA";
CM_ SG_ 892 VCSEAT2L_a190_seatChoreographyIs "VCSEAT2L ECU: a190 seat choreography is blocked by front seat";
CM_ SG_ 892 VCSEAT2L_a191_seatChoreographyIs "VCSEAT2L ECU: a191 seat choreography is blocked by second seat";
CM_ SG_ 892 VCSEAT2L_a200_motorPhantomEncode "VCSEAT2L ECU: a200 motor phantom encoder";
CM_ SG_ 892 VCSEAT2L_a201_motorDutyEncDisabl "VCSEAT2L ECU: a201 motor duty enc disabl";
CM_ SG_ 892 VCSEAT2L_a210_armrestEncStall "VCSEAT2L ECU: a210 armrest enc stall";
CM_ SG_ 892 VCSEAT2L_a211_armrestCurrUnder "VCSEAT2L ECU: a211 armrest curr under";
CM_ SG_ 892 VCSEAT2L_a212_armrestUncal "VCSEAT2L ECU: a212 armrest uncal";
CM_ SG_ 892 VCSEAT2L_a213_armrestEncOver "VCSEAT2L ECU: a213 armrest enc over";
CM_ SG_ 892 VCSEAT2L_a214_armrestStallDebug "VCSEAT2L ECU: a214 armrest stall debug";
CM_ SG_ 892 VCSEAT2L_a215_armrestHCEncStlDbg "VCSEAT2L ECU: a215 armrest HC enc stl dbg";
CM_ SG_ 892 VCSEAT2L_a218_motorDriverFault "VCSEAT2L ECU: a218 motor driver fault";
CM_ SG_ 892 VCSEAT2L_a219_motorCurrentDropou "VCSEAT2L ECU: a219 motor current dropout";
CM_ SG_ 892 VCSEAT2L_a224_seatEncStallTrack "VCSEAT2L ECU: a224 seat enc stall track";
CM_ SG_ 892 VCSEAT2L_a225_seatEncStallBack "VCSEAT2L ECU: a225 seat enc stall back";
CM_ SG_ 892 VCSEAT2L_a228_seatEncOverTrack "VCSEAT2L ECU: a228 seat enc over track";
CM_ SG_ 892 VCSEAT2L_a229_seatEncOverBack "VCSEAT2L ECU: a229 seat enc over back";
CM_ SG_ 892 VCSEAT2L_a232_seatCurrUnderTrack "VCSEAT2L ECU: a232 seat curr under track";
CM_ SG_ 892 VCSEAT2L_a233_seatCurrUnderBack "VCSEAT2L ECU: a233 seat curr under back";
CM_ SG_ 892 VCSEAT2L_a234_seatTrackStatsFrom "VCSEAT2L ECU: a234 seat track stats from last state dbg";
CM_ SG_ 892 VCSEAT2L_a235_seatTrackStatsFrom "VCSEAT2L ECU: a235 seat track stats from last state dbg2";
CM_ SG_ 892 VCSEAT2L_a236_seatArmrestStatsFr "VCSEAT2L ECU: a236 seat armrest stats from last state dbg";
CM_ SG_ 892 VCSEAT2L_a237_seatArmrestStatsFr "VCSEAT2L ECU: a237 seat armrest stats from last state dbg2";
CM_ SG_ 892 VCSEAT2L_a238_seatArmrestInhibit "VCSEAT2L ECU: a238 seat armrest inhibited by backrest";
CM_ SG_ 892 VCSEAT2L_a239_seatHeatIRow2 "VCSEAT2L ECU: a239 seat heat i row2";
CM_ SG_ 892 VCSEAT2L_a240_seatHeatShortRow2 "VCSEAT2L ECU: a240 seat heat short row2";
CM_ SG_ 892 VCSEAT2L_a241_seatArmrestHistory "VCSEAT2L ECU: a241 seat armrest history score";
CM_ SG_ 892 VCSEAT2L_a242_seatHeatTmpRow2 "VCSEAT2L ECU: a242 seat heat tmp row2";
CM_ SG_ 892 VCSEAT2L_a243_seatArmrestHistory "VCSEAT2L ECU: a243 seat armrest history score dbg";
CM_ SG_ 892 VCSEAT2L_a244_seatArmrestSpeedTa "VCSEAT2L ECU: a244 seat armrest speed table reference status";
CM_ SG_ 892 VCSEAT2L_a245_seatArmrestEcuLogS "VCSEAT2L ECU: a245 seat armrest ecu log status";
CM_ SG_ 892 VCSEAT2L_a251_seatUncalTrack "VCSEAT2L ECU: a251 seat uncal track";
CM_ SG_ 892 VCSEAT2L_a252_seatUncalBack "VCSEAT2L ECU: a252 seat uncal back";
CM_ SG_ 892 VCSEAT2L_a260_seatTrackObstacleD "VCSEAT2L ECU: a260 seat track obstacle detected";
CM_ SG_ 892 VCSEAT2L_a261_seatArmrestObstacl "VCSEAT2L ECU: a261 seat armrest obstacle detected";
CM_ SG_ 892 VCSEAT2L_a263_seatTrackStallDebu "VCSEAT2L ECU: a263 seat track stall debug";
CM_ SG_ 892 VCSEAT2L_a264_seatBackStallDebug "VCSEAT2L ECU: a264 seat back stall debug";
CM_ SG_ 892 VCSEAT2L_a267_seatTrackHCEncStl "VCSEAT2L ECU: a267 seat track HC enc stl";
CM_ SG_ 892 VCSEAT2L_a268_seatBackHCEncStlDb "VCSEAT2L ECU: a268 seat back HC enc stl dbg";
CM_ SG_ 892 VCSEAT2L_a270_seatUncalibrated "VCSEAT2L ECU: a270 seat uncalibrated";
CM_ SG_ 892 VCSEAT2L_a271_seatPositionNonsen "VCSEAT2L ECU: a271 seat position nonsensical";
CM_ SG_ 892 VCSEAT2L_a272_seatAbsPosOffsetAp "VCSEAT2L ECU: a272 seat abs pos offset applied";
CM_ SG_ 892 VCSEAT2L_a273_seatObstacleDetect "VCSEAT2L ECU: a273 seat obstacle detected";
CM_ SG_ 892 VCSEAT2L_a274_seatTempHigh "VCSEAT2L ECU: a274 seat temp high";
CM_ SG_ 892 VCSEAT2L_a275_seatAbsPosSensorTr "VCSEAT2L ECU: a275 seat abs pos sensor transition dbg";
CM_ SG_ 892 VCSEAT2L_a276_seatStatsFromLastS "VCSEAT2L ECU: a276 seat stats from last state dbg";
CM_ SG_ 892 VCSEAT2L_a277_seatRequestWhileUn "VCSEAT2L ECU: a277 seat request while uncalibrated";
CM_ SG_ 892 VCSEAT2L_a278_seatClashAvoidance "VCSEAT2L ECU: a278 seat clash avoidance blocked";
CM_ SG_ 892 VCSEAT2L_a279_seatOverfolded "VCSEAT2L ECU: a279 seat overfolded";
CM_ SG_ 892 VCSEAT2L_a280_seatStatsFromLastS "VCSEAT2L ECU: a280 seat stats from last state dbg2";
CM_ SG_ 892 VCSEAT2L_a290_occupancyFaultRow2 "VCSEAT2L ECU: a290 occupancy fault row2";
CM_ SG_ 892 VCSEAT2L_a291_buckleFaultedRow2 "VCSEAT2L ECU: a291 buckle faulted row2";
CM_ SG_ 892 VCSEAT2L_a426_seatAbuseMotorWarn "VCSEAT2L ECU: a426 seat abuse motor warn";
CM_ SG_ 892 VCSEAT2L_a427_seatAbuseMotorStop "VCSEAT2L ECU: a427 seat abuse motor stop";
CM_ SG_ 892 VCSEAT2L_a428_seatAbuseBufferWar "VCSEAT2L ECU: a428 seat abuse buffer warn";
CM_ SG_ 892 VCSEAT2L_a429_seatAbuseBufferFul "VCSEAT2L ECU: a429 seat abuse buffer full";
CM_ SG_ 892 VCSEAT2L_a444_drv8703Fault "VCSEAT2L ECU: a444 drv8703 fault";
CM_ SG_ 892 VCSEAT2L_a445_drv8703SpiFaultDBG "VCSEAT2L ECU: a445 drv8703 spi fault DBG";
CM_ SG_ 892 VCSEAT2L_a526_pcbaOverTemperatur "VCSEAT2L ECU: a526 pcba over temperature";
CM_ SG_ 892 VCSEAT2L_a550_ambientTempDelta "VCSEAT2L ECU: a550 ambient temp delta";
CM_ SG_ 892 VCSEAT2L_a571_seatHeatDisabledRe "VCSEAT2L ECU: a571 seat heat disabled rear";
CM_ BO_ 764 "VCSEAT2L ECU message: seat status; frame length from the layout, not yet observed on a vehicle bus";
CM_ SG_ 764 VCSEAT2L_row2SeatStatusIndex "VCSEAT2L ECU: row2 seat status index";
CM_ SG_ 764 VCSEAT2L_seatTrackPosReal "Reports real position of seat track";
CM_ SG_ 764 VCSEAT2L_seatTrackPosOffset "VCSEAT2L ECU: seat track pos offset";
CM_ SG_ 764 VCSEAT2L_seatReclineState "Reports the active state of the 2nd row seat recliner; raw 15 = signal not available (SNA)";
CM_ SG_ 764 VCSEAT2L_seatReclineCalibrated "Reports calibration status of the 2nd row seat recliner";
CM_ SG_ 764 VCSEAT2L_seatReclinePositionStat "Reports the active position state of the 2nd row seat recliner; raw 4 = signal not available (SNA)";
CM_ SG_ 764 VCSEAT2L_seatReclineAbsPosS_0001 "VCSEAT2L ECU: seat recline abs pos switch trans point";
CM_ SG_ 764 VCSEAT2L_seatReclineAbsPosSwitch "Reports the status of 2nd row seat recline absolute position (comfort zone) switch; raw 0 = signal not available (SNA)";
CM_ SG_ 764 VCSEAT2L_seatReclineFoldAllowed "VCSEAT2L ECU: seat recline fold allowed";
CM_ SG_ 764 VCSEAT2L_seatReclineUnfoldAllowe "VCSEAT2L ECU: seat recline unfold allowed";
CM_ SG_ 764 VCSEAT2L_seatReclineAdjustmentAl "VCSEAT2L ECU: seat recline adjustment allowed";
CM_ SG_ 764 VCSEAT2L_seat1RClashAvoidanceBlo "VCSEAT2L ECU: seat1 r clash avoidance blocked reason";
CM_ SG_ 764 VCSEAT2L_seat1RClashAvoidanceSta "VCSEAT2L ECU: seat1 r clash avoidance state";
CM_ SG_ 764 VCSEAT2L_seatReclineChoreoBlocke "VCSEAT2L ECU: seat recline choreo blocked by occupancy";
CM_ SG_ 764 VCSEAT2L_seatReclineNextToggleDi "VCSEAT2L ECU: seat recline next toggle direction; raw 2 = signal not available (SNA)";
CM_ BO_ 1986 "VCSEAT2L ECU message: seat status2; frame length from the layout, not yet observed on a vehicle bus";
CM_ SG_ 1986 VCSEAT2L_seatStatus2Index "VCSEAT2L ECU: seat status2 index";
CM_ SG_ 1986 VCSEAT2L_choreography2RState "VCSEAT2L ECU: choreography2 r state";
CM_ SG_ 1986 VCSEAT2L_choreography3RState "VCSEAT2L ECU: choreography3 r state";
CM_ SG_ 1986 VCSEAT2L_choreography1RIsAllowed "VCSEAT2L ECU: choreography1 r is allowed to move";
CM_ SG_ 1986 VCSEAT2L_choreography2RIsAllowed "VCSEAT2L ECU: choreography2 r is allowed to move";
CM_ SG_ 1986 VCSEAT2L_choreography1RTrackVelo "VCSEAT2L ECU: choreography1 r track velocity type";
CM_ SG_ 1986 VCSEAT2L_choreography1RBackrestV "VCSEAT2L ECU: choreography1 r backrest velocity type";
CM_ SG_ 1986 VCSEAT2L_choreography2RTrackVelo "VCSEAT2L ECU: choreography2 r track velocity type";
CM_ SG_ 1986 VCSEAT2L_choreography2RBackrestV "VCSEAT2L ECU: choreography2 r backrest velocity type";
CM_ SG_ 1986 VCSEAT2L_choreography3RBackrestV "VCSEAT2L ECU: choreography3 r backrest velocity type";
CM_ SG_ 1986 VCSEAT2L_choreographyState "VCSEAT2L ECU: choreography state";
CM_ SG_ 1986 VCSEAT2L_choreographyCollisionPa "VCSEAT2L ECU: choreography collision pair";
CM_ SG_ 1986 VCSEAT2L_2rMovingForChoreography "VCSEAT2L ECU: 2r moving for choreography";
BA_DEF_ BO_ "GenMsgCycleTime" INT 0 3600000;
BA_DEF_ BO_ "GenMsgSendType" ENUM "Cyclic","NotUsed","NotUsed","NotUsed","NotUsed","NotUsed","NotUsed","IfActive","NoMsgSendType","NotUsed";
BA_DEF_ BO_ "VFrameFormat" ENUM "StandardCAN","ExtendedCAN","reserved","J1939PG","reserved","reserved","reserved","reserved","reserved","reserved","reserved","reserved","reserved","reserved","StandardCAN_FD","ExtendedCAN_FD";
BA_DEF_ BO_ "CANFD_BRS" ENUM "0","1";
BA_DEF_ SG_ "GenSigSNA" STRING;
BA_DEF_ SG_ "SystemSignalLongSymbol" STRING;
BA_DEF_ SG_ "Confidence" ENUM "validated","plausible","layout-only","contradicted";
BA_DEF_DEF_ "GenMsgCycleTime" 0;
BA_DEF_DEF_ "GenMsgSendType" "NoMsgSendType";
BA_DEF_DEF_ "VFrameFormat" "StandardCAN";
BA_DEF_DEF_ "CANFD_BRS" "1";
BA_DEF_DEF_ "GenSigSNA" "";
BA_DEF_DEF_ "SystemSignalLongSymbol" "";
BA_DEF_DEF_ "Confidence" "layout-only";
BA_ "GenMsgCycleTime" BO_ 963 100;
BA_ "GenMsgSendType" BO_ 963 0;
BA_ "GenMsgCycleTime" BO_ 899 100;
BA_ "GenMsgSendType" BO_ 899 0;
BA_ "GenMsgCycleTime" BO_ 1059 100;
BA_ "GenMsgSendType" BO_ 1059 0;
BA_ "GenMsgCycleTime" BO_ 707 100;
BA_ "GenMsgSendType" BO_ 707 0;
BA_ "GenMsgCycleTime" BO_ 892 100;
BA_ "GenMsgSendType" BO_ 892 0;
BA_ "GenMsgCycleTime" BO_ 764 100;
BA_ "GenMsgSendType" BO_ 764 0;
BA_ "GenMsgCycleTime" BO_ 1986 200;
BA_ "GenMsgSendType" BO_ 1986 0;
BA_ "Confidence" SG_ 963 VCRIGHT_switchStatusIndex 1;
BA_ "Confidence" SG_ 963 VCRIGHT_btnWindowUpRF 1;
BA_ "Confidence" SG_ 963 VCRIGHT_btnWindowAutoUpRF 1;
BA_ "Confidence" SG_ 963 VCRIGHT_btnWindowDownRF 1;
BA_ "Confidence" SG_ 963 VCRIGHT_btnWindowAutoDownRF 1;
BA_ "Confidence" SG_ 963 VCRIGHT_btnWindowUpRR 1;
BA_ "Confidence" SG_ 963 VCRIGHT_btnWindowAutoUpRR 1;
BA_ "Confidence" SG_ 963 VCRIGHT_btnWindowDownRR 1;
BA_ "Confidence" SG_ 963 VCRIGHT_btnWindowAutoDownRR 1;
BA_ "Confidence" SG_ 963 VCRIGHT_btnWindowSwPackUpLF 1;
BA_ "Confidence" SG_ 963 VCRIGHT_btnWindowSwPackAutoUpLF 1;
BA_ "Confidence" SG_ 963 VCRIGHT_btnWindowSwPackDownLF 1;
BA_ "Confidence" SG_ 963 VCRIGHT_btnWindowSwPackAutoDwnLF 1;
BA_ "Confidence" SG_ 963 VCRIGHT_btnWindowSwPackUpLR 1;
BA_ "Confidence" SG_ 963 VCRIGHT_btnWindowSwPackAutoUpLR 1;
BA_ "Confidence" SG_ 963 VCRIGHT_btnWindowSwPackDownLR 1;
BA_ "Confidence" SG_ 963 VCRIGHT_btnWindowSwPackAutoDwnLR 1;
BA_ "Confidence" SG_ 963 VCRIGHT_frontOccupancySwitch 1;
BA_ "Confidence" SG_ 963 VCRIGHT_trunkExtReleasePressed 1;
BA_ "Confidence" SG_ 963 VCRIGHT_btnWindowSwPackUpRR 1;
BA_ "Confidence" SG_ 963 VCRIGHT_btnWindowSwPackAutoUpRR 1;
BA_ "Confidence" SG_ 963 VCRIGHT_btnWindowSwPackDownRR 1;
BA_ "Confidence" SG_ 963 VCRIGHT_btnWindowSwPackAutoDwnRR 1;
BA_ "Confidence" SG_ 963 VCRIGHT_frontBuckleSwitch 1;
BA_ "Confidence" SG_ 963 VCRIGHT_rearCenterBuckleSwitch 1;
BA_ "Confidence" SG_ 963 VCRIGHT_rearRightBuckleSwitch 1;
BA_ "Confidence" SG_ 963 VCRIGHT_trunkExtReleasePressedPe 0;
BA_ "SystemSignalLongSymbol" SG_ 963 VCRIGHT_trunkExtReleasePressedPe "VCRIGHT_trunkExtReleasePressedPersist";
BA_ "Confidence" SG_ 963 VCRIGHT_frontSeatTrackBack 0;
BA_ "GenSigSNA" SG_ 963 VCRIGHT_frontSeatTrackBack "0";
BA_ "Confidence" SG_ 963 VCRIGHT_frontSeatTrackForward 0;
BA_ "GenSigSNA" SG_ 963 VCRIGHT_frontSeatTrackForward "0";
BA_ "Confidence" SG_ 963 VCRIGHT_frontSeatTiltDown 0;
BA_ "GenSigSNA" SG_ 963 VCRIGHT_frontSeatTiltDown "0";
BA_ "Confidence" SG_ 963 VCRIGHT_frontSeatTiltUp 0;
BA_ "GenSigSNA" SG_ 963 VCRIGHT_frontSeatTiltUp "0";
BA_ "Confidence" SG_ 963 VCRIGHT_frontSeatLiftDown 0;
BA_ "GenSigSNA" SG_ 963 VCRIGHT_frontSeatLiftDown "0";
BA_ "Confidence" SG_ 963 VCRIGHT_frontSeatLiftUp 0;
BA_ "GenSigSNA" SG_ 963 VCRIGHT_frontSeatLiftUp "0";
BA_ "Confidence" SG_ 963 VCRIGHT_frontSeatBackrestBack 0;
BA_ "GenSigSNA" SG_ 963 VCRIGHT_frontSeatBackrestBack "0";
BA_ "Confidence" SG_ 963 VCRIGHT_frontSeatBackrestForward 0;
BA_ "GenSigSNA" SG_ 963 VCRIGHT_frontSeatBackrestForward "0";
BA_ "Confidence" SG_ 963 VCRIGHT_frontSeatLumbarDown 0;
BA_ "GenSigSNA" SG_ 963 VCRIGHT_frontSeatLumbarDown "0";
BA_ "Confidence" SG_ 963 VCRIGHT_frontSeatLumbarUp 0;
BA_ "GenSigSNA" SG_ 963 VCRIGHT_frontSeatLumbarUp "0";
BA_ "Confidence" SG_ 963 VCRIGHT_frontSeatLumbarIn 0;
BA_ "GenSigSNA" SG_ 963 VCRIGHT_frontSeatLumbarIn "0";
BA_ "Confidence" SG_ 963 VCRIGHT_frontSeatResistiveOccupa 0;
BA_ "GenSigSNA" SG_ 963 VCRIGHT_frontSeatResistiveOccupa "0";
BA_ "SystemSignalLongSymbol" SG_ 963 VCRIGHT_frontSeatResistiveOccupa "VCRIGHT_frontSeatResistiveOccupancy";
BA_ "Confidence" SG_ 963 VCRIGHT_2RowSeatReclineSwitchpac 0;
BA_ "SystemSignalLongSymbol" SG_ 963 VCRIGHT_2RowSeatReclineSwitchpac "VCRIGHT_2RowSeatReclineSwitchpackState";
BA_ "Confidence" SG_ 963 VCRIGHT_hvacHeatingAllowedRight 0;
BA_ "Confidence" SG_ 963 VCRIGHT_frontSeatThighSupportRet 0;
BA_ "GenSigSNA" SG_ 963 VCRIGHT_frontSeatThighSupportRet "0";
BA_ "SystemSignalLongSymbol" SG_ 963 VCRIGHT_frontSeatThighSupportRet "VCRIGHT_frontSeatThighSupportRetractSwitch";
BA_ "Confidence" SG_ 899 VCRIGHT_thsActive 0;
BA_ "Confidence" SG_ 899 VCRIGHT_thsTemperature 0;
BA_ "GenSigSNA" SG_ 899 VCRIGHT_thsTemperature "255";
BA_ "Confidence" SG_ 899 VCRIGHT_thsState 0;
BA_ "Confidence" SG_ 899 VCRIGHT_thsLINCurrentSchedule 0;
BA_ "Confidence" SG_ 899 VCRIGHT_thsDetected 0;
BA_ "Confidence" SG_ 899 VCRIGHT_thsHumidity 0;
BA_ "GenSigSNA" SG_ 899 VCRIGHT_thsHumidity "127";
BA_ "Confidence" SG_ 899 VCRIGHT_estimatedVehicleSituatio 0;
BA_ "SystemSignalLongSymbol" SG_ 899 VCRIGHT_estimatedVehicleSituatio "VCRIGHT_estimatedVehicleSituation";
BA_ "Confidence" SG_ 899 VCRIGHT_thsSolarLoadInfrared 0;
BA_ "GenSigSNA" SG_ 899 VCRIGHT_thsSolarLoadInfrared "1023";
BA_ "Confidence" SG_ 899 VCRIGHT_thsSolarLoadVisible 0;
BA_ "GenSigSNA" SG_ 899 VCRIGHT_thsSolarLoadVisible "1023";
BA_ "Confidence" SG_ 899 VCRIGHT_estimatedThsSolarLoad 0;
BA_ "GenSigSNA" SG_ 899 VCRIGHT_estimatedThsSolarLoad "1023";
BA_ "Confidence" SG_ 899 VCRIGHT_hvacFastLoggingEnabled 0;
BA_ "Confidence" SG_ 1545 VCRIGHT_udsResponseData_H 1;
BA_ "Confidence" SG_ 1545 VCRIGHT_udsResponseData_L 1;
BA_ "Confidence" SG_ 1059 VCRIGHT_nmGoingToSleep 0;
BA_ "Confidence" SG_ 1059 VCRIGHT_nmWakeUpBus 0;
BA_ "Confidence" SG_ 1059 VCRIGHT_nmKeepAwakeReason 0;
BA_ "GenSigSNA" SG_ 1059 VCRIGHT_nmKeepAwakeReason "0";
BA_ "Confidence" SG_ 1059 VCRIGHT_nmWakeUpReason 0;
BA_ "Confidence" SG_ 1059 VCRIGHT_nmDebugWakeUp 0;
BA_ "Confidence" SG_ 1059 VCRIGHT_nmEthKeepAwakeReason 0;
BA_ "GenSigSNA" SG_ 1059 VCRIGHT_nmEthKeepAwakeReason "0";
BA_ "Confidence" SG_ 1059 VCRIGHT_nmChKeepAwakeReason 0;
BA_ "GenSigSNA" SG_ 1059 VCRIGHT_nmChKeepAwakeReason "0";
BA_ "Confidence" SG_ 707 VCRIGHT_windowStatusIndex 1;
BA_ "Confidence" SG_ 707 VCRIGHT_windowStateRF 0;
BA_ "Confidence" SG_ 707 VCRIGHT_windowTrimClearMoveReque 0;
BA_ "SystemSignalLongSymbol" SG_ 707 VCRIGHT_windowTrimClearMoveReque "VCRIGHT_windowTrimClearMoveRequest";
BA_ "Confidence" SG_ 707 VCRIGHT_windowDutyRF 0;
BA_ "Confidence" SG_ 707 VCRIGHT_windowTrimClearActiveReq 0;
BA_ "GenSigSNA" SG_ 707 VCRIGHT_windowTrimClearActiveReq "0";
BA_ "SystemSignalLongSymbol" SG_ 707 VCRIGHT_windowTrimClearActiveReq "VCRIGHT_windowTrimClearActiveRequest";
BA_ "Confidence" SG_ 707 VCRIGHT_windowCurrentRF 0;
BA_ "Confidence" SG_ 707 VCRIGHT_windowPositionRF 0;
BA_ "GenSigSNA" SG_ 707 VCRIGHT_windowPositionRF "1";
BA_ "Confidence" SG_ 707 VCRIGHT_windowCalibratedRF 0;
BA_ "Confidence" SG_ 707 VCRIGHT_windowStateRR 0;
BA_ "Confidence" SG_ 707 VCRIGHT_windowDutyRR 0;
BA_ "Confidence" SG_ 707 VCRIGHT_windowCurrentRR 0;
BA_ "Confidence" SG_ 707 VCRIGHT_windowPositionRR 0;
BA_ "Confidence" SG_ 707 VCRIGHT_windowCalibratedRR 0;
BA_ "Confidence" SG_ 707 VCRIGHT_windowThermalTCRF 0;
BA_ "Confidence" SG_ 707 VCRIGHT_windowThermalModeRF 0;
BA_ "GenSigSNA" SG_ 707 VCRIGHT_windowThermalModeRF "0";
BA_ "Confidence" SG_ 707 VCRIGHT_windowStopReasonRF 0;
BA_ "Confidence" SG_ 707 VCRIGHT_windowStopReqReasonRF 0;
BA_ "Confidence" SG_ 707 VCRIGHT_windowThermalTCRR 0;
BA_ "Confidence" SG_ 707 VCRIGHT_windowThermalModeRR 0;
BA_ "GenSigSNA" SG_ 707 VCRIGHT_windowThermalModeRR "0";
BA_ "Confidence" SG_ 707 VCRIGHT_windowStopReasonRR 0;
BA_ "Confidence" SG_ 707 VCRIGHT_windowStopReqReasonRR 0;
BA_ "Confidence" SG_ 707 VCRIGHT_windowControlStateRF 0;
BA_ "Confidence" SG_ 707 VCRIGHT_windowCtrlUnavailableRF 0;
BA_ "Confidence" SG_ 707 VCRIGHT_windowControlStateRR 0;
BA_ "Confidence" SG_ 707 VCRIGHT_windowCtrlUnavailableRR 0;
BA_ "Confidence" SG_ 707 VCRIGHT_windowPositionStateRF 0;
BA_ "Confidence" SG_ 707 VCRIGHT_windowPositionStateRR 0;
BA_ "Confidence" SG_ 707 VCRIGHT_windowVehGearStateRF 0;
BA_ "GenSigSNA" SG_ 707 VCRIGHT_windowVehGearStateRF "0";
BA_ "Confidence" SG_ 707 VCRIGHT_windowVehGearStateRR 0;
BA_ "GenSigSNA" SG_ 707 VCRIGHT_windowVehGearStateRR "0";
BA_ "Confidence" SG_ 707 VCRIGHT_windowSpeedTableStatusRF 0;
BA_ "GenSigSNA" SG_ 707 VCRIGHT_windowSpeedTableStatusRF "0";
BA_ "Confidence" SG_ 707 VCRIGHT_windowSpeedTableStatusRR 0;
BA_ "GenSigSNA" SG_ 707 VCRIGHT_windowSpeedTableStatusRR "0";
BA_ "Confidence" SG_ 1375 VCSEAT2L_alertID 1;
BA_ "Confidence" SG_ 1375 VCSEAT2L_alertState 1;
BA_ "SystemSignalLongSymbol" SG_ 1375 VCSEAT2L_a015_NVMMFilesystemErro "VCSEAT2L_a015_NVMMFilesystemError";
BA_ "Confidence" SG_ 1375 VCSEAT2L_a059_voltageDrop 1;
BA_ "Confidence" SG_ 1375 VCSEAT2L_a059_resistanceEstimate 1;
BA_ "Confidence" SG_ 1375 VCSEAT2L_a059_current 1;
BA_ "Confidence" SG_ 1375 VCSEAT2L_a063_ADCVoltage 1;
BA_ "SystemSignalLongSymbol" SG_ 1375 VCSEAT2L_a082_RIPC_epbPrivateSta "VCSEAT2L_a082_RIPC_epbPrivateState";
BA_ "SystemSignalLongSymbol" SG_ 1375 VCSEAT2L_a083_LIPC_epbPrivateSta "VCSEAT2L_a083_LIPC_epbPrivateState";
BA_ "SystemSignalLongSymbol" SG_ 1375 VCSEAT2L_a086_VEH_LVBMS_statusHi "VCSEAT2L_a086_VEH_LVBMS_statusHigh";
BA_ "SystemSignalLongSymbol" SG_ 1375 VCSEAT2L_a086_VEH_LVBMS_statusLo "VCSEAT2L_a086_VEH_LVBMS_statusLow";
BA_ "SystemSignalLongSymbol" SG_ 1375 VCSEAT2L_a086_VEH_12VBatteryStat "VCSEAT2L_a086_VEH_12VBatteryStatus";
BA_ "SystemSignalLongSymbol" SG_ 1375 VCSEAT2L_a087_PARTY_thermalContr "VCSEAT2L_a087_PARTY_thermalControl";
BA_ "SystemSignalLongSymbol" SG_ 1375 VCSEAT2L_a088_PARTY_thermalContr "VCSEAT2L_a088_PARTY_thermalControl";
BA_ "SystemSignalLongSymbol" SG_ 1375 VCSEAT2L_a091_VEH_faultsAndExtra "VCSEAT2L_a091_VEH_faultsAndExtras";
BA_ "SystemSignalLongSymbol" SG_ 1375 VCSEAT2L_a092_VEH_restraintStatu "VCSEAT2L_a092_VEH_restraintStatus";
BA_ "SystemSignalLongSymbol" SG_ 1375 VCSEAT2L_a093_VEH_restraintStatu "VCSEAT2L_a093_VEH_restraintStatus";
BA_ "SystemSignalLongSymbol" SG_ 1375 VCSEAT2L_a098_PARTY_thermalContr "VCSEAT2L_a098_PARTY_thermalControl";
BA_ "SystemSignalLongSymbol" SG_ 1375 VCSEAT2L_a101_LIPC_externalWatch "VCSEAT2L_a101_LIPC_externalWatchdogHeartBeat";
BA_ "SystemSignalLongSymbol" SG_ 1375 VCSEAT2L_a102_VEH_faultsAndExtra "VCSEAT2L_a102_VEH_faultsAndExtras";
BA_ "SystemSignalLongSymbol" SG_ 1375 VCSEAT2L_a108_PARTY_thermalContr "VCSEAT2L_a108_PARTY_thermalControl";
BA_ "SystemSignalLongSymbol" SG_ 1375 VCSEAT2L_a110_VEH_canLogAvailabi "VCSEAT2L_a110_VEH_canLogAvailability";
BA_ "SystemSignalLongSymbol" SG_ 1375 VCSEAT2L_a110_CH_airbagCutoffSta "VCSEAT2L_a110_CH_airbagCutoffStatus";
BA_ "SystemSignalLongSymbol" SG_ 1375 VCSEAT2L_a111_RIPC_epbPrivateSta "VCSEAT2L_a111_RIPC_epbPrivateState";
BA_ "SystemSignalLongSymbol" SG_ 1375 VCSEAT2L_a112_LIPC_epbPrivateSta "VCSEAT2L_a112_LIPC_epbPrivateState";
BA_ "SystemSignalLongSymbol" SG_ 1375 VCSEAT2L_a114_PARTY_wheelRotatio "VCSEAT2L_a114_PARTY_wheelRotation";
BA_ "SystemSignalLongSymbol" SG_ 1375 VCSEAT2L_a115_VEH_BLEResetReques "VCSEAT2L_a115_VEH_BLEResetRequest";
BA_ "SystemSignalLongSymbol" SG_ 1375 VCSEAT2L_a115_UI_corianderVehicl "VCSEAT2L_a115_UI_corianderVehicleControl";
BA_ "SystemSignalLongSymbol" SG_ 1375 VCSEAT2L_a116_VEH_restraintStatu "VCSEAT2L_a116_VEH_restraintStatus";
BA_ "SystemSignalLongSymbol" SG_ 1375 VCSEAT2L_a116_PARTY_restraintSta "VCSEAT2L_a116_PARTY_restraintStatus";
BA_ "SystemSignalLongSymbol" SG_ 1375 VCSEAT2L_a116_BDY_restraintStatu "VCSEAT2L_a116_BDY_restraintStatus";
BA_ "SystemSignalLongSymbol" SG_ 1375 VCSEAT2L_a117_BDY_restraintStatu "VCSEAT2L_a117_BDY_restraintStatus";
BA_ "SystemSignalLongSymbol" SG_ 1375 VCSEAT2L_a117_VEH_restraintStatu "VCSEAT2L_a117_VEH_restraintStatus";
BA_ "SystemSignalLongSymbol" SG_ 1375 VCSEAT2L_a117_BDY_falconSwitchSt "VCSEAT2L_a117_BDY_falconSwitchStatus";
BA_ "SystemSignalLongSymbol" SG_ 1375 VCSEAT2L_a117_VEH_intrusionSenso "VCSEAT2L_a117_VEH_intrusionSensorStatus";
BA_ "SystemSignalLongSymbol" SG_ 1375 VCSEAT2L_a117_PARTY_restraintSta "VCSEAT2L_a117_PARTY_restraintStatus";
BA_ "SystemSignalLongSymbol" SG_ 1375 VCSEAT2L_a117_PARTY_lightingSeco "VCSEAT2L_a117_PARTY_lightingSecondary";
BA_ "SystemSignalLongSymbol" SG_ 1375 VCSEAT2L_a118_VEH_12VBatteryStat "VCSEAT2L_a118_VEH_12VBatteryStatus";
BA_ "SystemSignalLongSymbol" SG_ 1375 VCSEAT2L_a118_PARTY_outputPowerS "VCSEAT2L_a118_PARTY_outputPowerStatus";
BA_ "SystemSignalLongSymbol" SG_ 1375 VCSEAT2L_a118_VEH_interNodeResis "VCSEAT2L_a118_VEH_interNodeResistance";
BA_ "SystemSignalLongSymbol" SG_ 1375 VCSEAT2L_a118_CH_12VBatteryStatu "VCSEAT2L_a118_CH_12VBatteryStatus";
BA_ "SystemSignalLongSymbol" SG_ 1375 VCSEAT2L_a118_CH_LVBMS_statusHig "VCSEAT2L_a118_CH_LVBMS_statusHigh";
BA_ "SystemSignalLongSymbol" SG_ 1375 VCSEAT2L_a118_BDY_outputPowerSta "VCSEAT2L_a118_BDY_outputPowerStatus";
BA_ "SystemSignalLongSymbol" SG_ 1375 VCSEAT2L_a118_PARTY_AP_vehicleSt "VCSEAT2L_a118_PARTY_AP_vehicleState1HzMuxed";
BA_ "SystemSignalLongSymbol" SG_ 1375 VCSEAT2L_a118_BDY_AP_vehicleStat "VCSEAT2L_a118_BDY_AP_vehicleState1HzMuxed";
BA_ "SystemSignalLongSymbol" SG_ 1375 VCSEAT2L_a118_PARTY_VCFRONT_came "VCSEAT2L_a118_PARTY_VCFRONT_cameraCleaningStatus";
BA_ "SystemSignalLongSymbol" SG_ 1375 VCSEAT2L_a120_PARTY_vehicleEstim "VCSEAT2L_a120_PARTY_vehicleEstimates";
BA_ "SystemSignalLongSymbol" SG_ 1375 VCSEAT2L_a120_VEH_aggregatedAxle "VCSEAT2L_a120_VEH_aggregatedAxleSpeed";
BA_ "SystemSignalLongSymbol" SG_ 1375 VCSEAT2L_a120_PARTY_aggregatedAx "VCSEAT2L_a120_PARTY_aggregatedAxleSpeed";
BA_ "SystemSignalLongSymbol" SG_ 1375 VCSEAT2L_a120_PARTY_autonomyHeal "VCSEAT2L_a120_PARTY_autonomyHealth";
BA_ "SystemSignalLongSymbol" SG_ 1375 VCSEAT2L_a120_PARTY_stalklessInt "VCSEAT2L_a120_PARTY_stalklessInterfaces";
BA_ "SystemSignalLongSymbol" SG_ 1375 VCSEAT2L_a120_VEH_estimatedBrake "VCSEAT2L_a120_VEH_estimatedBrakeTemp";
BA_ "SystemSignalLongSymbol" SG_ 1375 VCSEAT2L_a120_VEH_vehicleEstimat "VCSEAT2L_a120_VEH_vehicleEstimates";
BA_ "SystemSignalLongSymbol" SG_ 1375 VCSEAT2L_a210_seatMotorCalibrate "VCSEAT2L_a210_seatMotorCalibrated";
BA_ "Confidence" SG_ 1375 VCSEAT2L_a210_seatMotorCurrent 1;
BA_ "Confidence" SG_ 1375 VCSEAT2L_a210_seatMotorState 1;
BA_ "Confidence" SG_ 1375 VCSEAT2L_a210_seatSwitchBack 1;
BA_ "GenSigSNA" SG_ 1375 VCSEAT2L_a210_seatSwitchBack "0";
BA_ "Confidence" SG_ 1375 VCSEAT2L_a210_seatSwitchForward 1;
BA_ "GenSigSNA" SG_ 1375 VCSEAT2L_a210_seatSwitchForward "0";
BA_ "Confidence" SG_ 1375 VCSEAT2L_a211_seatMotorCurrent 1;
BA_ "Confidence" SG_ 1375 VCSEAT2L_a211_seatMotorPosReal 1;
BA_ "Confidence" SG_ 1375 VCSEAT2L_a211_seatMotorState 1;
BA_ "Confidence" SG_ 1375 VCSEAT2L_a211_seatSwitchBack 1;
BA_ "GenSigSNA" SG_ 1375 VCSEAT2L_a211_seatSwitchBack "0";
BA_ "Confidence" SG_ 1375 VCSEAT2L_a211_seatSwitchForward 1;
BA_ "GenSigSNA" SG_ 1375 VCSEAT2L_a211_seatSwitchForward "0";
BA_ "Confidence" SG_ 1375 VCSEAT2L_a212_seatMotorCurrent 1;
BA_ "Confidence" SG_ 1375 VCSEAT2L_a212_seatMotorPosReal 1;
BA_ "Confidence" SG_ 1375 VCSEAT2L_a212_seatMotorState 1;
BA_ "Confidence" SG_ 1375 VCSEAT2L_a212_seatSwitchBack 1;
BA_ "GenSigSNA" SG_ 1375 VCSEAT2L_a212_seatSwitchBack "0";
BA_ "Confidence" SG_ 1375 VCSEAT2L_a212_seatSwitchForward 1;
BA_ "GenSigSNA" SG_ 1375 VCSEAT2L_a212_seatSwitchForward "0";
BA_ "SystemSignalLongSymbol" SG_ 1375 VCSEAT2L_a213_seatMotorCalibrate "VCSEAT2L_a213_seatMotorCalibrated";
BA_ "Confidence" SG_ 1375 VCSEAT2L_a213_seatMotorCurrent 1;
BA_ "Confidence" SG_ 1375 VCSEAT2L_a213_seatMotorPosReal 1;
BA_ "Confidence" SG_ 1375 VCSEAT2L_a213_seatMotorState 1;
BA_ "Confidence" SG_ 1375 VCSEAT2L_a213_seatSwitchBack 1;
BA_ "GenSigSNA" SG_ 1375 VCSEAT2L_a213_seatSwitchBack "0";
BA_ "Confidence" SG_ 1375 VCSEAT2L_a213_seatSwitchForward 1;
BA_ "GenSigSNA" SG_ 1375 VCSEAT2L_a213_seatSwitchForward "0";
BA_ "Confidence" SG_ 1375 VCSEAT2L_a214_seatMotorCurrent 1;
BA_ "Confidence" SG_ 1375 VCSEAT2L_a214_seatMotorDCurrent 1;
BA_ "Confidence" SG_ 1375 VCSEAT2L_a214_seatMotorPosReal 1;
BA_ "Confidence" SG_ 1375 VCSEAT2L_a214_seatMotorState 1;
BA_ "Confidence" SG_ 1375 VCSEAT2L_a215_seatMotorCurrent 1;
BA_ "Confidence" SG_ 1375 VCSEAT2L_a215_seatMotorDCurrent 1;
BA_ "Confidence" SG_ 1375 VCSEAT2L_a215_seatMotorPosReal 1;
BA_ "Confidence" SG_ 1375 VCSEAT2L_a215_seatMotorState 1;
BA_ "SystemSignalLongSymbol" SG_ 1375 VCSEAT2L_a224_seatMotorCalibrate "VCSEAT2L_a224_seatMotorCalibrated";
BA_ "Confidence" SG_ 1375 VCSEAT2L_a224_seatMotorCurrent 1;
BA_ "Confidence" SG_ 1375 VCSEAT2L_a224_seatMotorState 1;
BA_ "Confidence" SG_ 1375 VCSEAT2L_a224_seatSwitchBack 1;
BA_ "GenSigSNA" SG_ 1375 VCSEAT2L_a224_seatSwitchBack "0";
BA_ "Confidence" SG_ 1375 VCSEAT2L_a224_seatSwitchForward 1;
BA_ "GenSigSNA" SG_ 1375 VCSEAT2L_a224_seatSwitchForward "0";
BA_ "SystemSignalLongSymbol" SG_ 1375 VCSEAT2L_a225_seatMotorCalibrate "VCSEAT2L_a225_seatMotorCalibrated";
BA_ "Confidence" SG_ 1375 VCSEAT2L_a225_seatMotorCurrent 1;
BA_ "Confidence" SG_ 1375 VCSEAT2L_a225_seatMotorState 1;
BA_ "Confidence" SG_ 1375 VCSEAT2L_a225_seatSwitchBack 1;
BA_ "GenSigSNA" SG_ 1375 VCSEAT2L_a225_seatSwitchBack "0";
BA_ "Confidence" SG_ 1375 VCSEAT2L_a225_seatSwitchForward 1;
BA_ "GenSigSNA" SG_ 1375 VCSEAT2L_a225_seatSwitchForward "0";
BA_ "SystemSignalLongSymbol" SG_ 1375 VCSEAT2L_a228_seatMotorCalibrate "VCSEAT2L_a228_seatMotorCalibrated";
BA_ "Confidence" SG_ 1375 VCSEAT2L_a228_seatMotorCurrent 1;
BA_ "Confidence" SG_ 1375 VCSEAT2L_a228_seatMotorPosReal 1;
BA_ "Confidence" SG_ 1375 VCSEAT2L_a228_seatMotorState 1;
BA_ "Confidence" SG_ 1375 VCSEAT2L_a228_seatSwitchBack 1;
BA_ "GenSigSNA" SG_ 1375 VCSEAT2L_a228_seatSwitchBack "0";
BA_ "Confidence" SG_ 1375 VCSEAT2L_a228_seatSwitchForward 1;
BA_ "GenSigSNA" SG_ 1375 VCSEAT2L_a228_seatSwitchForward "0";
BA_ "SystemSignalLongSymbol" SG_ 1375 VCSEAT2L_a229_seatMotorCalibrate "VCSEAT2L_a229_seatMotorCalibrated";
BA_ "Confidence" SG_ 1375 VCSEAT2L_a229_seatMotorCurrent 1;
BA_ "Confidence" SG_ 1375 VCSEAT2L_a229_seatMotorPosReal 1;
BA_ "Confidence" SG_ 1375 VCSEAT2L_a229_seatMotorState 1;
BA_ "Confidence" SG_ 1375 VCSEAT2L_a229_seatSwitchBack 1;
BA_ "GenSigSNA" SG_ 1375 VCSEAT2L_a229_seatSwitchBack "0";
BA_ "Confidence" SG_ 1375 VCSEAT2L_a229_seatSwitchForward 1;
BA_ "GenSigSNA" SG_ 1375 VCSEAT2L_a229_seatSwitchForward "0";
BA_ "Confidence" SG_ 1375 VCSEAT2L_a232_seatMotorCurrent 1;
BA_ "Confidence" SG_ 1375 VCSEAT2L_a232_seatMotorPosReal 1;
BA_ "Confidence" SG_ 1375 VCSEAT2L_a232_seatMotorState 1;
BA_ "Confidence" SG_ 1375 VCSEAT2L_a232_seatSwitchBack 1;
BA_ "GenSigSNA" SG_ 1375 VCSEAT2L_a232_seatSwitchBack "0";
BA_ "Confidence" SG_ 1375 VCSEAT2L_a232_seatSwitchForward 1;
BA_ "GenSigSNA" SG_ 1375 VCSEAT2L_a232_seatSwitchForward "0";
BA_ "Confidence" SG_ 1375 VCSEAT2L_a233_seatMotorCurrent 1;
BA_ "Confidence" SG_ 1375 VCSEAT2L_a233_seatMotorPosReal 1;
BA_ "Confidence" SG_ 1375 VCSEAT2L_a233_seatMotorState 1;
BA_ "Confidence" SG_ 1375 VCSEAT2L_a233_seatSwitchBack 1;
BA_ "GenSigSNA" SG_ 1375 VCSEAT2L_a233_seatSwitchBack "0";
BA_ "Confidence" SG_ 1375 VCSEAT2L_a233_seatSwitchForward 1;
BA_ "GenSigSNA" SG_ 1375 VCSEAT2L_a233_seatSwitchForward "0";
BA_ "Confidence" SG_ 1375 VCSEAT2L_a239_seatHeatCurrent 1;
BA_ "Confidence" SG_ 1375 VCSEAT2L_a239_seatHeatTmp 1;
BA_ "Confidence" SG_ 1375 VCSEAT2L_a239_seatHeatTmpTarget 1;
BA_ "Confidence" SG_ 1375 VCSEAT2L_a240_seatHeatCurrent 1;
BA_ "Confidence" SG_ 1375 VCSEAT2L_a240_seatHeatTmp 1;
BA_ "Confidence" SG_ 1375 VCSEAT2L_a251_seatMotorCurrent 1;
BA_ "Confidence" SG_ 1375 VCSEAT2L_a251_seatMotorPosReal 1;
BA_ "Confidence" SG_ 1375 VCSEAT2L_a251_seatMotorState 1;
BA_ "Confidence" SG_ 1375 VCSEAT2L_a251_seatSwitchBack 1;
BA_ "GenSigSNA" SG_ 1375 VCSEAT2L_a251_seatSwitchBack "0";
BA_ "Confidence" SG_ 1375 VCSEAT2L_a251_seatSwitchForward 1;
BA_ "GenSigSNA" SG_ 1375 VCSEAT2L_a251_seatSwitchForward "0";
BA_ "Confidence" SG_ 1375 VCSEAT2L_a252_seatMotorCurrent 1;
BA_ "Confidence" SG_ 1375 VCSEAT2L_a252_seatMotorPosReal 1;
BA_ "Confidence" SG_ 1375 VCSEAT2L_a252_seatMotorState 1;
BA_ "Confidence" SG_ 1375 VCSEAT2L_a252_seatSwitchBack 1;
BA_ "GenSigSNA" SG_ 1375 VCSEAT2L_a252_seatSwitchBack "0";
BA_ "Confidence" SG_ 1375 VCSEAT2L_a252_seatSwitchForward 1;
BA_ "GenSigSNA" SG_ 1375 VCSEAT2L_a252_seatSwitchForward "0";
BA_ "Confidence" SG_ 1375 VCSEAT2L_a260_seatStatePrev 1;
BA_ "Confidence" SG_ 1375 VCSEAT2L_a260_obstacleDetectReas 1;
BA_ "SystemSignalLongSymbol" SG_ 1375 VCSEAT2L_a260_obstacleDetectReas "VCSEAT2L_a260_obstacleDetectReason";
BA_ "Confidence" SG_ 1375 VCSEAT2L_a260_obstacleDetectPosi 1;
BA_ "SystemSignalLongSymbol" SG_ 1375 VCSEAT2L_a260_obstacleDetectPosi "VCSEAT2L_a260_obstacleDetectPosition";
BA_ "SystemSignalLongSymbol" SG_ 1375 VCSEAT2L_a260_accelLookbackTripD "VCSEAT2L_a260_accelLookbackTripDepth";
BA_ "Confidence" SG_ 1375 VCSEAT2L_a260_seatMotorCurrent 1;
BA_ "Confidence" SG_ 1375 VCSEAT2L_a261_seatStatePrev 1;
BA_ "Confidence" SG_ 1375 VCSEAT2L_a261_obstacleDetectReas 1;
BA_ "SystemSignalLongSymbol" SG_ 1375 VCSEAT2L_a261_obstacleDetectReas "VCSEAT2L_a261_obstacleDetectReason";
BA_ "Confidence" SG_ 1375 VCSEAT2L_a261_obstacleDetectPosi 1;
BA_ "SystemSignalLongSymbol" SG_ 1375 VCSEAT2L_a261_obstacleDetectPosi "VCSEAT2L_a261_obstacleDetectPosition";
BA_ "SystemSignalLongSymbol" SG_ 1375 VCSEAT2L_a261_accelLookbackTripD "VCSEAT2L_a261_accelLookbackTripDepth";
BA_ "Confidence" SG_ 1375 VCSEAT2L_a261_seatMotorCurrent 1;
BA_ "Confidence" SG_ 1375 VCSEAT2L_a263_seatMotorCurrent 1;
BA_ "Confidence" SG_ 1375 VCSEAT2L_a263_seatMotorDCurrent 1;
BA_ "Confidence" SG_ 1375 VCSEAT2L_a263_seatMotorPosReal 1;
BA_ "Confidence" SG_ 1375 VCSEAT2L_a263_seatMotorState 1;
BA_ "Confidence" SG_ 1375 VCSEAT2L_a264_seatMotorCurrent 1;
BA_ "Confidence" SG_ 1375 VCSEAT2L_a264_seatMotorDCurrent 1;
BA_ "Confidence" SG_ 1375 VCSEAT2L_a264_seatMotorPosReal 1;
BA_ "Confidence" SG_ 1375 VCSEAT2L_a264_seatMotorState 1;
BA_ "Confidence" SG_ 1375 VCSEAT2L_a267_seatMotorCurrent 1;
BA_ "Confidence" SG_ 1375 VCSEAT2L_a267_seatMotorDCurrent 1;
BA_ "Confidence" SG_ 1375 VCSEAT2L_a267_seatMotorPosReal 1;
BA_ "Confidence" SG_ 1375 VCSEAT2L_a267_seatMotorState 1;
BA_ "Confidence" SG_ 1375 VCSEAT2L_a268_seatMotorCurrent 1;
BA_ "Confidence" SG_ 1375 VCSEAT2L_a268_seatMotorDCurrent 1;
BA_ "Confidence" SG_ 1375 VCSEAT2L_a268_seatMotorPosReal 1;
BA_ "Confidence" SG_ 1375 VCSEAT2L_a268_seatMotorState 1;
BA_ "SystemSignalLongSymbol" SG_ 1375 VCSEAT2L_a270_isRearwardEndstopU "VCSEAT2L_a270_isRearwardEndstopUncalibrated";
BA_ "SystemSignalLongSymbol" SG_ 1375 VCSEAT2L_a270_isAbsPosSensorUnca "VCSEAT2L_a270_isAbsPosSensorUncalibrated";
BA_ "Confidence" SG_ 1375 VCSEAT2L_a270_seatState 1;
BA_ "GenSigSNA" SG_ 1375 VCSEAT2L_a270_seatState "15";
BA_ "Confidence" SG_ 1375 VCSEAT2L_a270_motorType 1;
BA_ "Confidence" SG_ 1375 VCSEAT2L_a270_absPosSensState 1;
BA_ "Confidence" SG_ 1375 VCSEAT2L_a273_angle 1;
BA_ "Confidence" SG_ 1375 VCSEAT2L_a273_seatStatePrev 1;
BA_ "GenSigSNA" SG_ 1375 VCSEAT2L_a273_seatStatePrev "15";
BA_ "Confidence" SG_ 1375 VCSEAT2L_a273_obstacleDetectReas 1;
BA_ "SystemSignalLongSymbol" SG_ 1375 VCSEAT2L_a273_obstacleDetectReas "VCSEAT2L_a273_obstacleDetectReason";
BA_ "SystemSignalLongSymbol" SG_ 1375 VCSEAT2L_a273_accelLookbackTripD "VCSEAT2L_a273_accelLookbackTripDepth";
BA_ "Confidence" SG_ 1375 VCSEAT2L_a273_duty 1;
BA_ "Confidence" SG_ 1375 VCSEAT2L_a273_currentAbsFilt 1;
BA_ "Confidence" SG_ 1375 VCSEAT2L_a273_motorType 1;
BA_ "SystemSignalLongSymbol" SG_ 1375 VCSEAT2L_a273_absolutePosSensorF "VCSEAT2L_a273_absolutePosSensorForward";
BA_ "Confidence" SG_ 1375 VCSEAT2L_a273_cabinTemp 1;
BA_ "SystemSignalLongSymbol" SG_ 1375 VCSEAT2L_a277_isRearwardEndstopU "VCSEAT2L_a277_isRearwardEndstopUncalibrated";
BA_ "SystemSignalLongSymbol" SG_ 1375 VCSEAT2L_a277_isAbsPosSensorUnca "VCSEAT2L_a277_isAbsPosSensorUncalibrated";
BA_ "Confidence" SG_ 1375 VCSEAT2L_a278_seatState 1;
BA_ "GenSigSNA" SG_ 1375 VCSEAT2L_a278_seatState "15";
BA_ "Confidence" SG_ 1375 VCSEAT2L_a290_occupancySensorV 1;
BA_ "Confidence" SG_ 1375 VCSEAT2L_a290_railVoltage 1;
BA_ "Confidence" SG_ 1375 VCSEAT2L_a291_buckleSensorVoltag 1;
BA_ "SystemSignalLongSymbol" SG_ 1375 VCSEAT2L_a291_buckleSensorVoltag "VCSEAT2L_a291_buckleSensorVoltage";
BA_ "Confidence" SG_ 1375 VCSEAT2L_a291_railVoltage 1;
BA_ "SystemSignalLongSymbol" SG_ 1375 VCSEAT2L_a426_seatMotorCalibrate "VCSEAT2L_a426_seatMotorCalibrated";
BA_ "Confidence" SG_ 1375 VCSEAT2L_a426_seatMotorCurrent 1;
BA_ "Confidence" SG_ 1375 VCSEAT2L_a426_seatMotorPosReal 1;
BA_ "Confidence" SG_ 1375 VCSEAT2L_a426_seatMotorState 1;
BA_ "Confidence" SG_ 1375 VCSEAT2L_a426_seatSwitchBack 1;
BA_ "GenSigSNA" SG_ 1375 VCSEAT2L_a426_seatSwitchBack "0";
BA_ "Confidence" SG_ 1375 VCSEAT2L_a426_seatSwitchForward 1;
BA_ "GenSigSNA" SG_ 1375 VCSEAT2L_a426_seatSwitchForward "0";
BA_ "Confidence" SG_ 1375 VCSEAT2L_a426_cabinTmp 1;
BA_ "SystemSignalLongSymbol" SG_ 1375 VCSEAT2L_a427_seatMotorCalibrate "VCSEAT2L_a427_seatMotorCalibrated";
BA_ "Confidence" SG_ 1375 VCSEAT2L_a427_seatMotorCurrent 1;
BA_ "Confidence" SG_ 1375 VCSEAT2L_a427_seatMotorPosReal 1;
BA_ "Confidence" SG_ 1375 VCSEAT2L_a427_seatMotorState 1;
BA_ "Confidence" SG_ 1375 VCSEAT2L_a427_seatSwitchBack 1;
BA_ "GenSigSNA" SG_ 1375 VCSEAT2L_a427_seatSwitchBack "0";
BA_ "Confidence" SG_ 1375 VCSEAT2L_a427_seatSwitchForward 1;
BA_ "GenSigSNA" SG_ 1375 VCSEAT2L_a427_seatSwitchForward "0";
BA_ "Confidence" SG_ 1375 VCSEAT2L_a427_cabinTmp 1;
BA_ "SystemSignalLongSymbol" SG_ 1375 VCSEAT2L_a428_seatMotorCalibrate "VCSEAT2L_a428_seatMotorCalibrated";
BA_ "Confidence" SG_ 1375 VCSEAT2L_a428_seatMotorCurrent 1;
BA_ "Confidence" SG_ 1375 VCSEAT2L_a428_seatMotorPosReal 1;
BA_ "Confidence" SG_ 1375 VCSEAT2L_a428_seatMotorState 1;
BA_ "Confidence" SG_ 1375 VCSEAT2L_a428_seatSwitchBack 1;
BA_ "GenSigSNA" SG_ 1375 VCSEAT2L_a428_seatSwitchBack "0";
BA_ "Confidence" SG_ 1375 VCSEAT2L_a428_seatSwitchForward 1;
BA_ "GenSigSNA" SG_ 1375 VCSEAT2L_a428_seatSwitchForward "0";
BA_ "Confidence" SG_ 1375 VCSEAT2L_a428_cabinTmp 1;
BA_ "SystemSignalLongSymbol" SG_ 1375 VCSEAT2L_a429_seatMotorCalibrate "VCSEAT2L_a429_seatMotorCalibrated";
BA_ "Confidence" SG_ 1375 VCSEAT2L_a429_seatMotorCurrent 1;
BA_ "Confidence" SG_ 1375 VCSEAT2L_a429_seatMotorPosReal 1;
BA_ "Confidence" SG_ 1375 VCSEAT2L_a429_seatMotorState 1;
BA_ "Confidence" SG_ 1375 VCSEAT2L_a429_seatSwitchBack 1;
BA_ "GenSigSNA" SG_ 1375 VCSEAT2L_a429_seatSwitchBack "0";
BA_ "Confidence" SG_ 1375 VCSEAT2L_a429_seatSwitchForward 1;
BA_ "GenSigSNA" SG_ 1375 VCSEAT2L_a429_seatSwitchForward "0";
BA_ "Confidence" SG_ 1375 VCSEAT2L_a429_cabinTmp 1;
BA_ "SystemSignalLongSymbol" SG_ 1375 VCSEAT2L_a444_highSide2GateDrive "VCSEAT2L_a444_highSide2GateDriver";
BA_ "SystemSignalLongSymbol" SG_ 1375 VCSEAT2L_a444_highSide1GateDrive "VCSEAT2L_a444_highSide1GateDriver";
BA_ "SystemSignalLongSymbol" SG_ 1375 VCSEAT2L_a444_highSide2OverCuren "VCSEAT2L_a444_highSide2OverCurent";
BA_ "SystemSignalLongSymbol" SG_ 1375 VCSEAT2L_a444_highSide1OverCuren "VCSEAT2L_a444_highSide1OverCurent";
BA_ "Confidence" SG_ 1375 VCSEAT2L_a571_seatHeatCurrent 1;
BA_ "Confidence" SG_ 1375 VCSEAT2L_a571_seatHeatTmp 1;
BA_ "Confidence" SG_ 892 VCSEAT2L_matrixIndex 1;
BA_ "SystemSignalLongSymbol" SG_ 892 VCSEAT2L_a030_ECULogUploadReques "VCSEAT2L_a030_ECULogUploadRequest";
BA_ "SystemSignalLongSymbol" SG_ 892 VCSEAT2L_a058_inputRHighSyncDebu "VCSEAT2L_a058_inputRHighSyncDebug";
BA_ "SystemSignalLongSymbol" SG_ 892 VCSEAT2L_a059_inputResistanceHig "VCSEAT2L_a059_inputResistanceHigh";
BA_ "SystemSignalLongSymbol" SG_ 892 VCSEAT2L_a190_seatChoreographyIs "VCSEAT2L_a190_seatChoreographyIsBlockedByFrontSeat";
BA_ "SystemSignalLongSymbol" SG_ 892 VCSEAT2L_a191_seatChoreographyIs "VCSEAT2L_a191_seatChoreographyIsBlockedBySecondSeat";
BA_ "SystemSignalLongSymbol" SG_ 892 VCSEAT2L_a200_motorPhantomEncode "VCSEAT2L_a200_motorPhantomEncoder";
BA_ "SystemSignalLongSymbol" SG_ 892 VCSEAT2L_a219_motorCurrentDropou "VCSEAT2L_a219_motorCurrentDropout";
BA_ "SystemSignalLongSymbol" SG_ 892 VCSEAT2L_a234_seatTrackStatsFrom "VCSEAT2L_a234_seatTrackStatsFromLastStateDbg";
BA_ "SystemSignalLongSymbol" SG_ 892 VCSEAT2L_a235_seatTrackStatsFrom "VCSEAT2L_a235_seatTrackStatsFromLastStateDbg2";
BA_ "SystemSignalLongSymbol" SG_ 892 VCSEAT2L_a236_seatArmrestStatsFr "VCSEAT2L_a236_seatArmrestStatsFromLastStateDbg";
BA_ "SystemSignalLongSymbol" SG_ 892 VCSEAT2L_a237_seatArmrestStatsFr "VCSEAT2L_a237_seatArmrestStatsFromLastStateDbg2";
BA_ "SystemSignalLongSymbol" SG_ 892 VCSEAT2L_a238_seatArmrestInhibit "VCSEAT2L_a238_seatArmrestInhibitedByBackrest";
BA_ "SystemSignalLongSymbol" SG_ 892 VCSEAT2L_a241_seatArmrestHistory "VCSEAT2L_a241_seatArmrestHistoryScore";
BA_ "SystemSignalLongSymbol" SG_ 892 VCSEAT2L_a243_seatArmrestHistory "VCSEAT2L_a243_seatArmrestHistoryScoreDbg";
BA_ "SystemSignalLongSymbol" SG_ 892 VCSEAT2L_a244_seatArmrestSpeedTa "VCSEAT2L_a244_seatArmrestSpeedTableReferenceStatus";
BA_ "SystemSignalLongSymbol" SG_ 892 VCSEAT2L_a245_seatArmrestEcuLogS "VCSEAT2L_a245_seatArmrestEcuLogStatus";
BA_ "SystemSignalLongSymbol" SG_ 892 VCSEAT2L_a260_seatTrackObstacleD "VCSEAT2L_a260_seatTrackObstacleDetected";
BA_ "SystemSignalLongSymbol" SG_ 892 VCSEAT2L_a261_seatArmrestObstacl "VCSEAT2L_a261_seatArmrestObstacleDetected";
BA_ "SystemSignalLongSymbol" SG_ 892 VCSEAT2L_a263_seatTrackStallDebu "VCSEAT2L_a263_seatTrackStallDebug";
BA_ "SystemSignalLongSymbol" SG_ 892 VCSEAT2L_a268_seatBackHCEncStlDb "VCSEAT2L_a268_seatBackHCEncStlDbg";
BA_ "SystemSignalLongSymbol" SG_ 892 VCSEAT2L_a271_seatPositionNonsen "VCSEAT2L_a271_seatPositionNonsensical";
BA_ "SystemSignalLongSymbol" SG_ 892 VCSEAT2L_a272_seatAbsPosOffsetAp "VCSEAT2L_a272_seatAbsPosOffsetApplied";
BA_ "SystemSignalLongSymbol" SG_ 892 VCSEAT2L_a273_seatObstacleDetect "VCSEAT2L_a273_seatObstacleDetected";
BA_ "SystemSignalLongSymbol" SG_ 892 VCSEAT2L_a275_seatAbsPosSensorTr "VCSEAT2L_a275_seatAbsPosSensorTransitionDbg";
BA_ "SystemSignalLongSymbol" SG_ 892 VCSEAT2L_a276_seatStatsFromLastS "VCSEAT2L_a276_seatStatsFromLastStateDbg";
BA_ "SystemSignalLongSymbol" SG_ 892 VCSEAT2L_a277_seatRequestWhileUn "VCSEAT2L_a277_seatRequestWhileUncalibrated";
BA_ "SystemSignalLongSymbol" SG_ 892 VCSEAT2L_a278_seatClashAvoidance "VCSEAT2L_a278_seatClashAvoidanceBlocked";
BA_ "SystemSignalLongSymbol" SG_ 892 VCSEAT2L_a280_seatStatsFromLastS "VCSEAT2L_a280_seatStatsFromLastStateDbg2";
BA_ "SystemSignalLongSymbol" SG_ 892 VCSEAT2L_a428_seatAbuseBufferWar "VCSEAT2L_a428_seatAbuseBufferWarn";
BA_ "SystemSignalLongSymbol" SG_ 892 VCSEAT2L_a429_seatAbuseBufferFul "VCSEAT2L_a429_seatAbuseBufferFull";
BA_ "SystemSignalLongSymbol" SG_ 892 VCSEAT2L_a526_pcbaOverTemperatur "VCSEAT2L_a526_pcbaOverTemperature";
BA_ "SystemSignalLongSymbol" SG_ 892 VCSEAT2L_a571_seatHeatDisabledRe "VCSEAT2L_a571_seatHeatDisabledRear";
BA_ "Confidence" SG_ 764 VCSEAT2L_row2SeatStatusIndex 1;
BA_ "Confidence" SG_ 764 VCSEAT2L_seatTrackPosReal 0;
BA_ "Confidence" SG_ 764 VCSEAT2L_seatTrackPosOffset 0;
BA_ "Confidence" SG_ 764 VCSEAT2L_seatReclineState 0;
BA_ "GenSigSNA" SG_ 764 VCSEAT2L_seatReclineState "15";
BA_ "Confidence" SG_ 764 VCSEAT2L_seatReclineCalibrated 0;
BA_ "Confidence" SG_ 764 VCSEAT2L_seatReclinePositionStat 0;
BA_ "GenSigSNA" SG_ 764 VCSEAT2L_seatReclinePositionStat "4";
BA_ "SystemSignalLongSymbol" SG_ 764 VCSEAT2L_seatReclinePositionStat "VCSEAT2L_seatReclinePositionState";
BA_ "Confidence" SG_ 764 VCSEAT2L_seatReclineAbsPosS_0001 0;
BA_ "SystemSignalLongSymbol" SG_ 764 VCSEAT2L_seatReclineAbsPosS_0001 "VCSEAT2L_seatReclineAbsPosSwitchTransPoint";
BA_ "Confidence" SG_ 764 VCSEAT2L_seatReclineAbsPosSwitch 0;
BA_ "GenSigSNA" SG_ 764 VCSEAT2L_seatReclineAbsPosSwitch "0";
BA_ "SystemSignalLongSymbol" SG_ 764 VCSEAT2L_seatReclineAbsPosSwitch "VCSEAT2L_seatReclineAbsPosSwitchState";
BA_ "Confidence" SG_ 764 VCSEAT2L_seatReclineFoldAllowed 0;
BA_ "Confidence" SG_ 764 VCSEAT2L_seatReclineUnfoldAllowe 0;
BA_ "SystemSignalLongSymbol" SG_ 764 VCSEAT2L_seatReclineUnfoldAllowe "VCSEAT2L_seatReclineUnfoldAllowed";
BA_ "Confidence" SG_ 764 VCSEAT2L_seatReclineAdjustmentAl 0;
BA_ "SystemSignalLongSymbol" SG_ 764 VCSEAT2L_seatReclineAdjustmentAl "VCSEAT2L_seatReclineAdjustmentAllowed";
BA_ "Confidence" SG_ 764 VCSEAT2L_seat1RClashAvoidanceBlo 0;
BA_ "SystemSignalLongSymbol" SG_ 764 VCSEAT2L_seat1RClashAvoidanceBlo "VCSEAT2L_seat1RClashAvoidanceBlockedReason";
BA_ "Confidence" SG_ 764 VCSEAT2L_seat1RClashAvoidanceSta 0;
BA_ "SystemSignalLongSymbol" SG_ 764 VCSEAT2L_seat1RClashAvoidanceSta "VCSEAT2L_seat1RClashAvoidanceState";
BA_ "Confidence" SG_ 764 VCSEAT2L_seatReclineChoreoBlocke 0;
BA_ "SystemSignalLongSymbol" SG_ 764 VCSEAT2L_seatReclineChoreoBlocke "VCSEAT2L_seatReclineChoreoBlockedByOccupancy";
BA_ "Confidence" SG_ 764 VCSEAT2L_seatReclineNextToggleDi 0;
BA_ "GenSigSNA" SG_ 764 VCSEAT2L_seatReclineNextToggleDi "2";
BA_ "SystemSignalLongSymbol" SG_ 764 VCSEAT2L_seatReclineNextToggleDi "VCSEAT2L_seatReclineNextToggleDirection";
BA_ "Confidence" SG_ 1986 VCSEAT2L_seatStatus2Index 1;
BA_ "Confidence" SG_ 1986 VCSEAT2L_choreography2RState 0;
BA_ "Confidence" SG_ 1986 VCSEAT2L_choreography3RState 0;
BA_ "Confidence" SG_ 1986 VCSEAT2L_choreography1RIsAllowed 0;
BA_ "SystemSignalLongSymbol" SG_ 1986 VCSEAT2L_choreography1RIsAllowed "VCSEAT2L_choreography1RIsAllowedToMove";
BA_ "Confidence" SG_ 1986 VCSEAT2L_choreography2RIsAllowed 0;
BA_ "SystemSignalLongSymbol" SG_ 1986 VCSEAT2L_choreography2RIsAllowed "VCSEAT2L_choreography2RIsAllowedToMove";
BA_ "Confidence" SG_ 1986 VCSEAT2L_choreography1RTrackVelo 0;
BA_ "SystemSignalLongSymbol" SG_ 1986 VCSEAT2L_choreography1RTrackVelo "VCSEAT2L_choreography1RTrackVelocityType";
BA_ "Confidence" SG_ 1986 VCSEAT2L_choreography1RBackrestV 0;
BA_ "SystemSignalLongSymbol" SG_ 1986 VCSEAT2L_choreography1RBackrestV "VCSEAT2L_choreography1RBackrestVelocityType";
BA_ "Confidence" SG_ 1986 VCSEAT2L_choreography2RTrackVelo 0;
BA_ "SystemSignalLongSymbol" SG_ 1986 VCSEAT2L_choreography2RTrackVelo "VCSEAT2L_choreography2RTrackVelocityType";
BA_ "Confidence" SG_ 1986 VCSEAT2L_choreography2RBackrestV 0;
BA_ "SystemSignalLongSymbol" SG_ 1986 VCSEAT2L_choreography2RBackrestV "VCSEAT2L_choreography2RBackrestVelocityType";
BA_ "Confidence" SG_ 1986 VCSEAT2L_choreography3RBackrestV 0;
BA_ "SystemSignalLongSymbol" SG_ 1986 VCSEAT2L_choreography3RBackrestV "VCSEAT2L_choreography3RBackrestVelocityType";
BA_ "Confidence" SG_ 1986 VCSEAT2L_choreographyState 0;
BA_ "Confidence" SG_ 1986 VCSEAT2L_choreographyCollisionPa 0;
BA_ "SystemSignalLongSymbol" SG_ 1986 VCSEAT2L_choreographyCollisionPa "VCSEAT2L_choreographyCollisionPair";
BA_ "Confidence" SG_ 1986 VCSEAT2L_2rMovingForChoreography 0;
VAL_ 963 VCRIGHT_switchStatusIndex 1 "1" 0 "0" ;
VAL_ 963 VCRIGHT_frontOccupancySwitch 3 "SWITCH_FAULT" 2 "SWITCH_ON" 1 "SWITCH_OFF" 0 "SWITCH_SNA" ;
VAL_ 963 VCRIGHT_frontBuckleSwitch 3 "SWITCH_FAULT" 2 "SWITCH_ON" 1 "SWITCH_OFF" 0 "SWITCH_SNA" ;
VAL_ 963 VCRIGHT_rearCenterBuckleSwitch 3 "SWITCH_FAULT" 2 "SWITCH_ON" 1 "SWITCH_OFF" 0 "SWITCH_SNA" ;
VAL_ 963 VCRIGHT_rearRightBuckleSwitch 3 "SWITCH_FAULT" 2 "SWITCH_ON" 1 "SWITCH_OFF" 0 "SWITCH_SNA" ;
VAL_ 963 VCRIGHT_frontSeatTrackBack 3 "SWITCH_FAULT" 2 "SWITCH_ON" 1 "SWITCH_OFF" 0 "SWITCH_SNA" ;
VAL_ 963 VCRIGHT_frontSeatTrackForward 3 "SWITCH_FAULT" 2 "SWITCH_ON" 1 "SWITCH_OFF" 0 "SWITCH_SNA" ;
VAL_ 963 VCRIGHT_frontSeatTiltDown 3 "SWITCH_FAULT" 2 "SWITCH_ON" 1 "SWITCH_OFF" 0 "SWITCH_SNA" ;
VAL_ 963 VCRIGHT_frontSeatTiltUp 3 "SWITCH_FAULT" 2 "SWITCH_ON" 1 "SWITCH_OFF" 0 "SWITCH_SNA" ;
VAL_ 963 VCRIGHT_frontSeatLiftDown 3 "SWITCH_FAULT" 2 "SWITCH_ON" 1 "SWITCH_OFF" 0 "SWITCH_SNA" ;
VAL_ 963 VCRIGHT_frontSeatLiftUp 3 "SWITCH_FAULT" 2 "SWITCH_ON" 1 "SWITCH_OFF" 0 "SWITCH_SNA" ;
VAL_ 963 VCRIGHT_frontSeatBackrestBack 3 "SWITCH_FAULT" 2 "SWITCH_ON" 1 "SWITCH_OFF" 0 "SWITCH_SNA" ;
VAL_ 963 VCRIGHT_frontSeatBackrestForward 3 "SWITCH_FAULT" 2 "SWITCH_ON" 1 "SWITCH_OFF" 0 "SWITCH_SNA" ;
VAL_ 963 VCRIGHT_frontSeatLumbarDown 3 "SWITCH_FAULT" 2 "SWITCH_ON" 1 "SWITCH_OFF" 0 "SWITCH_SNA" ;
VAL_ 963 VCRIGHT_frontSeatLumbarUp 3 "SWITCH_FAULT" 2 "SWITCH_ON" 1 "SWITCH_OFF" 0 "SWITCH_SNA" ;
VAL_ 963 VCRIGHT_frontSeatLumbarIn 3 "SWITCH_FAULT" 2 "SWITCH_ON" 1 "SWITCH_OFF" 0 "SWITCH_SNA" ;
VAL_ 963 VCRIGHT_frontSeatResistiveOccupa 3 "SWITCH_FAULT" 2 "SWITCH_ON" 1 "SWITCH_OFF" 0 "SWITCH_SNA" ;
VAL_ 963 VCRIGHT_2RowSeatReclineSwitchpac 6 "FAULT" 5 "REARWARD_FAST" 4 "REARWARD_SLOW" 3 "FORWARD_FAST" 2 "FORWARD_SLOW" 1 "INACTIVE" 0 "DISCONNECTED" ;
VAL_ 963 VCRIGHT_frontSeatThighSupportRet 3 "SWITCH_FAULT" 2 "SWITCH_ON" 1 "SWITCH_OFF" 0 "SWITCH_SNA" ;
VAL_ 899 VCRIGHT_thsTemperature 255 "SNA" ;
VAL_ 899 VCRIGHT_thsState 4 "IDLE" 3 "WAIT_CRC_RESPONSE" 2 "WAIT_CRC_REQUEST" 1 "CONFIG" 0 "INIT" ;
VAL_ 899 VCRIGHT_thsLINCurrentSchedule 7 "OTHER" 3 "DIAGNOSTIC" 2 "CONFIG" 1 "MAIN" 0 "OFF" ;
VAL_ 899 VCRIGHT_thsHumidity 127 "SNA" ;
VAL_ 899 VCRIGHT_estimatedVehicleSituatio 2 "VEHICLE_SITUATION_OUTDOOR" 1 "VEHICLE_SITUATION_INDOOR" 0 "VEHICLE_SITUATION_UNKNOWN" ;
VAL_ 899 VCRIGHT_thsSolarLoadInfrared 1023 "SNA" ;
VAL_ 899 VCRIGHT_thsSolarLoadVisible 1023 "SNA" ;
VAL_ 899 VCRIGHT_estimatedThsSolarLoad 1023 "SNA" ;
VAL_ 1059 VCRIGHT_nmKeepAwakeReason 31 "VCRIGHT_KEEPAWAKE_REASON_MULTIPLE" 17 "VCRIGHT_KEEPAWAKE_REASON_DEFOG_CMD" 16 "VCRIGHT_KEEPAWAKE_REASON_DEFOG_CAMERA" 15 "VCRIGHT_KEEPAWAKE_REASON_VOC_PURGE" 14 "VCRIGHT_KEEPAWAKE_REASON_OTHER" 12 "VCRIGHT_KEEPAWAKE_REASON_TRUNK_SWITCH" 11 "VCRIGHT_KEEPAWAKE_REASON_HVAC_EVAP_DRYING" 10 "VCRIGHT_KEEPAWAKE_REASON_UDS_ACTIVE" 9 "VCRIGHT_KEEPAWAKE_REASON_TRUNK_LIGHT" 8 "VCRIGHT_KEEPAWAKE_REASON_SEAT" 7 "VCRIGHT_KEEPAWAKE_REASON_HANDLE" 6 "VCRIGHT_KEEPAWAKE_REASON_EPB_SUMMON_ACTIVE" 5 "VCRIGHT_KEEPAWAKE_REASON_CLOSURE_LATCH" 4 "VCRIGHT_KEEPAWAKE_REASON_HVAC_PRECONDITIONING" 3 "VCRIGHT_KEEPAWAKE_REASON_HVAC_CABIN_PURGE" 2 "VCRIGHT_KEEPAWAKE_REASON_EPB_NOT_SECURE" 1 "VCRIGHT_KEEPAWAKE_REASON_EPB_STATE_NOT_SAVED" 0 "VCRIGHT_KEEPAWAKE_REASON_NONE_SNA" ;
VAL_ 1059 VCRIGHT_nmWakeUpReason 15 "VCRIGHT_WAKEUP_REASON_UNKNOWN" 14 "VCRIGHT_WAKEUP_REASON_DEFOG_CMD" 13 "VCRIGHT_WAKEUP_REASON_DEFOG_CAMERA" 12 "VCRIGHT_WAKEUP_REASON_VOC_PURGE" 11 "VCRIGHT_WAKEUP_REASON_POWER_ON_RESET" 10 "VCRIGHT_WAKEUP_REASON_CABIN_HOT" 9 "VCRIGHT_WAKEUP_REASON_TRUNK_LATCH" 8 "VCRIGHT_WAKEUP_REASON_TRUNK_SWITCH" 7 "VCRIGHT_WAKEUP_REASON_LIN_RX" 6 "VCRIGHT_WAKEUP_REASON_EXTERIOR_HANDLE" 5 "VCRIGHT_WAKEUP_REASON_INTERIOR_HANDLE" 4 "VCRIGHT_WAKEUP_REASON_DOOR_LATCH" 3 "VCRIGHT_WAKEUP_REASON_RESET" 2 "VCRIGHT_WAKEUP_REASON_SWITCH_INPUT" 1 "VCRIGHT_WAKEUP_REASON_ECU_SPECIFIC" 0 "VCRIGHT_WAKEUP_REASON_NONE" ;
VAL_ 1059 VCRIGHT_nmDebugWakeUp 2147483648 "WKPU_31" 1073741824 "WKPU_30" 536870912 "WKPU_29" 268435456 "WKPU_28" 134217728 "WKPU_27" 67108864 "WKPU_26" 33554432 "WKPU_25" 16777216 "WKPU_24" 8388608 "WKPU_23" 4194304 "WKPU_22" 2097152 "WKPU_21" 1048576 "WKPU_20" 524288 "WKPU_19" 262144 "WKPU_18" 131072 "WKPU_17" 65536 "WKPU_16" 32768 "WKPU_15" 16384 "WKPU_14" 8192 "WKPU_13" 4096 "WKPU_12" 2048 "WKPU_11" 1024 "WKPU_10" 512 "WKPU_9" 256 "WKPU_8" 128 "WKPU_7" 64 "WKPU_6" 32 "WKPU_5" 16 "WKPU_4" 8 "WKPU_3" 4 "WKPU_2" 2 "WKPU_1" 1 "WKPU_0" 0 "WKPU_NONE" ;
VAL_ 1059 VCRIGHT_nmEthKeepAwakeReason 15 "VCRIGHT_ETH_KEEPAWAKE_REASON_MULTIPLE" 14 "VCRIGHT_ETH_KEEPAWAKE_REASON_OTHER" 6 "VCRIGHT_ETH_KEEPAWAKE_REASON_TEMP_SENSE_COP_VARIANT_ACTIVE" 5 "VCRIGHT_ETH_KEEPAWAKE_REASON_TEMP_SENSE_POLL" 4 "VCRIGHT_ETH_KEEPAWAKE_REASON_TEMP_SENSE_VCSEC_WAKE" 3 "VCRIGHT_ETH_KEEPAWAKE_REASON_TEMP_SENSE_DWELL_TIME_END" 2 "VCRIGHT_ETH_KEEPAWAKE_REASON_TEMP_SENSE_TRANSITION_FROM_OFF" 1 "VCRIGHT_ETH_KEEPAWAKE_REASON_TEMP_SENSE_TRANSITION_FROM_ACC" 0 "VCRIGHT_ETH_KEEPAWAKE_REASON_NONE_SNA" ;
VAL_ 1059 VCRIGHT_nmChKeepAwakeReason 15 "VCRIGHT_CH_KEEPAWAKE_REASON_MULTIPLE" 14 "VCRIGHT_CH_KEEPAWAKE_REASON_OTHER" 2 "VCRIGHT_CH_KEEPAWAKE_REASON_DEFOG_CMD" 1 "VCRIGHT_CH_KEEPAWAKE_REASON_DEFOG_CAMERA" 0 "VCRIGHT_CH_KEEPAWAKE_REASON_NONE_SNA" ;
VAL_ 707 VCRIGHT_windowStatusIndex 1 "Mux1" 0 "Mux0" ;
VAL_ 707 VCRIGHT_windowStateRF 10 "WINDOW_STATE_SHORT_RISE_REVERSE" 9 "WINDOW_STATE_SHORT_RISE" 8 "WINDOW_STATE_BACKDRIVE" 7 "WINDOW_STATE_MOVING_AUTO_DOWN" 6 "WINDOW_STATE_MOVING_AUTO_UP" 5 "WINDOW_STATE_SHORT_DROP_REVERSE" 4 "WINDOW_STATE_SHORT_DROP" 3 "WINDOW_STATE_BACKOFF" 2 "WINDOW_STATE_MOVING_DOWN" 1 "WINDOW_STATE_MOVING_UP" 0 "WINDOW_STATE_STOPPED" ;
VAL_ 707 VCRIGHT_windowTrimClearMoveReque 3 "WINDOW_TRIM_CLEAR_MOVE_REQUEST_BACKDRIVE" 2 "WINDOW_TRIM_CLEAR_MOVE_REQUEST_RESEAL" 1 "WINDOW_TRIM_CLEAR_MOVE_REQUEST_IDLE" 0 "WINDOW_TRIM_CLEAR_MOVE_REQUEST_SNA" ;
VAL_ 707 VCRIGHT_windowTrimClearActiveReq 2 "WINDOW_TRIM_CLEAR_ACTIVE_REQUEST_ACTIVE" 1 "WINDOW_TRIM_CLEAR_ACTIVE_REQUEST_INACTIVE" 0 "WINDOW_TRIM_CLEAR_ACTIVE_REQUEST_SNA" ;
VAL_ 707 VCRIGHT_windowPositionRF 1 "SNA" ;
VAL_ 707 VCRIGHT_windowStateRR 10 "WINDOW_STATE_SHORT_RISE_REVERSE" 9 "WINDOW_STATE_SHORT_RISE" 8 "WINDOW_STATE_BACKDRIVE" 7 "WINDOW_STATE_MOVING_AUTO_DOWN" 6 "WINDOW_STATE_MOVING_AUTO_UP" 5 "WINDOW_STATE_SHORT_DROP_REVERSE" 4 "WINDOW_STATE_SHORT_DROP" 3 "WINDOW_STATE_BACKOFF" 2 "WINDOW_STATE_MOVING_DOWN" 1 "WINDOW_STATE_MOVING_UP" 0 "WINDOW_STATE_STOPPED" ;
VAL_ 707 VCRIGHT_windowThermalModeRF 3 "WINDOW_THERMAL_MODE_CRITICAL" 2 "WINDOW_THERMAL_MODE_ALERT" 1 "WINDOW_THERMAL_MODE_NORMAL" 0 "WINDOW_THERMAL_MODE_SNA" ;
VAL_ 707 VCRIGHT_windowStopReasonRF 6 "WINDOW_STOP_REASON_STATE_TIMEOUT" 5 "WINDOW_STOP_REASON_FULL_OPEN_SOFT_STOP" 4 "WINDOW_STOP_REASON_STOP_REQUEST" 3 "WINDOW_STOP_REASON_TARGET_REACHED" 2 "WINDOW_STOP_REASON_NEW_REQUEST" 1 "WINDOW_STOP_REASON_DOOR_OPEN_TRIM_PROTECT" 0 "WINDOW_STOP_REASON_NONE" ;
VAL_ 707 VCRIGHT_windowStopReqReasonRF 8 "WINDOW_STOP_REQUEST_REASON_EXTERNAL_REQUEST" 7 "WINDOW_STOP_REQUEST_REASON_FULL_OPEN_SOFT_STOP" 6 "WINDOW_STOP_REQUEST_REASON_STATE_TIMEOUT" 5 "WINDOW_STOP_REQUEST_REASON_STALL" 4 "WINDOW_STOP_REQUEST_REASON_THERMAL" 3 "WINDOW_STOP_REQUEST_REASON_REAR_LOCKOUT" 2 "WINDOW_STOP_REQUEST_REASON_SWITCH_RELEASED" 1 "WINDOW_STOP_REQUEST_REASON_SWITCH_CANCEL_AUTO_MOVEMENT" 0 "WINDOW_STOP_REQUEST_REASON_NONE" ;
VAL_ 707 VCRIGHT_windowThermalModeRR 3 "WINDOW_THERMAL_MODE_CRITICAL" 2 "WINDOW_THERMAL_MODE_ALERT" 1 "WINDOW_THERMAL_MODE_NORMAL" 0 "WINDOW_THERMAL_MODE_SNA" ;
VAL_ 707 VCRIGHT_windowStopReasonRR 6 "WINDOW_STOP_REASON_STATE_TIMEOUT" 5 "WINDOW_STOP_REASON_FULL_OPEN_SOFT_STOP" 4 "WINDOW_STOP_REASON_STOP_REQUEST" 3 "WINDOW_STOP_REASON_TARGET_REACHED" 2 "WINDOW_STOP_REASON_NEW_REQUEST" 1 "WINDOW_STOP_REASON_DOOR_OPEN_TRIM_PROTECT" 0 "WINDOW_STOP_REASON_NONE" ;
VAL_ 707 VCRIGHT_windowStopReqReasonRR 8 "WINDOW_STOP_REQUEST_REASON_EXTERNAL_REQUEST" 7 "WINDOW_STOP_REQUEST_REASON_FULL_OPEN_SOFT_STOP" 6 "WINDOW_STOP_REQUEST_REASON_STATE_TIMEOUT" 5 "WINDOW_STOP_REQUEST_REASON_STALL" 4 "WINDOW_STOP_REQUEST_REASON_THERMAL" 3 "WINDOW_STOP_REQUEST_REASON_REAR_LOCKOUT" 2 "WINDOW_STOP_REQUEST_REASON_SWITCH_RELEASED" 1 "WINDOW_STOP_REQUEST_REASON_SWITCH_CANCEL_AUTO_MOVEMENT" 0 "WINDOW_STOP_REQUEST_REASON_NONE" ;
VAL_ 707 VCRIGHT_windowControlStateRF 2 "WINDOW_CONTROL_STATE_GOING_TO_POSITION" 1 "WINDOW_CONTROL_STATE_CLOSING" 0 "WINDOW_CONTROL_STATE_IDLE" ;
VAL_ 707 VCRIGHT_windowCtrlUnavailableRF 7 "WINDOW_CONTROL_UNAVAILABLE_REASON_WINDOW_MOVING" 6 "WINDOW_CONTROL_UNAVAILABLE_REASON_VEHICLE_IN_DRIVE" 5 "WINDOW_CONTROL_UNAVAILABLE_REASON_UNCALIBRATED" 4 "WINDOW_CONTROL_UNAVAILABLE_REASON_THERMAL_LIMIT" 3 "WINDOW_CONTROL_UNAVAILABLE_REASON_PINCH" 2 "WINDOW_CONTROL_UNAVAILABLE_REASON_SWITCH_PRESSED" 1 "WINDOW_CONTROL_UNAVAILABLE_REASON_UNEXPECTED" 0 "WINDOW_CONTROL_UNAVAILABLE_REASON_NONE" ;
VAL_ 707 VCRIGHT_windowControlStateRR 2 "WINDOW_CONTROL_STATE_GOING_TO_POSITION" 1 "WINDOW_CONTROL_STATE_CLOSING" 0 "WINDOW_CONTROL_STATE_IDLE" ;
VAL_ 707 VCRIGHT_windowCtrlUnavailableRR 7 "WINDOW_CONTROL_UNAVAILABLE_REASON_WINDOW_MOVING" 6 "WINDOW_CONTROL_UNAVAILABLE_REASON_VEHICLE_IN_DRIVE" 5 "WINDOW_CONTROL_UNAVAILABLE_REASON_UNCALIBRATED" 4 "WINDOW_CONTROL_UNAVAILABLE_REASON_THERMAL_LIMIT" 3 "WINDOW_CONTROL_UNAVAILABLE_REASON_PINCH" 2 "WINDOW_CONTROL_UNAVAILABLE_REASON_SWITCH_PRESSED" 1 "WINDOW_CONTROL_UNAVAILABLE_REASON_UNEXPECTED" 0 "WINDOW_CONTROL_UNAVAILABLE_REASON_NONE" ;
VAL_ 707 VCRIGHT_windowPositionStateRF 7 "WINDOW_POSITION_CLOSED_TRIM_CLEAR" 6 "WINDOW_POSITION_FULL_OPEN" 5 "WINDOW_POSITION_PARTIAL_OPEN" 4 "WINDOW_POSITION_DAS_LIMITED" 3 "WINDOW_POSITION_VENT" 2 "WINDOW_POSITION_CRACKED" 1 "WINDOW_POSITION_CLOSED" 0 "WINDOW_POSITION_UNKNOWN" ;
VAL_ 707 VCRIGHT_windowPositionStateRR 7 "WINDOW_POSITION_CLOSED_TRIM_CLEAR" 6 "WINDOW_POSITION_FULL_OPEN" 5 "WINDOW_POSITION_PARTIAL_OPEN" 4 "WINDOW_POSITION_DAS_LIMITED" 3 "WINDOW_POSITION_VENT" 2 "WINDOW_POSITION_CRACKED" 1 "WINDOW_POSITION_CLOSED" 0 "WINDOW_POSITION_UNKNOWN" ;
VAL_ 707 VCRIGHT_windowVehGearStateRF 2 "WINDOW_VEHICLE_GEAR_STATE_IN_GEAR" 1 "WINDOW_VEHICLE_GEAR_STATE_PARK" 0 "WINDOW_VEHICLE_GEAR_STATE_UNKNOWN_SNA" ;
VAL_ 707 VCRIGHT_windowVehGearStateRR 2 "WINDOW_VEHICLE_GEAR_STATE_IN_GEAR" 1 "WINDOW_VEHICLE_GEAR_STATE_PARK" 0 "WINDOW_VEHICLE_GEAR_STATE_UNKNOWN_SNA" ;
VAL_ 707 VCRIGHT_windowSpeedTableStatusRF 2 "WINDOW_SPEED_TABLE_STATUS_FULLY_BUILT" 1 "WINDOW_SPEED_TABLE_STATUS_SENSITIVE_BUILT" 0 "WINDOW_SPEED_TABLE_STATUS_EMPTY_SNA" ;
VAL_ 707 VCRIGHT_windowSpeedTableStatusRR 2 "WINDOW_SPEED_TABLE_STATUS_FULLY_BUILT" 1 "WINDOW_SPEED_TABLE_STATUS_SENSITIVE_BUILT" 0 "WINDOW_SPEED_TABLE_STATUS_EMPTY_SNA" ;
VAL_ 1375 VCSEAT2L_alertID 571 "a571_seatHeatDisabledRear" 550 "a550_ambientTempDelta" 526 "a526_pcbaOverTemperature" 445 "a445_drv8703SpiFaultDBG" 444 "a444_drv8703Fault" 429 "a429_seatAbuseBufferFull" 428 "a428_seatAbuseBufferWarn" 427 "a427_seatAbuseMotorStop" 426 "a426_seatAbuseMotorWarn" 291 "a291_buckleFaultedRow2" 290 "a290_occupancyFaultRow2" 280 "a280_seatStatsFromLastStateDbg2" 279 "a279_seatOverfolded" 278 "a278_seatClashAvoidanceBlocked" 277 "a277_seatRequestWhileUncalibrated" 276 "a276_seatStatsFromLastStateDbg" 275 "a275_seatAbsPosSensorTransitionDbg" 274 "a274_seatTempHigh" 273 "a273_seatObstacleDetected" 272 "a272_seatAbsPosOffsetApplied" 271 "a271_seatPositionNonsensical" 270 "a270_seatUncalibrated" 268 "a268_seatBackHCEncStlDbg" 267 "a267_seatTrackHCEncStl" 264 "a264_seatBackStallDebug" 263 "a263_seatTrackStallDebug" 261 "a261_seatArmrestObstacleDetected" 260 "a260_seatTrackObstacleDetected" 252 "a252_seatUncalBack" 251 "a251_seatUncalTrack" 245 "a245_seatArmrestEcuLogStatus" 244 "a244_seatArmrestSpeedTableReferenceStatus" 243 "a243_seatArmrestHistoryScoreDbg" 242 "a242_seatHeatTmpRow2" 241 "a241_seatArmrestHistoryScore" 240 "a240_seatHeatShortRow2" 239 "a239_seatHeatIRow2" 238 "a238_seatArmrestInhibitedByBackrest" 237 "a237_seatArmrestStatsFromLastStateDbg2" 236 "a236_seatArmrestStatsFromLastStateDbg" 235 "a235_seatTrackStatsFromLastStateDbg2" 234 "a234_seatTrackStatsFromLastStateDbg" 233 "a233_seatCurrUnderBack" 232 "a232_seatCurrUnderTrack" 229 "a229_seatEncOverBack" 228 "a228_seatEncOverTrack" 225 "a225_seatEncStallBack" 224 "a224_seatEncStallTrack" 219 "a219_motorCurrentDropout" 218 "a218_motorDriverFault" 215 "a215_armrestHCEncStlDbg" 214 "a214_armrestStallDebug" 213 "a213_armrestEncOver" 212 "a212_armrestUncal" 211 "a211_armrestCurrUnder" 210 "a210_armrestEncStall" 201 "a201_motorDutyEncDisabl" 200 "a200_motorPhantomEncoder" 191 "a191_seatChoreographyIsBlockedBySecondSeat" 190 "a190_seatChoreographyIsBlockedByFrontSeat" 120 "a120_DI_DRIVE_MIA" 119 "a119_SCCM_MIA" 118 "a118_VCFRONT_MIA" 117 "a117_VCLEFT_MIA" 116 "a116_VCRIGHT_MIA" 115 "a115_VCSEC_MIA" 114 "a114_ESP_MIA" 113 "a113_UI_MIA" 112 "a112_EPBL_MIA" 111 "a111_EPBR_MIA" 110 "a110_GTW_MIA" 109 "a109_RCM_MIA" 108 "a108_DIF_MIA" 107 "a107_BMS_MIA" 106 "a106_PCS_MIA" 105 "a105_TAS_MIA" 104 "a104_DAS_MIA" 103 "a103_CP_MIA" 102 "a102_PTC_MIA" 101 "a101_PM_MIA" 100 "a100_CANbus_MIA" 99 "a099_PARK_MIA" 98 "a098_DIR_MIA" 97 "a097_CMP_MIA" 96 "a096_OCS1P_MIA" 95 "a095_CHG_MIA" 94 "a094_EPAS3P_MIA" 93 "a093_VCSEATP_MIA" 92 "a092_VCSEATD_MIA" 91 "a091_CMPD_MIA" 90 "a090_APS_MIA" 89 "a089_IBST_MIA" 88 "a088_DIRER_MIA" 87 "a087_DIREL_MIA" 86 "a086_VCBATT_MIA" 85 "a085_CCCM_MIA" 84 "a084_TPMS_MIA" 83 "a083_VCLEFT_IPC_MIA" 82 "a082_VCRIGHT_IPC_MIA" 64 "a064_busSleepReqTimeout" 63 "a063_SwitchFault" 62 "a062_XCPWasConnected" 61 "a061_XCPConnected" 60 "a060_engineeringBuild" 59 "a059_inputResistanceHigh" 58 "a058_inputRHighSyncDebug" 57 "a057_HVP_MIA" 46 "a046_Task1000msError" 45 "a045_Task100msError" 44 "a044_Task10msError" 43 "a043_Task1msError" 42 "a042_HighStackUsage" 41 "a041_HighCPULoad" 31 "a031_UDSActive" 30 "a030_ECULogUploadRequest" 29 "a029_CoreDump" 22 "a022_TaskInitError" 21 "a021_TaskSchedulerError" 16 "a016_NVMMRecordError" 15 "a015_NVMMError" 13 "a013_AlertManagerFault" 12 "a012_CPUReset" 10 "a010_ExtSupplyVoltError" 6 "a006_CANTX_cyclicError" 5 "a005_CANTXError" 3 "a003_SWAssertion" 2 "a002_PowerLossReset" 1 "a001_WatchdogReset" 0 "ALERT_DO_NOT_USE_ZERO" ;
VAL_ 1375 VCSEAT2L_alertState 1 "SET" 0 "CLEARED" ;
VAL_ 1375 VCSEAT2L_a210_seatMotorState 5 "UNDEFINED" 4 "CALIBRATING" 3 "RECALLING" 2 "MOVING_DOWN" 1 "MOVING_UP" 0 "STOPPED" ;
VAL_ 1375 VCSEAT2L_a210_seatSwitchBack 3 "FAULT" 2 "ON" 1 "OFF" 0 "SNA" ;
VAL_ 1375 VCSEAT2L_a210_seatSwitchForward 3 "FAULT" 2 "ON" 1 "OFF" 0 "SNA" ;
VAL_ 1375 VCSEAT2L_a211_seatMotorState 5 "UNDEFINED" 4 "CALIBRATING" 3 "RECALLING" 2 "MOVING_DOWN" 1 "MOVING_UP" 0 "STOPPED" ;
VAL_ 1375 VCSEAT2L_a211_seatSwitchBack 3 "FAULT" 2 "ON" 1 "OFF" 0 "SNA" ;
VAL_ 1375 VCSEAT2L_a211_seatSwitchForward 3 "FAULT" 2 "ON" 1 "OFF" 0 "SNA" ;
VAL_ 1375 VCSEAT2L_a212_seatMotorState 5 "UNDEFINED" 4 "CALIBRATING" 3 "RECALLING" 2 "MOVING_DOWN" 1 "MOVING_UP" 0 "STOPPED" ;
VAL_ 1375 VCSEAT2L_a212_seatSwitchBack 3 "FAULT" 2 "ON" 1 "OFF" 0 "SNA" ;
VAL_ 1375 VCSEAT2L_a212_seatSwitchForward 3 "FAULT" 2 "ON" 1 "OFF" 0 "SNA" ;
VAL_ 1375 VCSEAT2L_a213_seatMotorState 5 "UNDEFINED" 4 "CALIBRATING" 3 "RECALLING" 2 "MOVING_DOWN" 1 "MOVING_UP" 0 "STOPPED" ;
VAL_ 1375 VCSEAT2L_a213_seatSwitchBack 3 "FAULT" 2 "ON" 1 "OFF" 0 "SNA" ;
VAL_ 1375 VCSEAT2L_a213_seatSwitchForward 3 "FAULT" 2 "ON" 1 "OFF" 0 "SNA" ;
VAL_ 1375 VCSEAT2L_a214_seatMotorState 5 "UNDEFINED" 4 "CALIBRATING" 3 "RECALLING" 2 "MOVING_DOWN" 1 "MOVING_UP" 0 "STOPPED" ;
VAL_ 1375 VCSEAT2L_a215_seatMotorState 5 "UNDEFINED" 4 "CALIBRATING" 3 "RECALLING" 2 "MOVING_DOWN" 1 "MOVING_UP" 0 "STOPPED" ;
VAL_ 1375 VCSEAT2L_a224_seatMotorState 5 "UNDEFINED" 4 "CALIBRATING" 3 "RECALLING" 2 "MOVING_DOWN" 1 "MOVING_UP" 0 "STOPPED" ;
VAL_ 1375 VCSEAT2L_a224_seatSwitchBack 3 "FAULT" 2 "ON" 1 "OFF" 0 "SNA" ;
VAL_ 1375 VCSEAT2L_a224_seatSwitchForward 3 "FAULT" 2 "ON" 1 "OFF" 0 "SNA" ;
VAL_ 1375 VCSEAT2L_a225_seatMotorState 5 "UNDEFINED" 4 "CALIBRATING" 3 "RECALLING" 2 "MOVING_DOWN" 1 "MOVING_UP" 0 "STOPPED" ;
VAL_ 1375 VCSEAT2L_a225_seatSwitchBack 3 "FAULT" 2 "ON" 1 "OFF" 0 "SNA" ;
VAL_ 1375 VCSEAT2L_a225_seatSwitchForward 3 "FAULT" 2 "ON" 1 "OFF" 0 "SNA" ;
VAL_ 1375 VCSEAT2L_a228_seatMotorState 5 "UNDEFINED" 4 "CALIBRATING" 3 "RECALLING" 2 "MOVING_DOWN" 1 "MOVING_UP" 0 "STOPPED" ;
VAL_ 1375 VCSEAT2L_a228_seatSwitchBack 3 "FAULT" 2 "ON" 1 "OFF" 0 "SNA" ;
VAL_ 1375 VCSEAT2L_a228_seatSwitchForward 3 "FAULT" 2 "ON" 1 "OFF" 0 "SNA" ;
VAL_ 1375 VCSEAT2L_a229_seatMotorState 5 "UNDEFINED" 4 "CALIBRATING" 3 "RECALLING" 2 "MOVING_DOWN" 1 "MOVING_UP" 0 "STOPPED" ;
VAL_ 1375 VCSEAT2L_a229_seatSwitchBack 3 "FAULT" 2 "ON" 1 "OFF" 0 "SNA" ;
VAL_ 1375 VCSEAT2L_a229_seatSwitchForward 3 "FAULT" 2 "ON" 1 "OFF" 0 "SNA" ;
VAL_ 1375 VCSEAT2L_a232_seatMotorState 5 "UNDEFINED" 4 "CALIBRATING" 3 "RECALLING" 2 "MOVING_DOWN" 1 "MOVING_UP" 0 "STOPPED" ;
VAL_ 1375 VCSEAT2L_a232_seatSwitchBack 3 "FAULT" 2 "ON" 1 "OFF" 0 "SNA" ;
VAL_ 1375 VCSEAT2L_a232_seatSwitchForward 3 "FAULT" 2 "ON" 1 "OFF" 0 "SNA" ;
VAL_ 1375 VCSEAT2L_a233_seatMotorState 5 "UNDEFINED" 4 "CALIBRATING" 3 "RECALLING" 2 "MOVING_DOWN" 1 "MOVING_UP" 0 "STOPPED" ;
VAL_ 1375 VCSEAT2L_a233_seatSwitchBack 3 "FAULT" 2 "ON" 1 "OFF" 0 "SNA" ;
VAL_ 1375 VCSEAT2L_a233_seatSwitchForward 3 "FAULT" 2 "ON" 1 "OFF" 0 "SNA" ;
VAL_ 1375 VCSEAT2L_a251_seatMotorState 5 "UNDEFINED" 4 "CALIBRATING" 3 "RECALLING" 2 "MOVING_DOWN" 1 "MOVING_UP" 0 "STOPPED" ;
VAL_ 1375 VCSEAT2L_a251_seatSwitchBack 3 "FAULT" 2 "ON" 1 "OFF" 0 "SNA" ;
VAL_ 1375 VCSEAT2L_a251_seatSwitchForward 3 "FAULT" 2 "ON" 1 "OFF" 0 "SNA" ;
VAL_ 1375 VCSEAT2L_a252_seatMotorState 5 "UNDEFINED" 4 "CALIBRATING" 3 "RECALLING" 2 "MOVING_DOWN" 1 "MOVING_UP" 0 "STOPPED" ;
VAL_ 1375 VCSEAT2L_a252_seatSwitchBack 3 "FAULT" 2 "ON" 1 "OFF" 0 "SNA" ;
VAL_ 1375 VCSEAT2L_a252_seatSwitchForward 3 "FAULT" 2 "ON" 1 "OFF" 0 "SNA" ;
VAL_ 1375 VCSEAT2L_a260_seatStatePrev 5 "UNDEFINED" 4 "CALIBRATING" 3 "RECALLING" 2 "MOVING_DOWN" 1 "MOVING_UP" 0 "STOPPED" ;
VAL_ 1375 VCSEAT2L_a260_obstacleDetectReas 6 "HISTORY_BASED" 5 "SENSITIVE_CURRENT" 4 "ACCEL_LOOKBACK_ABS" 3 "MAX_SPEED_DIFF" 2 "SPEED_THRESHOLD" 1 "STALL_DETECTED" 0 "NONE" ;
VAL_ 1375 VCSEAT2L_a261_seatStatePrev 5 "UNDEFINED" 4 "CALIBRATING" 3 "RECALLING" 2 "MOVING_DOWN" 1 "MOVING_UP" 0 "STOPPED" ;
VAL_ 1375 VCSEAT2L_a261_obstacleDetectReas 6 "HISTORY_BASED" 5 "SENSITIVE_CURRENT" 4 "ACCEL_LOOKBACK_ABS" 3 "MAX_SPEED_DIFF" 2 "SPEED_THRESHOLD" 1 "STALL_DETECTED" 0 "NONE" ;
VAL_ 1375 VCSEAT2L_a263_seatMotorState 5 "UNDEFINED" 4 "CALIBRATING" 3 "RECALLING" 2 "MOVING_DOWN" 1 "MOVING_UP" 0 "STOPPED" ;
VAL_ 1375 VCSEAT2L_a264_seatMotorState 5 "UNDEFINED" 4 "CALIBRATING" 3 "RECALLING" 2 "MOVING_DOWN" 1 "MOVING_UP" 0 "STOPPED" ;
VAL_ 1375 VCSEAT2L_a267_seatMotorState 5 "UNDEFINED" 4 "CALIBRATING" 3 "RECALLING" 2 "MOVING_DOWN" 1 "MOVING_UP" 0 "STOPPED" ;
VAL_ 1375 VCSEAT2L_a268_seatMotorState 5 "UNDEFINED" 4 "CALIBRATING" 3 "RECALLING" 2 "MOVING_DOWN" 1 "MOVING_UP" 0 "STOPPED" ;
VAL_ 1375 VCSEAT2L_a270_seatState 15 "SNA" 12 "CALIBRATING_ABSOLUTE_SENSOR" 11 "CALIBRATING_ZERO_POSITION" 10 "WAITING_TO_CLEAR_FOR_UNFOLD" 9 "WAITING_TO_CLEAR_FOR_FOLD" 8 "MOVING_REARWARD_TO_POSITION" 7 "MOVING_FORWARD_TO_POSITION" 6 "UNFOLDING" 5 "FOLDING" 4 "ADJUSTING_REARWARD_FAST" 3 "ADJUSTING_FORWARD_FAST" 2 "ADJUSTING_REARWARD_COMFORT" 1 "ADJUSTING_FORWARD_COMFORT" 0 "STOPPED" ;
VAL_ 1375 VCSEAT2L_a270_motorType 1 "KEIPER" 0 "SHB_OR_UNKNOWN" ;
VAL_ 1375 VCSEAT2L_a270_absPosSensState 3 "DISCONNECTED" 2 "FORWARD" 1 "REARWARD" 0 "FAULTED" ;
VAL_ 1375 VCSEAT2L_a273_seatStatePrev 15 "SNA" 12 "CALIBRATING_ABSOLUTE_SENSOR" 11 "CALIBRATING_ZERO_POSITION" 10 "WAITING_TO_CLEAR_FOR_UNFOLD" 9 "WAITING_TO_CLEAR_FOR_FOLD" 8 "MOVING_REARWARD_TO_POSITION" 7 "MOVING_FORWARD_TO_POSITION" 6 "UNFOLDING" 5 "FOLDING" 4 "ADJUSTING_REARWARD_FAST" 3 "ADJUSTING_FORWARD_FAST" 2 "ADJUSTING_REARWARD_COMFORT" 1 "ADJUSTING_FORWARD_COMFORT" 0 "STOPPED" ;
VAL_ 1375 VCSEAT2L_a273_obstacleDetectReas 8 "MAX_SPEED_DIFF" 7 "SPEED_THRESHOLD" 6 "MEDIUM_CURRENT_THRESHOLD" 5 "ACCEL_LOOKBACK_COMP_ABS" 4 "ACCEL_LOOKBACK_UNCOMP_REL" 3 "ACCEL_LOOKBACK_UNCOMP_ABS" 2 "MOTOR_ENCODER_STALL" 1 "MOTOR_CURRENT_STALL" 0 "NONE" ;
VAL_ 1375 VCSEAT2L_a273_motorType 1 "KEIPER" 0 "SHB_OR_UNKNOWN" ;
VAL_ 1375 VCSEAT2L_a278_seatState 15 "SNA" 12 "CALIBRATING_ABSOLUTE_SENSOR" 11 "CALIBRATING_ZERO_POSITION" 10 "WAITING_TO_CLEAR_FOR_UNFOLD" 9 "WAITING_TO_CLEAR_FOR_FOLD" 8 "MOVING_REARWARD_TO_POSITION" 7 "MOVING_FORWARD_TO_POSITION" 6 "UNFOLDING" 5 "FOLDING" 4 "ADJUSTING_REARWARD_FAST" 3 "ADJUSTING_FORWARD_FAST" 2 "ADJUSTING_REARWARD_COMFORT" 1 "ADJUSTING_FORWARD_COMFORT" 0 "STOPPED" ;
VAL_ 1375 VCSEAT2L_a426_seatMotorState 5 "UNDEFINED" 4 "CALIBRATING" 3 "RECALLING" 2 "MOVING_DOWN" 1 "MOVING_UP" 0 "STOPPED" ;
VAL_ 1375 VCSEAT2L_a426_seatSwitchBack 3 "FAULT" 2 "ON" 1 "OFF" 0 "SNA" ;
VAL_ 1375 VCSEAT2L_a426_seatSwitchForward 3 "FAULT" 2 "ON" 1 "OFF" 0 "SNA" ;
VAL_ 1375 VCSEAT2L_a427_seatMotorState 5 "UNDEFINED" 4 "CALIBRATING" 3 "RECALLING" 2 "MOVING_DOWN" 1 "MOVING_UP" 0 "STOPPED" ;
VAL_ 1375 VCSEAT2L_a427_seatSwitchBack 3 "FAULT" 2 "ON" 1 "OFF" 0 "SNA" ;
VAL_ 1375 VCSEAT2L_a427_seatSwitchForward 3 "FAULT" 2 "ON" 1 "OFF" 0 "SNA" ;
VAL_ 1375 VCSEAT2L_a428_seatMotorState 5 "UNDEFINED" 4 "CALIBRATING" 3 "RECALLING" 2 "MOVING_DOWN" 1 "MOVING_UP" 0 "STOPPED" ;
VAL_ 1375 VCSEAT2L_a428_seatSwitchBack 3 "FAULT" 2 "ON" 1 "OFF" 0 "SNA" ;
VAL_ 1375 VCSEAT2L_a428_seatSwitchForward 3 "FAULT" 2 "ON" 1 "OFF" 0 "SNA" ;
VAL_ 1375 VCSEAT2L_a429_seatMotorState 5 "UNDEFINED" 4 "CALIBRATING" 3 "RECALLING" 2 "MOVING_DOWN" 1 "MOVING_UP" 0 "STOPPED" ;
VAL_ 1375 VCSEAT2L_a429_seatSwitchBack 3 "FAULT" 2 "ON" 1 "OFF" 0 "SNA" ;
VAL_ 1375 VCSEAT2L_a429_seatSwitchForward 3 "FAULT" 2 "ON" 1 "OFF" 0 "SNA" ;
VAL_ 892 VCSEAT2L_matrixIndex 9 "AlertMatrix9" 8 "AlertMatrix8" 7 "AlertMatrix7" 4 "AlertMatrix4" 3 "AlertMatrix3" 1 "AlertMatrix1" 0 "AlertMatrix0" ;
VAL_ 764 VCSEAT2L_row2SeatStatusIndex 3 "ARMREST" 2 "ADJUSTABLE_FOLD_FLAT" 1 "POSITION" 0 "TRACK" ;
VAL_ 764 VCSEAT2L_seatReclineState 15 "SEAT_ADJUSTABLE_FOLD_FLAT_STATE_SNA" 12 "SEAT_ADJUSTABLE_FOLD_FLAT_STATE_CALIBRATING_ABSOLUTE_SENSOR" 11 "SEAT_ADJUSTABLE_FOLD_FLAT_STATE_CALIBRATING_ZERO_POSITION" 10 "SEAT_ADJUSTABLE_FOLD_FLAT_STATE_WAITING_TO_CLEAR_FOR_UNFOLD" 9 "SEAT_ADJUSTABLE_FOLD_FLAT_STATE_WAITING_TO_CLEAR_FOR_FOLD" 8 "SEAT_ADJUSTABLE_FOLD_FLAT_STATE_MOVING_REARWARD_TO_POSITION" 7 "SEAT_ADJUSTABLE_FOLD_FLAT_STATE_MOVING_FORWARD_TO_POSITION" 6 "SEAT_ADJUSTABLE_FOLD_FLAT_STATE_UNFOLDING" 5 "SEAT_ADJUSTABLE_FOLD_FLAT_STATE_FOLDING" 4 "SEAT_ADJUSTABLE_FOLD_FLAT_STATE_ADJUSTING_REARWARD_FAST" 3 "SEAT_ADJUSTABLE_FOLD_FLAT_STATE_ADJUSTING_FORWARD_FAST" 2 "SEAT_ADJUSTABLE_FOLD_FLAT_STATE_ADJUSTING_REARWARD_COMFORT" 1 "SEAT_ADJUSTABLE_FOLD_FLAT_STATE_ADJUSTING_FORWARD_COMFORT" 0 "SEAT_ADJUSTABLE_FOLD_FLAT_STATE_STOPPED" ;
VAL_ 764 VCSEAT2L_seatReclinePositionStat 4 "SEAT_ADJUSTABLE_FOLD_FLAT_POSITION_STATE_SNA" 3 "SEAT_ADJUSTABLE_FOLD_FLAT_POSITION_STATE_UNKNOWN" 2 "SEAT_ADJUSTABLE_FOLD_FLAT_POSITION_STATE_UNSAFE_INTERMEDIATE" 1 "SEAT_ADJUSTABLE_FOLD_FLAT_POSITION_STATE_UNFOLDED" 0 "SEAT_ADJUSTABLE_FOLD_FLAT_POSITION_STATE_FOLDED" ;
VAL_ 764 VCSEAT2L_seatReclineAbsPosSwitch 3 "SWITCH_FAULT" 2 "SWITCH_ON" 1 "SWITCH_OFF" 0 "SWITCH_SNA" ;
VAL_ 764 VCSEAT2L_seat1RClashAvoidanceBlo 6 "SEAT_FOLD_FLAT_CLASH_AVOIDANCE_REASON_FRONT_SEAT_OCCUPANCY" 5 "SEAT_FOLD_FLAT_CLASH_AVOIDANCE_REASON_FRONT_SEAT_MOVING" 4 "SEAT_FOLD_FLAT_CLASH_AVOIDANCE_REASON_FRONT_SEAT_PROFILE_RECALL" 3 "SEAT_FOLD_FLAT_CLASH_AVOIDANCE_REASON_REAR_SEAT_UNCALIBRATED" 2 "SEAT_FOLD_FLAT_CLASH_AVOIDANCE_REASON_FRONT_SEAT_UNCALIBRATED" 1 "SEAT_FOLD_FLAT_CLASH_AVOIDANCE_REASON_VEHICLE_IN_MOTION" 0 "SEAT_FOLD_FLAT_CLASH_AVOIDANCE_REASON_NONE" ;
VAL_ 764 VCSEAT2L_seat1RClashAvoidanceSta 3 "SEAT_FOLD_FLAT_CLASH_AVOIDANCE_STATE_RESTORING_FRONT_SEAT" 2 "SEAT_FOLD_FLAT_CLASH_AVOIDANCE_STATE_WAITING_TO_RESTORE_FRONT_SEAT" 1 "SEAT_FOLD_FLAT_CLASH_AVOIDANCE_STATE_FRONT_SEAT_CLEARING" 0 "SEAT_FOLD_FLAT_CLASH_AVOIDANCE_STATE_IDLE" ;
VAL_ 764 VCSEAT2L_seatReclineNextToggleDi 2 "SEAT_ADJUSTABLE_FOLD_FLAT_NEXT_TOGGLE_DIRECTION_SNA" 1 "SEAT_ADJUSTABLE_FOLD_FLAT_NEXT_TOGGLE_DIRECTION_UNFOLD" 0 "SEAT_ADJUSTABLE_FOLD_FLAT_NEXT_TOGGLE_DIRECTION_FOLD" ;
VAL_ 1986 VCSEAT2L_seatStatus2Index 5 "LOADSHED" 4 "CHOREOGRAPHY" 3 "VENTILATION" 2 "OCCUPANCY" 1 "SEAT_VOLTAGES" 0 "SEAT_HEAT_FRONT" ;
VAL_ 1986 VCSEAT2L_choreography2RState 2 "SEAT_CHOREOGRAPHY_ROW_STATE_UNFOLDING" 1 "SEAT_CHOREOGRAPHY_ROW_STATE_FOLDING" 0 "SEAT_CHOREOGRAPHY_ROW_STATE_IDLE" ;
VAL_ 1986 VCSEAT2L_choreography3RState 2 "SEAT_CHOREOGRAPHY_ROW_STATE_UNFOLDING" 1 "SEAT_CHOREOGRAPHY_ROW_STATE_FOLDING" 0 "SEAT_CHOREOGRAPHY_ROW_STATE_IDLE" ;
VAL_ 1986 VCSEAT2L_choreography1RTrackVelo 6 "SEAT_MOTOR_VELOCITY_TYPE_HIGH_BACKWARD" 5 "SEAT_MOTOR_VELOCITY_TYPE_HIGH_FORWARD" 4 "SEAT_MOTOR_VELOCITY_TYPE_MID_BACKWARD" 3 "SEAT_MOTOR_VELOCITY_TYPE_MID_FORWARD" 2 "SEAT_MOTOR_VELOCITY_TYPE_LOW_BACKWARD" 1 "SEAT_MOTOR_VELOCITY_TYPE_LOW_FORWARD" 0 "SEAT_MOTOR_VELOCITY_TYPE_STOP" ;
VAL_ 1986 VCSEAT2L_choreography1RBackrestV 6 "SEAT_MOTOR_VELOCITY_TYPE_HIGH_BACKWARD" 5 "SEAT_MOTOR_VELOCITY_TYPE_HIGH_FORWARD" 4 "SEAT_MOTOR_VELOCITY_TYPE_MID_BACKWARD" 3 "SEAT_MOTOR_VELOCITY_TYPE_MID_FORWARD" 2 "SEAT_MOTOR_VELOCITY_TYPE_LOW_BACKWARD" 1 "SEAT_MOTOR_VELOCITY_TYPE_LOW_FORWARD" 0 "SEAT_MOTOR_VELOCITY_TYPE_STOP" ;
VAL_ 1986 VCSEAT2L_choreography2RTrackVelo 6 "SEAT_MOTOR_VELOCITY_TYPE_HIGH_BACKWARD" 5 "SEAT_MOTOR_VELOCITY_TYPE_HIGH_FORWARD" 4 "SEAT_MOTOR_VELOCITY_TYPE_MID_BACKWARD" 3 "SEAT_MOTOR_VELOCITY_TYPE_MID_FORWARD" 2 "SEAT_MOTOR_VELOCITY_TYPE_LOW_BACKWARD" 1 "SEAT_MOTOR_VELOCITY_TYPE_LOW_FORWARD" 0 "SEAT_MOTOR_VELOCITY_TYPE_STOP" ;
VAL_ 1986 VCSEAT2L_choreography2RBackrestV 6 "SEAT_MOTOR_VELOCITY_TYPE_HIGH_BACKWARD" 5 "SEAT_MOTOR_VELOCITY_TYPE_HIGH_FORWARD" 4 "SEAT_MOTOR_VELOCITY_TYPE_MID_BACKWARD" 3 "SEAT_MOTOR_VELOCITY_TYPE_MID_FORWARD" 2 "SEAT_MOTOR_VELOCITY_TYPE_LOW_BACKWARD" 1 "SEAT_MOTOR_VELOCITY_TYPE_LOW_FORWARD" 0 "SEAT_MOTOR_VELOCITY_TYPE_STOP" ;
VAL_ 1986 VCSEAT2L_choreography3RBackrestV 6 "SEAT_MOTOR_VELOCITY_TYPE_HIGH_BACKWARD" 5 "SEAT_MOTOR_VELOCITY_TYPE_HIGH_FORWARD" 4 "SEAT_MOTOR_VELOCITY_TYPE_MID_BACKWARD" 3 "SEAT_MOTOR_VELOCITY_TYPE_MID_FORWARD" 2 "SEAT_MOTOR_VELOCITY_TYPE_LOW_BACKWARD" 1 "SEAT_MOTOR_VELOCITY_TYPE_LOW_FORWARD" 0 "SEAT_MOTOR_VELOCITY_TYPE_STOP" ;
VAL_ 1986 VCSEAT2L_choreographyState 10 "SEAT_CHOREO_STATE_1R_RESTORE" 9 "SEAT_CHOREO_STATE_1R_CLEAR_2R_MID_OUT_OF_KEEPOUT_ZONE_3R_MID" 8 "SEAT_CHOREO_STATE_1R_CLEAR_2R_FAST_OUT_OF_KEEPOUT_ZONE_3R_MID" 7 "SEAT_CHOREO_STATE_1R_STOP_2R_FAST_OUT_OF_KEEPOUT_ZONE_3R_MID" 6 "SEAT_CHOREO_STATE_1R_STOP_2R_FAST_OUT_OF_KEEPOUT_ZONE_3R_FAST" 5 "SEAT_CHOREO_STATE_2R_STOP_3R_FAST" 4 "SEAT_CHOREO_STATE_1R_CLEAR_2R_STOP_OUT_OF_KEEPOUT_ZONE" 3 "SEAT_CHOREO_STATE_1R_CLEAR_2R_MID_OUT_OF_KEEPOUT_ZONE" 2 "SEAT_CHOREO_STATE_1R_CLEAR_2R_FAST_OUT_OF_KEEPOUT_ZONE" 1 "SEAT_CHOREO_STATE_1R_STOP_2R_FAST_OUT_OF_KEEPOUT_ZONE" 0 "SEAT_CHOREO_STATE_INVALID" ;
VAL_ 1986 VCSEAT2L_choreographyCollisionPa 4 "SEAT_CHOREOGRAPHY_COLLISION_PAIR_2R_BACKREST_3R_BACKREST" 3 "SEAT_CHOREOGRAPHY_COLLISION_PAIR_2R_CUSHION_3R_BACKREST" 2 "SEAT_CHOREOGRAPHY_COLLISION_PAIR_1R_BACKREST_2R_BACKREST" 1 "SEAT_CHOREOGRAPHY_COLLISION_PAIR_1R_BACKREST_2R_CUSHION" 0 "SEAT_CHOREOGRAPHY_COLLISION_PAIR_NONE" ;
